VERSION ""
BS_:
BU_:

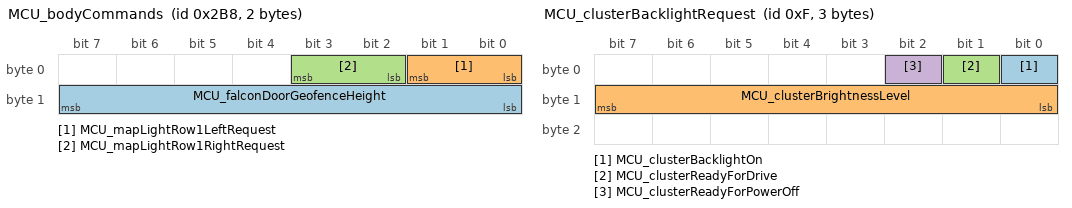
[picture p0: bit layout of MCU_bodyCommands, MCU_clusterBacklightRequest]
BO_ 696 MCU_bodyCommands: 2 ETH
 SG_ MCU_falconDoorGeofenceHeight: 8|8@1+ (1,0) [0|0] "cm" X
 SG_ MCU_mapLightRow1LeftRequest: 0|2@1+ (1,0) [0|0] "" X
 SG_ MCU_mapLightRow1RightRequest: 2|2@1+ (1,0) [0|0] "" X

BO_ 7 MCU_bodyControl: 8 ETH
 SG_ GTW_keyPollRequest: 44|1@1+ (1,0) [0|0] "" X
 SG_ GTW_parkingBrakesApplied: 0|1@1+ (1,0) [0|0] "" X
 SG_ MCU_UMCUpdateInhibit: 47|1@1+ (1,0) [0|0] "" X
 SG_ MCU_WCUpdateInhibit: 48|1@1+ (1,0) [0|0] "" X
 SG_ MCU_carInService: 12|1@1+ (1,0) [0|0] "" X
 SG_ MCU_chargeTerminationPct: 32|10@1+ (0.1,0) [0|0] "%" X
 SG_ MCU_chgMode: 18|3@1+ (1,0) [0|0] "" X
 SG_ MCU_clearDtcs: 13|1@1+ (1,0) [0|0] "" X
 SG_ MCU_domeLightReq: 16|2@1+ (1,0) [0|0] "" X
 SG_ MCU_espModeSwitch: 28|4@1+ (1,0) [0|0] "" X
 SG_ MCU_factoryMode: 5|1@1+ (1,0) [0|0] "" X
 SG_ MCU_frontFogSwitch: 6|1@1+ (1,0) [0|0] "" X
 SG_ MCU_lightSwitch: 2|2@1+ (1,0) [0|0] "" X
 SG_ MCU_pedalCalRxEnable: 15|1@1+ (1,0) [0|0] "" X
 SG_ MCU_pedalCalTargetCurve: 24|4@1+ (1,0) [0|0] "" X
 SG_ MCU_powerOff: 4|1@1+ (1,0) [0|0] "" X
 SG_ MCU_rearFogSwitch: 8|1@1+ (1,0) [0|0] "" X
 SG_ MCU_requestAcc: 1|1@1+ (1,0) [0|0] "" X
 SG_ MCU_requestCloseChargePortDoor: 42|1@1+ (1,0) [0|0] "" X
 SG_ MCU_requestDriveRail: 43|1@1+ (1,0) [0|0] "" X
 SG_ MCU_requestOpenChargePortDoor: 14|1@1+ (1,0) [0|0] "" X
 SG_ MCU_stop12VSupport: 7|1@1+ (1,0) [0|0] "" X
 SG_ UI_userPresent: 49|1@1+ (1,0) [0|0] "" X

BO_ 11 MCU_captureControl: 4 ETH
 SG_ MCU_captureBus: 8|8@1+ (1,0) [0|0] "" X
 SG_ MCU_captureMessage: 16|16@0+ (1,0) [0|0] "" X
 SG_ MCU_captureState: 0|8@1+ (1,0) [0|0] "" X

BO_ 80 MCU_chassisControl: 8 ETH
 SG_ MCU_accOvertakeEnable: 10|2@1+ (1,0) [0|0] "" X
 SG_ MCU_aebEnable: 14|2@1+ (1,0) [0|0] "" X
 SG_ MCU_aesEnable: 48|2@1+ (1,0) [0|0] "" X
 SG_ MCU_ahlbEnable: 18|2@1+ (1,0) [0|0] "" X
 SG_ MCU_autoLaneChangeEnable: 50|2@1+ (1,0) [0|0] "" X
 SG_ MCU_autoParkRequest: 26|4@1+ (1,0) [0|0] "" X
 SG_ MCU_bsdEnable: 16|2@1+ (1,0) [0|0] "" X
 SG_ MCU_chassisControlChecksum: 56|8@1+ (1,0) [0|0] "" X
 SG_ MCU_chassisControlCounter: 52|4@1+ (1,0) [0|0] "" X
 SG_ MCU_dasDebugEnable: 0|1@1+ (1,0) [0|0] "" X
 SG_ MCU_enableAutowipers: 35|1@1+ (1,0) [0|0] "" X
 SG_ MCU_enableCreepTorqueCH: 32|1@1+ (1,0) [0|0] "" X
 SG_ MCU_fcwEnable: 6|2@1+ (1,0) [0|0] "" X
 SG_ MCU_fcwSensitivity: 4|2@1+ (1,0) [0|0] "" X
 SG_ MCU_frontDefrostReq_das: 24|2@1+ (1,0) [0|0] "" X
 SG_ MCU_latControlEnable: 8|2@1+ (1,0) [0|0] "" X
 SG_ MCU_ldwEnable: 12|2@1+ (1,0) [0|0] "" X
 SG_ MCU_narrowGarages: 33|1@1+ (1,0) [0|0] "" X
 SG_ MCU_overPaintedUSS: 38|2@1+ (1,0) [0|0] "" X
 SG_ MCU_parkBrakeRequest: 1|2@1+ (1,0) [0|0] "" X
 SG_ MCU_parkSetting: 20|2@1+ (1,0) [0|0] "" X
 SG_ MCU_pedalSafetyEnable: 22|2@1+ (1,0) [0|0] "" X
 SG_ MCU_rebootAutopilot: 34|1@1+ (1,0) [0|0] "" X
 SG_ MCU_redLightStopSignEnable: 30|2@1+ (1,0) [0|0] "" X
 SG_ MCU_selfParkTune: 40|4@1+ (1,0) [0|0] "" X
 SG_ MCU_towModeEnable: 44|2@1+ (1,0) [0|0] "" X
 SG_ MCU_trailerModeCH: 3|1@1+ (1,0) [0|0] "" X
 SG_ MCU_zeroSpeedConfirmed: 46|2@1+ (1,0) [0|0] "" X

BO_ 107 MCU_cidTellTales: 1 ETH
 SG_ MCU_cidPassengerAirbagTellTale: 0|2@1+ (1,0) [0|0] "" X
 SG_ MCU_cidRearSeatbeltTellTale: 2|2@1+ (1,0) [0|0] "" X

BO_ 15 MCU_clusterBacklightRequest: 3 ETH
 SG_ MCU_clusterBacklightOn: 0|1@1+ (1,0) [0|0] "" X
 SG_ MCU_clusterBrightnessLevel: 8|8@1+ (0.5,0) [0|0] "%" X
 SG_ MCU_clusterReadyForDrive: 1|1@1+ (1,0) [0|0] "" X
 SG_ MCU_clusterReadyForPowerOff: 2|1@1+ (1,0) [0|0] "" X

BO_ 106 MCU_clusterTellTales: 5 ETH
 SG_ MCU_absTellTale: 0|2@1+ (1,0) [0|0] "" X
 SG_ MCU_afsTellTale: 36|2@1+ (1,0) [0|0] "" X
 SG_ MCU_airbagTellTale: 2|2@1+ (1,0) [0|0] "" X
 SG_ MCU_brakesTellTale: 4|2@1+ (1,0) [0|0] "" X
 SG_ MCU_doorsTellTale: 6|2@1+ (1,0) [0|0] "" X
 SG_ MCU_frontFogTellTale: 8|2@1+ (1,0) [0|0] "" X
 SG_ MCU_headlightTellTale: 10|2@1+ (1,0) [0|0] "" X
 SG_ MCU_highbeamTellTale: 12|2@1+ (1,0) [0|0] "" X
 SG_ MCU_parkBrakeRedTellTale: 14|2@1+ (1,0) [0|0] "" X
 SG_ MCU_parkBrakeYellowTellTale: 16|2@1+ (1,0) [0|0] "" X
 SG_ MCU_parkingLightTellTale: 18|2@1+ (1,0) [0|0] "" X
 SG_ MCU_passengerAirbagTellTale: 20|2@1+ (1,0) [0|0] "" X
 SG_ MCU_rearFogTellTale: 22|2@1+ (1,0) [0|0] "" X
 SG_ MCU_seatbeltAirbagTellTale: 24|2@1+ (1,0) [0|0] "" X
 SG_ MCU_suspensionRedTellTale: 26|2@1+ (1,0) [0|0] "" X
 SG_ MCU_suspensionYellowTellTale: 28|2@1+ (1,0) [0|0] "" X
 SG_ MCU_tpmsTellTale: 34|2@1+ (1,0) [0|0] "" X
 SG_ MCU_tractionControlOffTellTale: 30|2@1+ (1,0) [0|0] "" X
 SG_ MCU_tractionControlTellTale: 32|2@1+ (1,0) [0|0] "" X

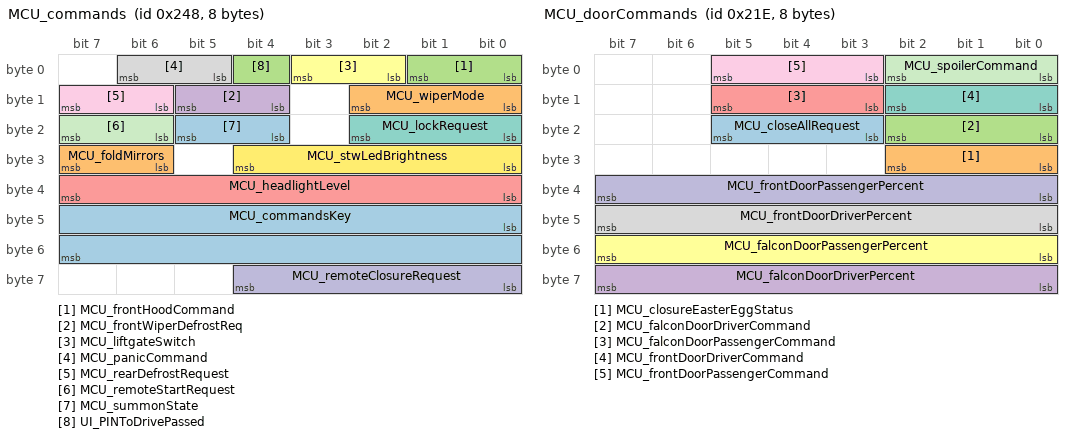
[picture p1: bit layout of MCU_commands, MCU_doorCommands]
BO_ 584 MCU_commands: 8 ETH
 SG_ MCU_commandsKey: 40|16@1+ (1,0) [0|0] "" X
 SG_ MCU_foldMirrors: 30|2@1+ (1,0) [0|0] "" X
 SG_ MCU_frontHoodCommand: 0|2@1+ (1,0) [0|0] "" X
 SG_ MCU_frontWiperDefrostReq: 12|2@1+ (1,0) [0|0] "" X
 SG_ MCU_headlightLevel: 32|8@1+ (1,0) [0|0] "" X
 SG_ MCU_liftgateSwitch: 2|2@1+ (1,0) [0|0] "" X
 SG_ MCU_lockRequest: 16|3@1+ (1,0) [0|0] "" X
 SG_ MCU_panicCommand: 5|2@1+ (1,0) [0|0] "" X
 SG_ MCU_rearDefrostRequest: 14|2@1+ (1,0) [0|0] "" X
 SG_ MCU_remoteClosureRequest: 56|5@1+ (1,0) [0|0] "" X
 SG_ MCU_remoteStartRequest: 22|2@1+ (1,0) [0|0] "" X
 SG_ MCU_stwLedBrightness: 24|5@1+ (1,0) [0|0] "" X
 SG_ MCU_summonState: 20|2@1+ (1,0) [0|0] "" X
 SG_ MCU_wiperMode: 8|3@1+ (1,0) [0|0] "" X
 SG_ UI_PINToDrivePassed: 4|1@1+ (1,0) [0|0] "" X

BO_ 8 MCU_controlFlags: 1 ETH
 SG_ MCU_requestTime: 5|1@1+ (1,0) [0|0] "" X
 SG_ MCU_turnOffFPGA: 0|1@1+ (1,0) [0|0] "" X

BO_ 2041 MCU_debugECU: 8 ETH
 SG_ MCU_debugEcuTarget M: 0|8@1+ (1,0) [0|0] "" X
 SG_ MCU_DI_debugEnable m1: 8|1@1+ (1,0) [0|0] "" X
 SG_ MCU_DIS_debugEnable m2: 8|1@1+ (1,0) [0|0] "" X
 SG_ MCU_PM_debugEnable m3: 8|1@1+ (1,0) [0|0] "" X
 SG_ MCU_PM_debugAt100Hz m3: 9|1@1+ (1,0) [0|0] "" X
 SG_ MCU_PMS_debugEnable m4: 8|1@1+ (1,0) [0|0] "" X
 SG_ MCU_PMS_debugAt100Hz m4: 9|1@1+ (1,0) [0|0] "" X

BO_ 2043 MCU_debugTas: 5 ETH
 SG_ MCU_debugTasTarget M: 0|8@1+ (1,0) [0|0] "" X
 SG_ MCU_TAS_damperControlOverride m0: 8|1@1+ (1,0) [0|0] "" X
 SG_ MCU_TAS_damperModeOverride m0: 9|1@1+ (1,0) [0|0] "" X
 SG_ MCU_TAS_damperCurrentOverride m0: 10|1@1+ (1,0) [0|0] "" X
 SG_ MCU_TAS_FLCompCurrentCommand m1: 8|8@1+ (0.01,0) [0|0] "A" X
 SG_ MCU_TAS_FLRebCurrentCommand m1: 16|8@1+ (0.01,0) [0|0] "A" X
 SG_ MCU_TAS_FRCompCurrentCommand m1: 24|8@1+ (0.01,0) [0|0] "A" X
 SG_ MCU_TAS_FRRebCurrentCommand m1: 32|8@1+ (0.01,0) [0|0] "A" X
 SG_ MCU_TAS_RLCompCurrentCommand m2: 8|8@1+ (0.01,0) [0|0] "A" X
 SG_ MCU_TAS_RLRebCurrentCommand m2: 16|8@1+ (0.01,0) [0|0] "A" X
 SG_ MCU_TAS_RRCompCurrentCommand m2: 24|8@1+ (0.01,0) [0|0] "A" X
 SG_ MCU_TAS_RRRebCurrentCommand m2: 32|8@1+ (0.01,0) [0|0] "A" X

BO_ 542 MCU_doorCommands: 8 ETH
 SG_ MCU_closeAllRequest: 19|3@1+ (1,0) [0|0] "" X
 SG_ MCU_closureEasterEggStatus: 24|3@1+ (1,0) [0|0] "" X
 SG_ MCU_falconDoorDriverCommand: 16|3@1+ (1,0) [0|0] "" X
 SG_ MCU_falconDoorDriverPercent: 56|8@1+ (0.5,0) [0|0] "%" X
 SG_ MCU_falconDoorPassengerCommand: 11|3@1+ (1,0) [0|0] "" X
 SG_ MCU_falconDoorPassengerPercent: 48|8@1+ (0.5,0) [0|0] "%" X
 SG_ MCU_frontDoorDriverCommand: 8|3@1+ (1,0) [0|0] "" X
 SG_ MCU_frontDoorDriverPercent: 40|8@1+ (0.5,0) [0|0] "%" X
 SG_ MCU_frontDoorPassengerCommand: 3|3@1+ (1,0) [0|0] "" X
 SG_ MCU_frontDoorPassengerPercent: 32|8@1+ (0.5,0) [0|0] "%" X
 SG_ MCU_spoilerCommand: 0|3@1+ (1,0) [0|0] "" X

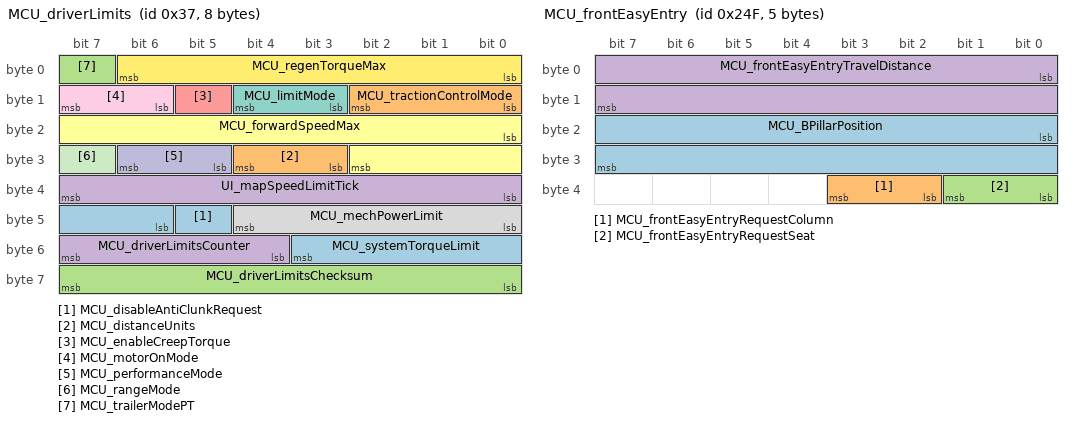
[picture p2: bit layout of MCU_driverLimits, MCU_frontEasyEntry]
BO_ 55 MCU_driverLimits: 8 ETH
 SG_ MCU_disableAntiClunkRequest: 45|1@1+ (1,0) [0|0] "" X
 SG_ MCU_distanceUnits: 27|2@1+ (1,0) [0|0] "" X
 SG_ MCU_driverLimitsChecksum: 56|8@1+ (1,0) [0|0] "" X
 SG_ MCU_driverLimitsCounter: 52|4@1+ (1,0) [0|0] "" X
 SG_ MCU_enableCreepTorque: 13|1@1+ (1,0) [0|0] "" X
 SG_ MCU_forwardSpeedMax: 16|11@1+ (0.1,0) [0|0] "MPH" X
 SG_ MCU_limitMode: 11|2@1+ (1,0) [0|0] "" X
 SG_ MCU_mechPowerLimit: 40|5@1+ (20,20) [0|0] "kW" X
 SG_ MCU_motorOnMode: 14|2@1+ (1,0) [0|0] "" X
 SG_ MCU_performanceMode: 29|2@1+ (1,0) [0|0] "" X
 SG_ MCU_rangeMode: 31|1@1+ (1,0) [0|0] "" X
 SG_ MCU_regenTorqueMax: 0|7@1+ (0.8,0) [0|0] "%" X
 SG_ MCU_systemTorqueLimit: 46|6@1+ (15,400) [0|0] "Nm" X
 SG_ MCU_tractionControlMode: 8|3@1+ (1,0) [0|0] "" X
 SG_ MCU_trailerModePT: 7|1@1+ (1,0) [0|0] "" X
 SG_ UI_mapSpeedLimitTick: 32|8@1+ (1,0) [0|0] "" X

BO_ 24 MCU_ethernetControl: 1 ETH
 SG_ MCU_enableExtEth: 0|1@1+ (1,0) [0|0] "" X

BO_ 591 MCU_frontEasyEntry: 5 ETH
 SG_ MCU_BPillarPosition: 16|16@1- (1,0) [0|0] "" X
 SG_ MCU_frontEasyEntryRequestColumn: 34|2@1+ (1,0) [0|0] "" X
 SG_ MCU_frontEasyEntryRequestSeat: 32|2@1+ (1,0) [0|0] "" X
 SG_ MCU_frontEasyEntryTravelDistance: 0|16@1- (1,0) [0|0] "" X

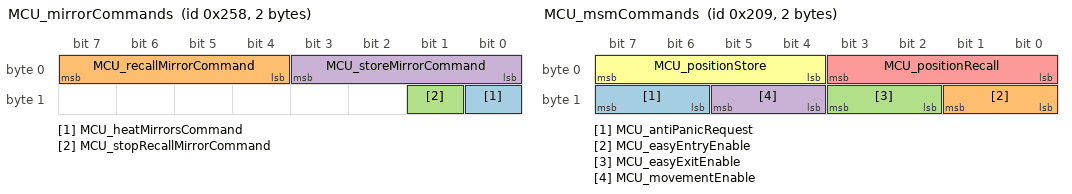
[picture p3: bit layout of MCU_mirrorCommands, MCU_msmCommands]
BO_ 600 MCU_mirrorCommands: 2 ETH
 SG_ MCU_heatMirrorsCommand: 8|1@1+ (1,0) [0|0] "" X
 SG_ MCU_recallMirrorCommand: 4|4@1+ (1,0) [0|0] "" X
 SG_ MCU_stopRecallMirrorCommand: 9|1@1+ (1,0) [0|0] "" X
 SG_ MCU_storeMirrorCommand: 0|4@1+ (1,0) [0|0] "" X

BO_ 70 MCU_miscControl: 8 ETH
 SG_ MCU_bccenReset: 15|1@1+ (1,0) [0|0] "" X
 SG_ MCU_bccenResetMask: 47|1@1+ (1,0) [0|0] "" X
 SG_ MCU_bcfalcdReset: 16|1@1+ (1,0) [0|0] "" X
 SG_ MCU_bcfalcdResetMask: 48|1@1+ (1,0) [0|0] "" X
 SG_ MCU_bcfalcpReset: 17|1@1+ (1,0) [0|0] "" X
 SG_ MCU_bcfalcpResetMask: 49|1@1+ (1,0) [0|0] "" X
 SG_ MCU_bcfdmReset: 18|1@1+ (1,0) [0|0] "" X
 SG_ MCU_bcfdmResetMask: 50|1@1+ (1,0) [0|0] "" X
 SG_ MCU_bcfpmReset: 19|1@1+ (1,0) [0|0] "" X
 SG_ MCU_bcfpmResetMask: 51|1@1+ (1,0) [0|0] "" X
 SG_ MCU_bcs2cReset: 20|1@1+ (1,0) [0|0] "" X
 SG_ MCU_bcs2cResetMask: 52|1@1+ (1,0) [0|0] "" X
 SG_ MCU_bcs2lReset: 21|1@1+ (1,0) [0|0] "" X
 SG_ MCU_bcs2lResetMask: 53|1@1+ (1,0) [0|0] "" X
 SG_ MCU_bcs2rReset: 22|1@1+ (1,0) [0|0] "" X
 SG_ MCU_bcs2rResetMask: 54|1@1+ (1,0) [0|0] "" X
 SG_ MCU_cameraPower: 3|1@1+ (1,0) [0|0] "" X
 SG_ MCU_cameraPowerMask: 35|1@1+ (1,0) [0|0] "" X
 SG_ MCU_cellModemPower: 0|1@1+ (1,0) [0|0] "" X
 SG_ MCU_cellModemPowerMask: 32|1@1+ (1,0) [0|0] "" X
 SG_ MCU_cellOnOff: 7|1@1+ (1,0) [0|0] "" X
 SG_ MCU_cellOnOffMask: 39|1@1+ (1,0) [0|0] "" X
 SG_ MCU_cellPower: 5|1@1+ (1,0) [0|0] "" X
 SG_ MCU_cellPowerMask: 37|1@1+ (1,0) [0|0] "" X
 SG_ MCU_cellReset: 6|1@1+ (1,0) [0|0] "" X
 SG_ MCU_cellResetMask: 38|1@1+ (1,0) [0|0] "" X
 SG_ MCU_chgReset: 13|1@1+ (1,0) [0|0] "" X
 SG_ MCU_chgResetMask: 45|1@1+ (1,0) [0|0] "" X
 SG_ MCU_dasReset: 23|1@1+ (1,0) [0|0] "" X
 SG_ MCU_dasResetMask: 55|1@1+ (1,0) [0|0] "" X
 SG_ MCU_ddmReset: 11|1@1+ (1,0) [0|0] "" X
 SG_ MCU_ddmResetMask: 43|1@1+ (1,0) [0|0] "" X
 SG_ MCU_fpgaReset: 4|1@1+ (1,0) [0|0] "" X
 SG_ MCU_fpgaResetMask: 36|1@1+ (1,0) [0|0] "" X
 SG_ MCU_parrotBoots: 1|1@1+ (1,0) [0|0] "" X
 SG_ MCU_parrotBootsMask: 33|1@1+ (1,0) [0|0] "" X
 SG_ MCU_parrotReset: 2|1@1+ (1,0) [0|0] "" X
 SG_ MCU_parrotResetMask: 34|1@1+ (1,0) [0|0] "" X
 SG_ MCU_pdmReset: 12|1@1+ (1,0) [0|0] "" X
 SG_ MCU_pdmResetMask: 44|1@1+ (1,0) [0|0] "" X
 SG_ MCU_requestPowerOff: 8|1@1+ (1,0) [0|0] "" X
 SG_ MCU_requestPowerOffMask: 40|1@1+ (1,0) [0|0] "" X
 SG_ MCU_secReset: 10|1@1+ (1,0) [0|0] "" X
 SG_ MCU_secResetMask: 42|1@1+ (1,0) [0|0] "" X
 SG_ MCU_touchPower: 9|1@1+ (1,0) [0|0] "" X
 SG_ MCU_touchPowerMask: 41|1@1+ (1,0) [0|0] "" X
 SG_ MCU_usbPower: 14|1@1+ (1,0) [0|0] "" X
 SG_ MCU_usbPowerMask: 46|1@1+ (1,0) [0|0] "" X

BO_ 521 MCU_msmCommands: 2 ETH
 SG_ MCU_antiPanicRequest: 14|2@1+ (1,0) [0|0] "" X
 SG_ MCU_easyEntryEnable: 8|2@1+ (1,0) [0|0] "" X
 SG_ MCU_easyExitEnable: 10|2@1+ (1,0) [0|0] "" X
 SG_ MCU_movementEnable: 12|2@1+ (1,0) [0|0] "" X
 SG_ MCU_positionRecall: 0|4@1+ (1,0) [0|0] "" X
 SG_ MCU_positionStore: 4|4@1+ (1,0) [0|0] "" X

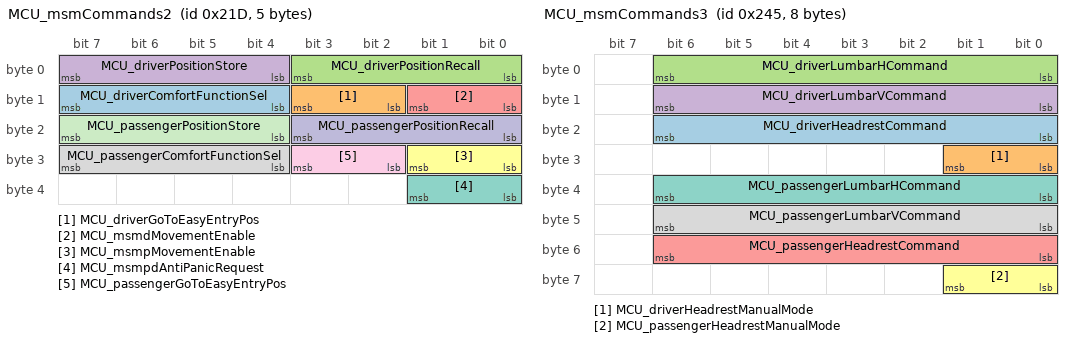
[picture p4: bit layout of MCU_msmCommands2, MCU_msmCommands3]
BO_ 541 MCU_msmCommands2: 5 ETH
 SG_ MCU_driverComfortFunctionSel: 12|4@1+ (1,0) [0|0] "" X
 SG_ MCU_driverGoToEasyEntryPos: 10|2@1+ (1,0) [0|0] "" X
 SG_ MCU_driverPositionRecall: 0|4@1+ (1,0) [0|0] "" X
 SG_ MCU_driverPositionStore: 4|4@1+ (1,0) [0|0] "" X
 SG_ MCU_msmdMovementEnable: 8|2@1+ (1,0) [0|0] "" X
 SG_ MCU_msmpMovementEnable: 24|2@1+ (1,0) [0|0] "" X
 SG_ MCU_msmpdAntiPanicRequest: 32|2@1+ (1,0) [0|0] "" X
 SG_ MCU_passengerComfortFunctionSel: 28|4@1+ (1,0) [0|0] "" X
 SG_ MCU_passengerGoToEasyEntryPos: 26|2@1+ (1,0) [0|0] "" X
 SG_ MCU_passengerPositionRecall: 16|4@1+ (1,0) [0|0] "" X
 SG_ MCU_passengerPositionStore: 20|4@1+ (1,0) [0|0] "" X

BO_ 581 MCU_msmCommands3: 8 ETH
 SG_ MCU_driverHeadrestCommand: 16|7@1+ (1,0) [0|0] "%" X
 SG_ MCU_driverHeadrestManualMode: 24|2@1+ (1,0) [0|0] "" X
 SG_ MCU_driverLumbarHCommand: 0|7@1+ (1,0) [0|0] "%" X
 SG_ MCU_driverLumbarVCommand: 8|7@1+ (1,0) [0|0] "%" X
 SG_ MCU_passengerHeadrestCommand: 48|7@1+ (1,0) [0|0] "%" X
 SG_ MCU_passengerHeadrestManualMode: 56|2@1+ (1,0) [0|0] "" X
 SG_ MCU_passengerLumbarHCommand: 32|7@1+ (1,0) [0|0] "%" X
 SG_ MCU_passengerLumbarVCommand: 40|7@1+ (1,0) [0|0] "%" X

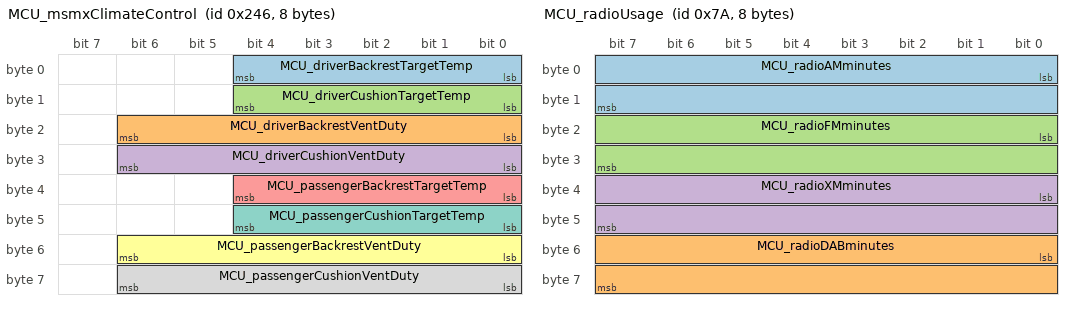
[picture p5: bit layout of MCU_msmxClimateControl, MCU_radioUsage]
BO_ 582 MCU_msmxClimateControl: 8 ETH
 SG_ MCU_driverBackrestTargetTemp: 0|5@1+ (1,22) [0|0] "C" X
 SG_ MCU_driverBackrestVentDuty: 16|7@1+ (1,0) [0|0] "%" X
 SG_ MCU_driverCushionTargetTemp: 8|5@1+ (1,22) [0|0] "C" X
 SG_ MCU_driverCushionVentDuty: 24|7@1+ (1,0) [0|0] "%" X
 SG_ MCU_passengerBackrestTargetTemp: 32|5@1+ (1,22) [0|0] "C" X
 SG_ MCU_passengerBackrestVentDuty: 48|7@1+ (1,0) [0|0] "%" X
 SG_ MCU_passengerCushionTargetTemp: 40|5@1+ (1,22) [0|0] "C" X
 SG_ MCU_passengerCushionVentDuty: 56|7@1+ (1,0) [0|0] "%" X

BO_ 137 MCU_networkUsageFileSync: 8 ETH

BO_ 112 MCU_networkUsageMapSearch: 8 ETH

BO_ 111 MCU_networkUsageMapTiles: 8 ETH

BO_ 108 MCU_networkUsageOther: 8 ETH

BO_ 124 MCU_networkUsageRdio: 8 ETH

BO_ 109 MCU_networkUsageSlacker: 8 ETH

BO_ 110 MCU_networkUsageTuneIn: 8 ETH

BO_ 114 MCU_newtworkUsageBrowser: 8 ETH

BO_ 118 MCU_newtworkUsageCarLogs: 8 ETH

BO_ 117 MCU_newtworkUsageFirmware: 8 ETH

BO_ 113 MCU_newtworkUsageGracenote: 8 ETH

BO_ 116 MCU_newtworkUsageImages: 8 ETH

BO_ 121 MCU_newtworkUsageMapTraffic: 8 ETH

BO_ 119 MCU_newtworkUsageMobileApp: 8 ETH

BO_ 120 MCU_newtworkUsageMothership: 8 ETH

BO_ 115 MCU_newtworkUsageVoiceRec: 8 ETH

BO_ 61 MCU_odometerStatus: 4 ETH
 SG_ MCU_odometer: 0|32@1+ (0.001,0) [0|0] "mi" X

BO_ 952 MCU_power: 2 ETH
 SG_ MCU_powerExpected: 0|8@1+ (1,0) [0|0] "kW" X
 SG_ MCU_powerIdeal: 8|8@1+ (1,0) [0|0] "kW" X

BO_ 122 MCU_radioUsage: 8 ETH
 SG_ MCU_radioAMminutes: 0|16@1+ (10,0) [0|0] "minutes" X
 SG_ MCU_radioDABminutes: 48|16@1+ (10,0) [0|0] "minutes" X
 SG_ MCU_radioFMminutes: 16|16@1+ (10,0) [0|0] "minutes" X
 SG_ MCU_radioXMminutes: 32|16@1+ (10,0) [0|0] "minutes" X

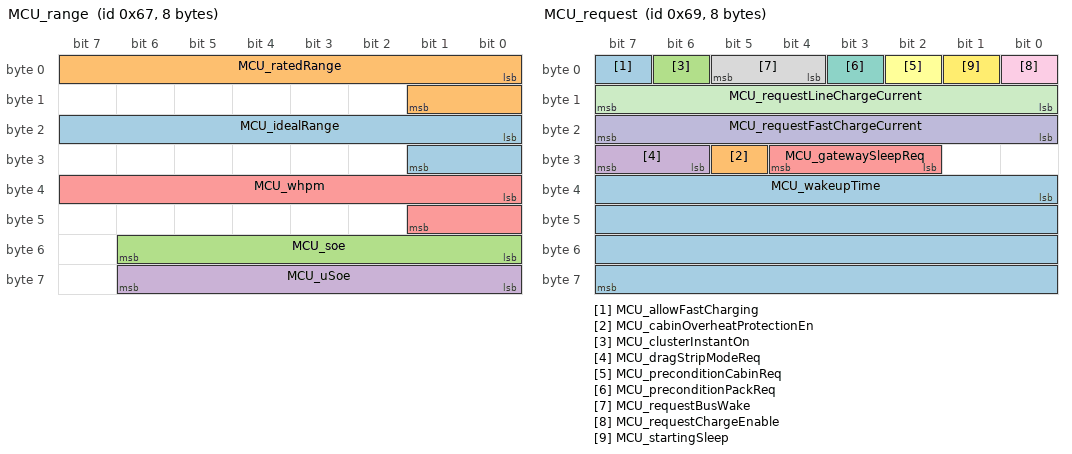
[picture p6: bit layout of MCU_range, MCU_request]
BO_ 103 MCU_range: 8 ETH
 SG_ MCU_idealRange: 16|10@1+ (1,0) [0|0] "mi" X
 SG_ MCU_ratedRange: 0|10@1+ (1,0) [0|0] "mi" X
 SG_ MCU_soe: 48|7@1+ (1,0) [0|0] "%" X
 SG_ MCU_uSoe: 56|7@1+ (1,0) [0|0] "%" X
 SG_ MCU_whpm: 32|10@1+ (1,0) [0|0] "whpm" X

BO_ 105 MCU_request: 8 ETH
 SG_ MCU_allowFastCharging: 7|1@1+ (1,0) [0|0] "" X
 SG_ MCU_cabinOverheatProtectionEn: 29|1@1+ (1,0) [0|0] "" X
 SG_ MCU_clusterInstantOn: 6|1@1+ (1,0) [0|0] "" X
 SG_ MCU_dragStripModeReq: 30|2@1+ (1,0) [0|0] "" X
 SG_ MCU_gatewaySleepReq: 26|3@1+ (1,0) [0|0] "" X
 SG_ MCU_preconditionCabinReq: 2|1@1+ (1,0) [0|0] "" X
 SG_ MCU_preconditionPackReq: 3|1@1+ (1,0) [0|0] "" X
 SG_ MCU_requestBusWake: 4|2@1+ (1,0) [0|0] "" X
 SG_ MCU_requestChargeEnable: 0|1@1+ (1,0) [0|0] "" X
 SG_ MCU_requestFastChargeCurrent: 16|8@1+ (1,0) [0|0] "A" X
 SG_ MCU_requestLineChargeCurrent: 8|8@1+ (1,0) [0|0] "A" X
 SG_ MCU_startingSleep: 1|1@1+ (1,0) [0|0] "" X
 SG_ MCU_wakeupTime: 32|32@1+ (1,0) [0|0] "" X

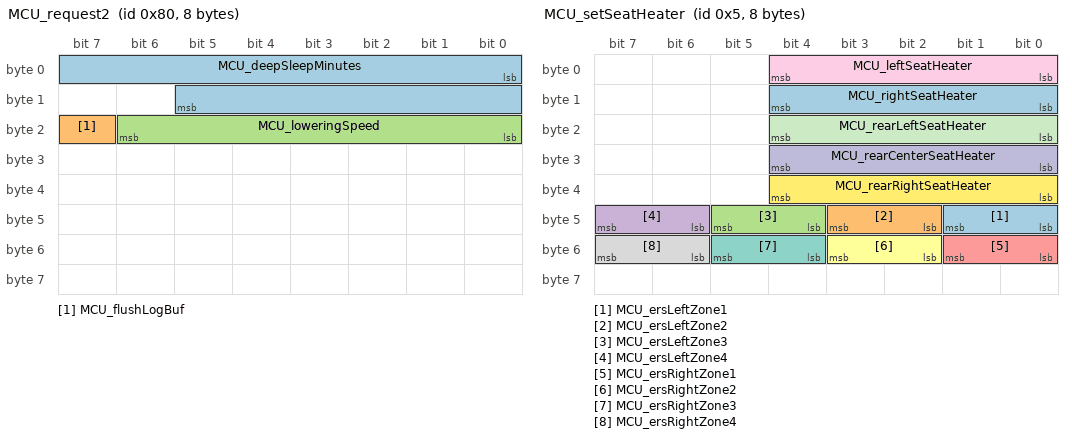
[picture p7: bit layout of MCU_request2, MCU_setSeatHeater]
BO_ 128 MCU_request2: 8 ETH
 SG_ MCU_deepSleepMinutes: 0|14@1+ (1,0) [0|0] "" X
 SG_ MCU_flushLogBuf: 23|1@1+ (1,0) [0|0] "" X
 SG_ MCU_loweringSpeed: 16|7@1+ (1,0) [0|0] "mph" X

BO_ 5 MCU_setSeatHeater: 8 ETH
 SG_ MCU_ersLeftZone1: 40|2@1+ (1,0) [0|0] "" X
 SG_ MCU_ersLeftZone2: 42|2@1+ (1,0) [0|0] "" X
 SG_ MCU_ersLeftZone3: 44|2@1+ (1,0) [0|0] "" X
 SG_ MCU_ersLeftZone4: 46|2@1+ (1,0) [0|0] "" X
 SG_ MCU_ersRightZone1: 48|2@1+ (1,0) [0|0] "" X
 SG_ MCU_ersRightZone2: 50|2@1+ (1,0) [0|0] "" X
 SG_ MCU_ersRightZone3: 52|2@1+ (1,0) [0|0] "" X
 SG_ MCU_ersRightZone4: 54|2@1+ (1,0) [0|0] "" X
 SG_ MCU_leftSeatHeater: 0|5@1+ (1,0) [0|0] "" X
 SG_ MCU_rearCenterSeatHeater: 24|5@1+ (1,0) [0|0] "" X
 SG_ MCU_rearLeftSeatHeater: 16|5@1+ (1,0) [0|0] "" X
 SG_ MCU_rearRightSeatHeater: 32|5@1+ (1,0) [0|0] "" X
 SG_ MCU_rightSeatHeater: 8|5@1+ (1,0) [0|0] "" X

BO_ 9 MCU_setTime: 6 ETH
 SG_ MCU_timeSecs: 0|32@1+ (1,0) [0|0] "" X
 SG_ MCU_timeZoneMinutes: 32|11@1- (1,0) [0|0] "" X

BO_ 520 MCU_sunCommandRequest: 8 ETH
 SG_ MCU_sunCommand: 0|3@1+ (1,0) [0|0] "" X
 SG_ MCU_sunTargetPercentOpen: 8|8@1+ (0.5,0) [0|0] "%" X

BO_ 133 MCU_tpmsC: 8 ETH
 SG_ MCU_setRcpFront: 16|8@1+ (0.025,0) [0|0] "bar" X
 SG_ MCU_setRcpRear: 24|8@1+ (0.025,0) [0|0] "bar" X

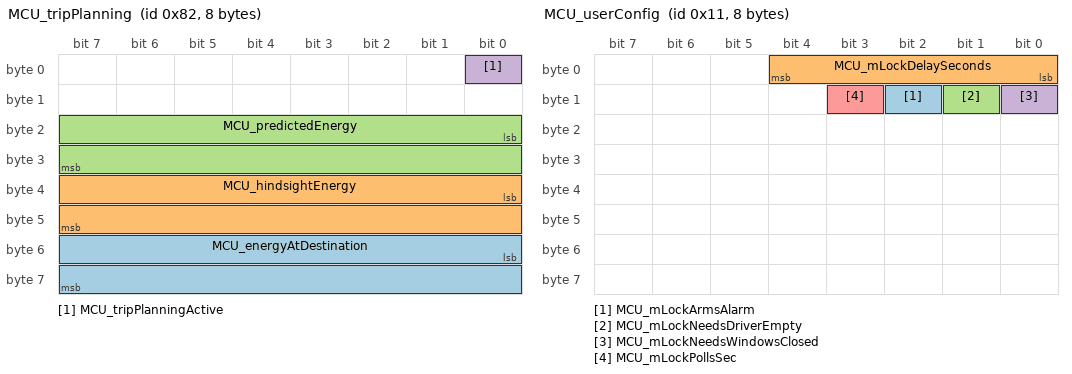
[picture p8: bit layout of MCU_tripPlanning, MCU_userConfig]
BO_ 130 MCU_tripPlanning: 8 ETH
 SG_ MCU_energyAtDestination: 48|16@1- (0.01,0) [0|0] "kWh" X
 SG_ MCU_hindsightEnergy: 32|16@1- (0.01,0) [0|0] "kWh" X
 SG_ MCU_predictedEnergy: 16|16@1- (0.01,0) [0|0] "kWh" X
 SG_ MCU_tripPlanningActive: 0|1@1+ (1,0) [0|0] "" X

BO_ 139 MCU_tripPlanning2: 4 ETH
 SG_ MCU_maxSpeedToReachDestination: 0|16@1+ (0.01,0) [0|0] "mps" X
 SG_ MCU_remainingWeightedRMSSpeed: 16|16@1+ (0.01,0) [0|0] "mps" X

BO_ 1416 MCU_tunerFlowControl: 3 ETH
 SG_ MCU_tunerFlowBlocks: 8|8@1+ (1,0) [0|0] "" X
 SG_ MCU_tunerFlowInterval: 16|8@1+ (1,0) [0|0] "" X
 SG_ MCU_tunerFlowType: 0|8@1+ (1,0) [0|0] "" X

BO_ 17 MCU_userConfig: 8 ETH
 SG_ MCU_mLockArmsAlarm: 10|1@1+ (1,0) [0|0] "" X
 SG_ MCU_mLockDelaySeconds: 0|5@1+ (1,0) [0|0] "" X
 SG_ MCU_mLockNeedsDriverEmpty: 9|1@1+ (1,0) [0|0] "" X
 SG_ MCU_mLockNeedsWindowsClosed: 8|1@1+ (1,0) [0|0] "" X
 SG_ MCU_mLockPollsSec: 11|1@1+ (1,0) [0|0] "" X

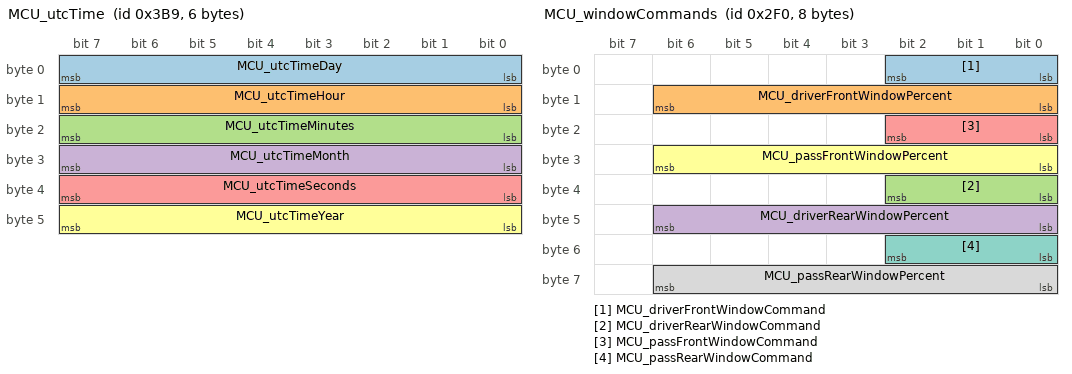
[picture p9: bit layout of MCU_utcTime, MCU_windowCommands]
BO_ 953 MCU_utcTime: 6 ETH
 SG_ MCU_utcTimeDay: 0|8@1+ (0.25,0) [0|0] "days" X
 SG_ MCU_utcTimeHour: 8|8@1+ (1,0) [0|0] "hours" X
 SG_ MCU_utcTimeMinutes: 16|8@1+ (1,0) [0|0] "minutes" X
 SG_ MCU_utcTimeMonth: 24|8@1+ (1,0) [0|0] "Months" X
 SG_ MCU_utcTimeSeconds: 32|8@1+ (0.25,0) [0|0] "seconds" X
 SG_ MCU_utcTimeYear: 40|8@1+ (1,1985) [0|0] "Years" X

BO_ 752 MCU_windowCommands: 8 ETH
 SG_ MCU_driverFrontWindowCommand: 0|3@1+ (1,0) [0|0] "" X
 SG_ MCU_driverFrontWindowPercent: 8|7@1+ (1,0) [0|0] "" X
 SG_ MCU_driverRearWindowCommand: 32|3@1+ (1,0) [0|0] "" X
 SG_ MCU_driverRearWindowPercent: 40|7@1+ (1,0) [0|0] "" X
 SG_ MCU_passFrontWindowCommand: 16|3@1+ (1,0) [0|0] "" X
 SG_ MCU_passFrontWindowPercent: 24|7@1+ (1,0) [0|0] "" X
 SG_ MCU_passRearWindowCommand: 48|3@1+ (1,0) [0|0] "" X
 SG_ MCU_passRearWindowPercent: 56|7@1+ (1,0) [0|0] "" X

BO_ 758 MSMD_seatPos: 8 ETH
 SG_ MSMD_backrestPosition: 32|16@1- (1,0) [0|0] "" X
 SG_ MSMD_liftPosition: 16|16@1- (1,0) [0|0] "" X
 SG_ MSMD_slidePosition: 0|16@1- (1,0) [0|0] "" X
 SG_ MSMD_tiltPosition: 48|16@1- (1,0) [0|0] "" X

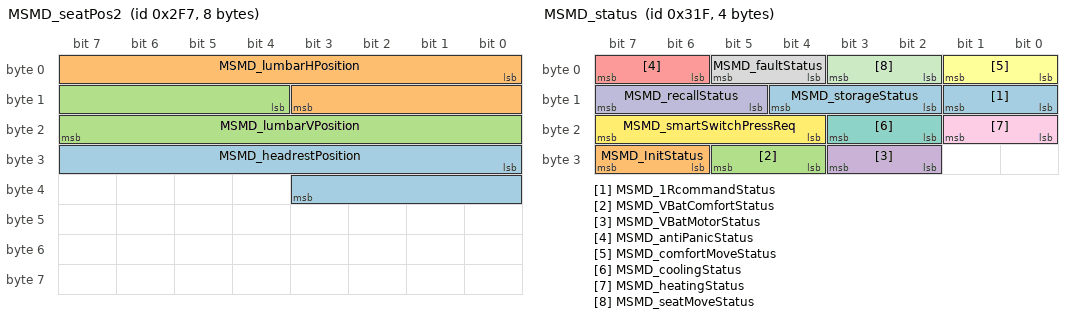
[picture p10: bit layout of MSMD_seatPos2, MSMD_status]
BO_ 759 MSMD_seatPos2: 8 ETH
 SG_ MSMD_headrestPosition: 24|12@1- (1,0) [0|0] "" X
 SG_ MSMD_lumbarHPosition: 0|12@1- (1,0) [0|0] "" X
 SG_ MSMD_lumbarVPosition: 12|12@1- (1,0) [0|0] "" X

BO_ 799 MSMD_status: 4 ETH
 SG_ MSMD_1RcommandStatus: 8|2@1+ (1,0) [0|0] "" X
 SG_ MSMD_InitStatus: 30|2@1+ (1,0) [0|0] "" X
 SG_ MSMD_VBatComfortStatus: 28|2@1+ (1,0) [0|0] "" X
 SG_ MSMD_VBatMotorStatus: 26|2@1+ (1,0) [0|0] "" X
 SG_ MSMD_antiPanicStatus: 6|2@1+ (1,0) [0|0] "" X
 SG_ MSMD_comfortMoveStatus: 0|2@1+ (1,0) [0|0] "" X
 SG_ MSMD_coolingStatus: 18|2@1+ (1,0) [0|0] "" X
 SG_ MSMD_faultStatus: 4|2@1+ (1,0) [0|0] "" X
 SG_ MSMD_heatingStatus: 16|2@1+ (1,0) [0|0] "" X
 SG_ MSMD_recallStatus: 13|3@1+ (1,0) [0|0] "" X
 SG_ MSMD_seatMoveStatus: 2|2@1+ (1,0) [0|0] "" X
 SG_ MSMD_smartSwitchPressReq: 20|4@1+ (1,0) [0|0] "" X
 SG_ MSMD_storageStatus: 10|3@1+ (1,0) [0|0] "" X

BO_ 2026 MSMD_udsResponse: 8 ETH
 SG_ MSMD_udsResponseData: 0|54@0+ (1024,0) [0|0] "" X

BO_ 755 MSMP_seatPos: 8 ETH
 SG_ MSMP_backrestPosition: 32|16@1- (1,0) [0|0] "" X
 SG_ MSMP_liftPosition: 16|16@1- (1,0) [0|0] "" X
 SG_ MSMP_slidePosition: 0|16@1- (1,0) [0|0] "" X
 SG_ MSMP_tiltPosition: 48|16@1- (1,0) [0|0] "" X

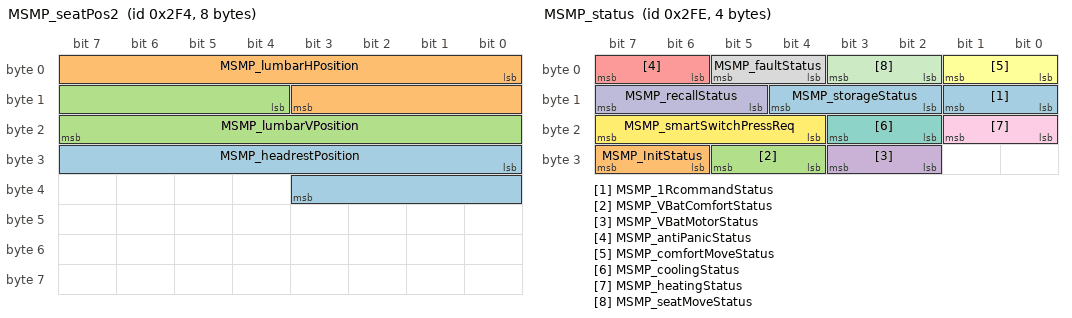
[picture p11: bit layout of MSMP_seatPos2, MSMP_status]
BO_ 756 MSMP_seatPos2: 8 ETH
 SG_ MSMP_headrestPosition: 24|12@1- (1,0) [0|0] "" X
 SG_ MSMP_lumbarHPosition: 0|12@1- (1,0) [0|0] "" X
 SG_ MSMP_lumbarVPosition: 12|12@1- (1,0) [0|0] "" X

BO_ 766 MSMP_status: 4 ETH
 SG_ MSMP_1RcommandStatus: 8|2@1+ (1,0) [0|0] "" X
 SG_ MSMP_InitStatus: 30|2@1+ (1,0) [0|0] "" X
 SG_ MSMP_VBatComfortStatus: 28|2@1+ (1,0) [0|0] "" X
 SG_ MSMP_VBatMotorStatus: 26|2@1+ (1,0) [0|0] "" X
 SG_ MSMP_antiPanicStatus: 6|2@1+ (1,0) [0|0] "" X
 SG_ MSMP_comfortMoveStatus: 0|2@1+ (1,0) [0|0] "" X
 SG_ MSMP_coolingStatus: 18|2@1+ (1,0) [0|0] "" X
 SG_ MSMP_faultStatus: 4|2@1+ (1,0) [0|0] "" X
 SG_ MSMP_heatingStatus: 16|2@1+ (1,0) [0|0] "" X
 SG_ MSMP_recallStatus: 13|3@1+ (1,0) [0|0] "" X
 SG_ MSMP_seatMoveStatus: 2|2@1+ (1,0) [0|0] "" X
 SG_ MSMP_smartSwitchPressReq: 20|4@1+ (1,0) [0|0] "" X
 SG_ MSMP_storageStatus: 10|3@1+ (1,0) [0|0] "" X

BO_ 2027 MSMP_udsResponse: 8 ETH
 SG_ MSMP_udsResponseData: 0|54@0+ (1024,0) [0|0] "" X

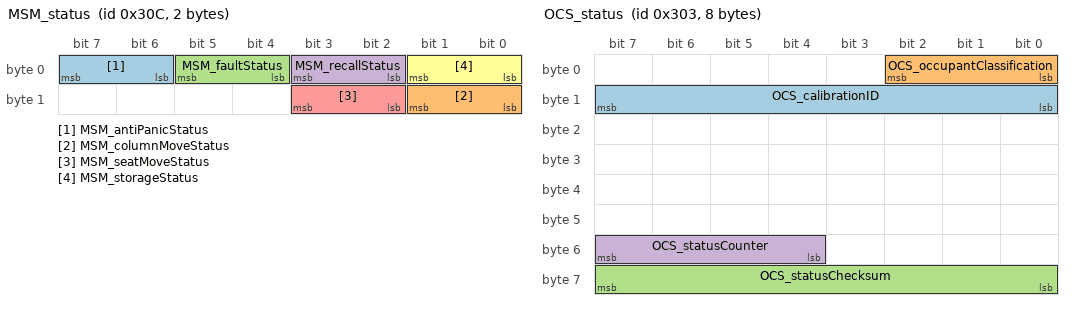
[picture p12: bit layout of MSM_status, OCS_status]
BO_ 780 MSM_status: 2 ETH
 SG_ MSM_antiPanicStatus: 6|2@1+ (1,0) [0|0] "" X
 SG_ MSM_columnMoveStatus: 8|2@1+ (1,0) [0|0] "" X
 SG_ MSM_faultStatus: 4|2@1+ (1,0) [0|0] "" X
 SG_ MSM_recallStatus: 2|2@1+ (1,0) [0|0] "" X
 SG_ MSM_seatMoveStatus: 10|2@1+ (1,0) [0|0] "" X
 SG_ MSM_storageStatus: 0|2@1+ (1,0) [0|0] "" X

BO_ 1756 MSM_udsResponse: 8 ETH
 SG_ MSM_udsResponseData: 0|54@0+ (1024,0) [0|0] "" X

BO_ 1501 MSM_version: 4 ETH
 SG_ MSMP_versionMajor: 16|8@1+ (1,0) [0|0] "" X
 SG_ MSMP_versionMinor: 24|8@1+ (1,0) [0|0] "" X
 SG_ MSM_versionMajor: 0|8@1+ (1,0) [0|0] "" X
 SG_ MSM_versionMinor: 8|8@1+ (1,0) [0|0] "" X

BO_ 847 OCS1: 2 ETH
 SG_ OCS_calibID: 8|8@1+ (1,0) [0|0] "" X
 SG_ OCS_occupantClass: 0|3@1+ (1,0) [0|0] "" X
 SG_ OCS_sdmSerialNoReceived: 4|1@1+ (1,0) [0|0] "" X

BO_ 771 OCS_status: 8 ETH
 SG_ OCS_calibrationID: 8|8@1+ (1,0) [0|0] "" X
 SG_ OCS_occupantClassification: 0|3@1+ (1,0) [0|0] "" X
 SG_ OCS_statusChecksum: 56|8@1+ (1,0) [0|0] "" X
 SG_ OCS_statusCounter: 52|4@1+ (1,0) [0|0] "" X

BO_ 1619 OCS_udsResponse: 8 ETH
 SG_ OCS_udsResponseData: 0|54@0+ (1024,0) [0|0] "" X

BO_ 1504 OCS_version: 4 ETH
 SG_ OCS_appVersion0: 0|8@1+ (1,0) [0|0] "" X
 SG_ OCS_appVersion1: 8|8@1+ (1,0) [0|0] "" X
 SG_ OCS_calVersion0: 16|8@1+ (1,0) [0|0] "" X
 SG_ OCS_calVersion1: 24|8@1+ (1,0) [0|0] "" X

BO_ 910 PARK3_userMatrix: 8 ETH
 SG_ PARK3_u000_s1_blocked: 0|1@1+ (1,0) [0|0] "" X
 SG_ PARK3_u001_s2_blocked: 1|1@1+ (1,0) [0|0] "" X
 SG_ PARK3_u002_s3_blocked: 2|1@1+ (1,0) [0|0] "" X
 SG_ PARK3_u003_s4_blocked: 3|1@1+ (1,0) [0|0] "" X
 SG_ PARK3_u004_s5_blocked: 4|1@1+ (1,0) [0|0] "" X
 SG_ PARK3_u005_s6_blocked: 5|1@1+ (1,0) [0|0] "" X
 SG_ PARK3_u006_s7_blocked: 6|1@1+ (1,0) [0|0] "" X
 SG_ PARK3_u007_s8_blocked: 7|1@1+ (1,0) [0|0] "" X
 SG_ PARK3_u008_s9_blocked: 8|1@1+ (1,0) [0|0] "" X
 SG_ PARK3_u009_s10_blocked: 9|1@1+ (1,0) [0|0] "" X
 SG_ PARK3_u010_s11_blocked: 10|1@1+ (1,0) [0|0] "" X
 SG_ PARK3_u011_s12_blocked: 11|1@1+ (1,0) [0|0] "" X
 SG_ PARK3_u012_s1_crossTalk: 12|1@1+ (1,0) [0|0] "" X
 SG_ PARK3_u013_s2_crossTalk: 13|1@1+ (1,0) [0|0] "" X
 SG_ PARK3_u014_s3_crossTalk: 14|1@1+ (1,0) [0|0] "" X
 SG_ PARK3_u015_s4_crossTalk: 15|1@1+ (1,0) [0|0] "" X
 SG_ PARK3_u016_s5_crossTalk: 16|1@1+ (1,0) [0|0] "" X
 SG_ PARK3_u017_s6_crossTalk: 17|1@1+ (1,0) [0|0] "" X
 SG_ PARK3_u018_s7_crossTalk: 18|1@1+ (1,0) [0|0] "" X
 SG_ PARK3_u019_s8_crossTalk: 19|1@1+ (1,0) [0|0] "" X
 SG_ PARK3_u020_s9_crossTalk: 20|1@1+ (1,0) [0|0] "" X
 SG_ PARK3_u021_s10_crossTalk: 21|1@1+ (1,0) [0|0] "" X
 SG_ PARK3_u022_s11_crossTalk: 22|1@1+ (1,0) [0|0] "" X
 SG_ PARK3_u023_s12_crossTalk: 23|1@1+ (1,0) [0|0] "" X

BO_ 894 PARK3_warningMatrix: 8 ETH
 SG_ PARK3_w000_s1_overTemp: 0|1@1+ (1,0) [0|0] "" X
 SG_ PARK3_w001_s1_internalFail: 1|1@1+ (1,0) [0|0] "" X
 SG_ PARK3_w002_s1_linCommError: 2|1@1+ (1,0) [0|0] "" X
 SG_ PARK3_w003_s2_overTemp: 3|1@1+ (1,0) [0|0] "" X
 SG_ PARK3_w004_s2_internalFail: 4|1@1+ (1,0) [0|0] "" X
 SG_ PARK3_w005_s2_linCommError: 5|1@1+ (1,0) [0|0] "" X
 SG_ PARK3_w006_s3_overTemp: 6|1@1+ (1,0) [0|0] "" X
 SG_ PARK3_w007_s3_internalFail: 7|1@1+ (1,0) [0|0] "" X
 SG_ PARK3_w008_s3_linCommError: 8|1@1+ (1,0) [0|0] "" X
 SG_ PARK3_w009_s4_overTemp: 9|1@1+ (1,0) [0|0] "" X
 SG_ PARK3_w010_s4_internalFail: 10|1@1+ (1,0) [0|0] "" X
 SG_ PARK3_w011_s4_linCommError: 11|1@1+ (1,0) [0|0] "" X
 SG_ PARK3_w012_s5_overTemp: 12|1@1+ (1,0) [0|0] "" X
 SG_ PARK3_w013_s5_internalFail: 13|1@1+ (1,0) [0|0] "" X
 SG_ PARK3_w014_s5_linCommError: 14|1@1+ (1,0) [0|0] "" X
 SG_ PARK3_w015_s6_overTemp: 15|1@1+ (1,0) [0|0] "" X
 SG_ PARK3_w016_s6_internalFail: 16|1@1+ (1,0) [0|0] "" X
 SG_ PARK3_w017_s6_linCommError: 17|1@1+ (1,0) [0|0] "" X
 SG_ PARK3_w018_s7_overTemp: 18|1@1+ (1,0) [0|0] "" X
 SG_ PARK3_w019_s7_internalFail: 19|1@1+ (1,0) [0|0] "" X
 SG_ PARK3_w020_s7_linCommError: 20|1@1+ (1,0) [0|0] "" X
 SG_ PARK3_w021_s8_overTemp: 21|1@1+ (1,0) [0|0] "" X
 SG_ PARK3_w022_s8_internalFail: 22|1@1+ (1,0) [0|0] "" X
 SG_ PARK3_w023_s8_linCommError: 23|1@1+ (1,0) [0|0] "" X
 SG_ PARK3_w024_s9_overTemp: 24|1@1+ (1,0) [0|0] "" X
 SG_ PARK3_w025_s9_internalFail: 25|1@1+ (1,0) [0|0] "" X
 SG_ PARK3_w026_s9_linCommError: 26|1@1+ (1,0) [0|0] "" X
 SG_ PARK3_w027_s10_overTemp: 27|1@1+ (1,0) [0|0] "" X
 SG_ PARK3_w028_s10_internalFail: 28|1@1+ (1,0) [0|0] "" X
 SG_ PARK3_w029_s10_linCommError: 29|1@1+ (1,0) [0|0] "" X
 SG_ PARK3_w030_s11_overTemp: 30|1@1+ (1,0) [0|0] "" X
 SG_ PARK3_w031_s11_internalFail: 31|1@1+ (1,0) [0|0] "" X
 SG_ PARK3_w032_s11_linCommError: 32|1@1+ (1,0) [0|0] "" X
 SG_ PARK3_w033_s12_overTemp: 33|1@1+ (1,0) [0|0] "" X
 SG_ PARK3_w034_s12_internalFail: 34|1@1+ (1,0) [0|0] "" X
 SG_ PARK3_w035_s12_linCommError: 35|1@1+ (1,0) [0|0] "" X
 SG_ PARK3_w036_ecuUnderVoltage: 36|1@1+ (1,0) [0|0] "" X
 SG_ PARK3_w037_ecuOverVoltage: 37|1@1+ (1,0) [0|0] "" X
 SG_ PARK3_w038_sensorVoltage: 38|1@1+ (1,0) [0|0] "" X
 SG_ PARK3_w039_ecuFault: 39|1@1+ (1,0) [0|0] "" X
 SG_ PARK3_w040_crcFailure: 40|1@1+ (1,0) [0|0] "" X
 SG_ PARK3_w041_calibrationMissing: 41|1@1+ (1,0) [0|0] "" X
 SG_ PARK3_w042_CAN2busOff: 42|1@1+ (1,0) [0|0] "" X
 SG_ PARK3_w043_hwWatchDog: 43|1@1+ (1,0) [0|0] "" X
 SG_ PARK3_w044_dasMia: 44|1@1+ (1,0) [0|0] "" X
 SG_ PARK3_w045_diMia: 45|1@1+ (1,0) [0|0] "" X
 SG_ PARK3_w046_epasMia: 46|1@1+ (1,0) [0|0] "" X
 SG_ PARK3_w047_epbMia: 47|1@1+ (1,0) [0|0] "" X
 SG_ PARK3_w048_espMia: 48|1@1+ (1,0) [0|0] "" X
 SG_ PARK3_w049_gtwMia: 49|1@1+ (1,0) [0|0] "" X
 SG_ PARK3_w050_mcuMia: 50|1@1+ (1,0) [0|0] "" X
 SG_ PARK3_w051_sccmMia: 51|1@1+ (1,0) [0|0] "" X
 SG_ PARK3_w052_dasErr: 52|1@1+ (1,0) [0|0] "" X
 SG_ PARK3_w053_diErr: 53|1@1+ (1,0) [0|0] "" X
 SG_ PARK3_w054_epasErr: 54|1@1+ (1,0) [0|0] "" X
 SG_ PARK3_w055_epbErr: 55|1@1+ (1,0) [0|0] "" X
 SG_ PARK3_w056_espErr: 56|1@1+ (1,0) [0|0] "" X
 SG_ PARK3_w057_gtwErr: 57|1@1+ (1,0) [0|0] "" X
 SG_ PARK3_w058_mcuErr: 58|1@1+ (1,0) [0|0] "" X
 SG_ PARK3_w059_sccmErr: 59|1@1+ (1,0) [0|0] "" X
 SG_ PARK3_w060_nvmFault: 60|1@1+ (1,0) [0|0] "" X

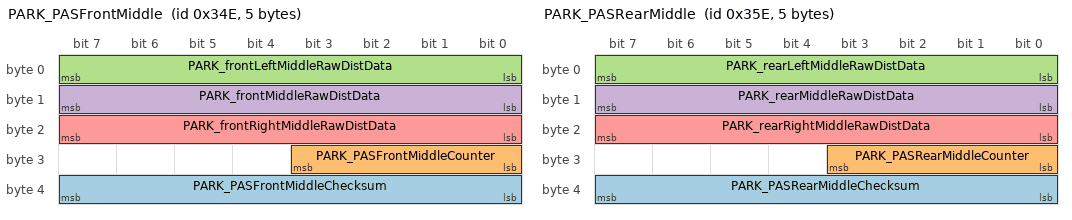
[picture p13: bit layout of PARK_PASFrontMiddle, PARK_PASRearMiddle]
BO_ 846 PARK_PASFrontMiddle: 5 ETH
 SG_ PARK_PASFrontMiddleChecksum: 32|8@1+ (1,0) [0|0] "" X
 SG_ PARK_PASFrontMiddleCounter: 24|4@1+ (1,0) [0|0] "" X
 SG_ PARK_frontLeftMiddleRawDistData: 0|8@1+ (1,0) [0|0] "" X
 SG_ PARK_frontMiddleRawDistData: 8|8@1+ (1,0) [0|0] "" X
 SG_ PARK_frontRightMiddleRawDistData: 16|8@1+ (1,0) [0|0] "" X

BO_ 862 PARK_PASRearMiddle: 5 ETH
 SG_ PARK_PASRearMiddleChecksum: 32|8@1+ (1,0) [0|0] "" X
 SG_ PARK_PASRearMiddleCounter: 24|4@1+ (1,0) [0|0] "" X
 SG_ PARK_rearLeftMiddleRawDistData: 0|8@1+ (1,0) [0|0] "" X
 SG_ PARK_rearMiddleRawDistData: 8|8@1+ (1,0) [0|0] "" X
 SG_ PARK_rearRightMiddleRawDistData: 16|8@1+ (1,0) [0|0] "" X

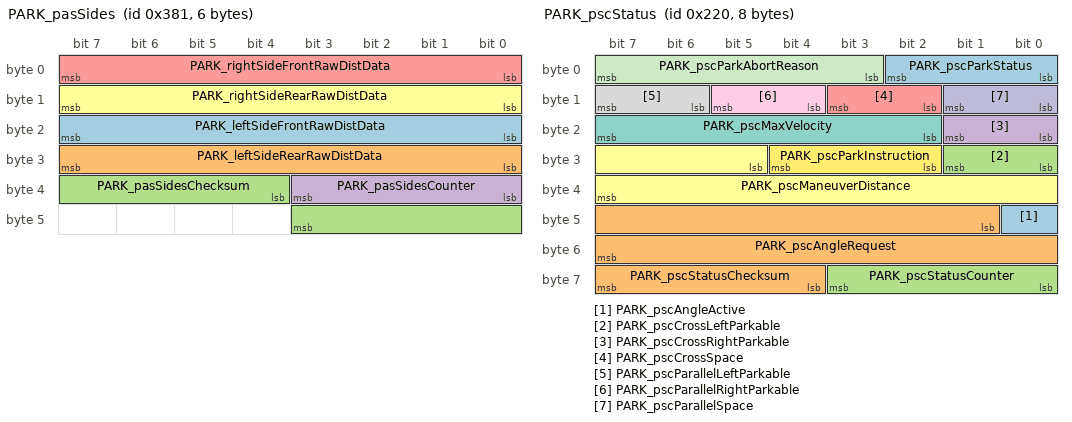
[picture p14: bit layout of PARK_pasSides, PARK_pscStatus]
BO_ 897 PARK_pasSides: 6 ETH
 SG_ PARK_leftSideFrontRawDistData: 16|8@1+ (1,0) [0|0] "cm" X
 SG_ PARK_leftSideRearRawDistData: 24|8@1+ (1,0) [0|0] "cm" X
 SG_ PARK_pasSidesChecksum: 36|8@1+ (1,0) [0|0] "" X
 SG_ PARK_pasSidesCounter: 32|4@1+ (1,0) [0|0] "" X
 SG_ PARK_rightSideFrontRawDistData: 0|8@1+ (1,0) [0|0] "cm" X
 SG_ PARK_rightSideRearRawDistData: 8|8@1+ (1,0) [0|0] "cm" X

BO_ 606 PARK_pscEnvSlot: 8 ETH
 SG_ PARK_pscEnvSlotType M: 0|3@1+ (1,0) [0|0] "" X
 SG_ PARK_pscLeftParallelObj1X m0: 3|11@1+ (2,-2048) [0|0] "cm" X
 SG_ PARK_pscLeftParallelObj1Y m0: 14|11@1+ (2,-2048) [0|0] "cm" X
 SG_ PARK_pscLeftParallelObj1Alpha m0: 25|7@1+ (2,-128) [0|0] "deg" X
 SG_ PARK_pscLeftParallelObj2Y m0: 35|11@1+ (2,-2048) [0|0] "cm" X
 SG_ PARK_pscLeftParallelObj2X m0: 46|11@1+ (2,-2048) [0|0] "cm" X
 SG_ PARK_pscLeftParallelObj2Alpha m0: 57|7@1+ (2,-128) [0|0] "deg" X
 SG_ PARK_pscLeftCrossObj1X m1: 3|11@1+ (2,-2048) [0|0] "cm" X
 SG_ PARK_pscLeftCrossObj1Y m1: 14|11@1+ (2,-2048) [0|0] "cm" X
 SG_ PARK_pscLeftCrossObj1Alpha m1: 25|7@1+ (2,-128) [0|0] "deg" X
 SG_ PARK_pscLeftCrossObj2Y m1: 35|11@1+ (2,-2048) [0|0] "cm" X
 SG_ PARK_pscLeftCrossObj2X m1: 46|11@1+ (2,-2048) [0|0] "cm" X
 SG_ PARK_pscLeftCrossObj2Alpha m1: 57|7@1+ (2,-128) [0|0] "deg" X
 SG_ PARK_pscRightParallelObj1X m2: 3|11@1+ (2,-2048) [0|0] "cm" X
 SG_ PARK_pscRightParallelObj1Y m2: 14|11@1+ (2,-2048) [0|0] "cm" X
 SG_ PARK_pscRightParallelObj1Alpha m2: 25|7@1+ (2,-128) [0|0] "deg" X
 SG_ PARK_pscRightParallelObj2Y m2: 35|11@1+ (2,-2048) [0|0] "cm" X
 SG_ PARK_pscRightParallelObj2X m2: 46|11@1+ (2,-2048) [0|0] "cm" X
 SG_ PARK_pscRightParallelObj2Alpha m2: 57|7@1+ (2,-128) [0|0] "deg" X
 SG_ PARK_pscRightCrossObj1X m3: 3|11@1+ (2,-2048) [0|0] "cm" X
 SG_ PARK_pscRightCrossObj1Y m3: 14|11@1+ (2,-2048) [0|0] "cm" X
 SG_ PARK_pscRightCrossObj1Alpha m3: 25|7@1+ (2,-128) [0|0] "deg" X
 SG_ PARK_pscRightCrossObj2Y m3: 35|11@1+ (2,-2048) [0|0] "cm" X
 SG_ PARK_pscRightCrossObj2X m3: 46|11@1+ (2,-2048) [0|0] "cm" X
 SG_ PARK_pscRightCrossObj2Alpha m3: 57|7@1+ (2,-128) [0|0] "deg" X

BO_ 544 PARK_pscStatus: 8 ETH
 SG_ PARK_pscAngleActive: 40|1@1+ (1,0) [0|0] "" X
 SG_ PARK_pscAngleRequest: 41|15@1+ (0.1,-1638.4) [0|0] "deg" X
 SG_ PARK_pscCrossLeftParkable: 24|2@1+ (1,0) [0|0] "" X
 SG_ PARK_pscCrossRightParkable: 16|2@1+ (1,0) [0|0] "" X
 SG_ PARK_pscCrossSpace: 10|2@1+ (1,0) [0|0] "" X
 SG_ PARK_pscManeuverDistance: 29|11@1+ (1,0) [0|0] "cm" X
 SG_ PARK_pscMaxVelocity: 18|6@1+ (0.1,0) [0|0] "kph" X
 SG_ PARK_pscParallelLeftParkable: 14|2@1+ (1,0) [0|0] "" X
 SG_ PARK_pscParallelRightParkable: 12|2@1+ (1,0) [0|0] "" X
 SG_ PARK_pscParallelSpace: 8|2@1+ (1,0) [0|0] "" X
 SG_ PARK_pscParkAbortReason: 3|5@1+ (1,0) [0|0] "" X
 SG_ PARK_pscParkInstruction: 26|3@1+ (1,0) [0|0] "" X
 SG_ PARK_pscParkStatus: 0|3@1+ (1,0) [0|0] "" X
 SG_ PARK_pscStatusChecksum: 60|4@1+ (1,0) [0|0] "" X
 SG_ PARK_pscStatusCounter: 56|4@1+ (1,0) [0|0] "" X

BO_ 590 PARK_pscVehSlot: 8 ETH
 SG_ PARK_pscVehSlotType M: 0|3@1+ (1,0) [0|0] "" X
 SG_ PARK_pscLeftParallelVehX m0: 5|11@1+ (2,-2048) [0|0] "cm" X
 SG_ PARK_pscLeftParallelVehY m0: 16|11@1+ (2,-2048) [0|0] "cm" X
 SG_ PARK_pscLeftParallelPsi m0: 32|13@1+ (0.000976563,0) [0|0] "radians" X
 SG_ PARK_pscLeftParallelSizeX m0: 48|8@1+ (4,0) [0|0] "cm" X
 SG_ PARK_pscLeftParallelSizeY m0: 56|8@1+ (4,0) [0|0] "cm" X
 SG_ PARK_pscLeftCrossVehX m1: 5|11@1+ (2,-2048) [0|0] "cm" X
 SG_ PARK_pscLeftCrossVehY m1: 16|11@1+ (2,-2048) [0|0] "cm" X
 SG_ PARK_pscLeftCrossPsi m1: 32|13@1+ (0.000976563,0) [0|0] "radians" X
 SG_ PARK_pscLeftCrossSizeX m1: 48|8@1+ (4,0) [0|0] "cm" X
 SG_ PARK_pscLeftCrossSizeY m1: 56|8@1+ (4,0) [0|0] "cm" X
 SG_ PARK_pscRightParallelVehX m2: 5|11@1+ (2,-2048) [0|0] "cm" X
 SG_ PARK_pscRightParallelVehY m2: 16|11@1+ (2,-2048) [0|0] "cm" X
 SG_ PARK_pscRightParallelPsi m2: 32|13@1+ (0.000976563,0) [0|0] "radians" X
 SG_ PARK_pscRightParallelSizeX m2: 48|8@1+ (4,0) [0|0] "cm" X
 SG_ PARK_pscRightParallelSizeY m2: 56|8@1+ (4,0) [0|0] "cm" X
 SG_ PARK_pscRightCrossVehX m3: 5|11@1+ (2,-2048) [0|0] "cm" X
 SG_ PARK_pscRightCrossVehY m3: 16|11@1+ (2,-2048) [0|0] "cm" X
 SG_ PARK_pscRightCrossPsi m3: 32|13@1+ (0.000976563,0) [0|0] "radians" X
 SG_ PARK_pscRightCrossSizeX m3: 48|8@1+ (4,0) [0|0] "cm" X
 SG_ PARK_pscRightCrossSizeY m3: 56|8@1+ (4,0) [0|0] "cm" X

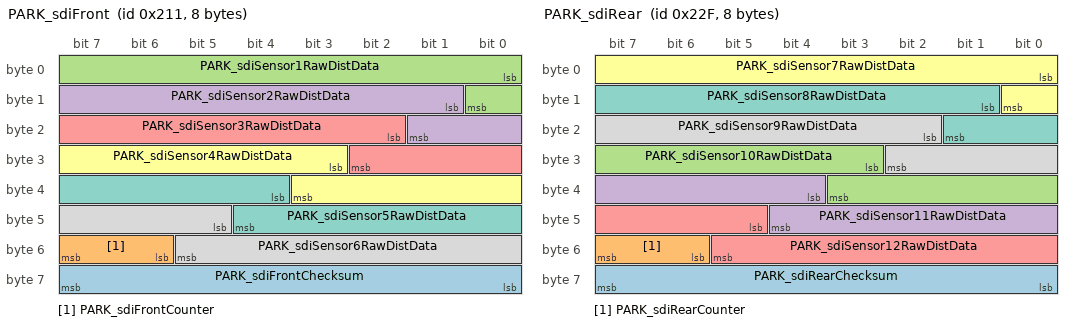
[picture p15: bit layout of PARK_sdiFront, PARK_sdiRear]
BO_ 529 PARK_sdiFront: 8 ETH
 SG_ PARK_sdiFrontChecksum: 56|8@1+ (1,0) [0|0] "" X
 SG_ PARK_sdiFrontCounter: 54|2@1+ (1,0) [0|0] "" X
 SG_ PARK_sdiSensor1RawDistData: 0|9@1+ (1,0) [0|0] "cm" X
 SG_ PARK_sdiSensor2RawDistData: 9|9@1+ (1,0) [0|0] "cm" X
 SG_ PARK_sdiSensor3RawDistData: 18|9@1+ (1,0) [0|0] "cm" X
 SG_ PARK_sdiSensor4RawDistData: 27|9@1+ (1,0) [0|0] "cm" X
 SG_ PARK_sdiSensor5RawDistData: 36|9@1+ (1,0) [0|0] "cm" X
 SG_ PARK_sdiSensor6RawDistData: 45|9@1+ (1,0) [0|0] "cm" X

BO_ 559 PARK_sdiRear: 8 ETH
 SG_ PARK_sdiRearChecksum: 56|8@1+ (1,0) [0|0] "" X
 SG_ PARK_sdiRearCounter: 54|2@1+ (1,0) [0|0] "" X
 SG_ PARK_sdiSensor10RawDistData: 27|9@1+ (1,0) [0|0] "cm" X
 SG_ PARK_sdiSensor11RawDistData: 36|9@1+ (1,0) [0|0] "cm" X
 SG_ PARK_sdiSensor12RawDistData: 45|9@1+ (1,0) [0|0] "cm" X
 SG_ PARK_sdiSensor7RawDistData: 0|9@1+ (1,0) [0|0] "cm" X
 SG_ PARK_sdiSensor8RawDistData: 9|9@1+ (1,0) [0|0] "cm" X
 SG_ PARK_sdiSensor9RawDistData: 18|9@1+ (1,0) [0|0] "cm" X

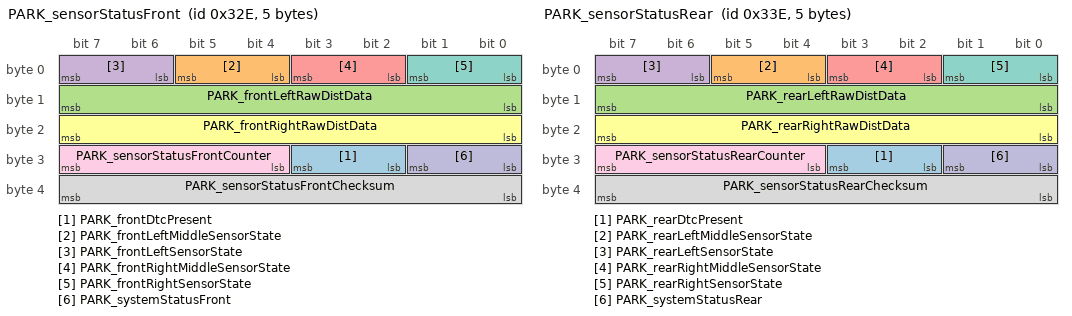
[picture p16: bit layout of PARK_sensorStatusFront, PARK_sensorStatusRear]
BO_ 814 PARK_sensorStatusFront: 5 ETH
 SG_ PARK_frontDtcPresent: 26|2@1+ (1,0) [0|0] "" X
 SG_ PARK_frontLeftMiddleSensorState: 4|2@1+ (1,0) [0|0] "" X
 SG_ PARK_frontLeftRawDistData: 8|8@1+ (1,0) [0|0] "" X
 SG_ PARK_frontLeftSensorState: 6|2@1+ (1,0) [0|0] "" X
 SG_ PARK_frontRightMiddleSensorState: 2|2@1+ (1,0) [0|0] "" X
 SG_ PARK_frontRightRawDistData: 16|8@1+ (1,0) [0|0] "" X
 SG_ PARK_frontRightSensorState: 0|2@1+ (1,0) [0|0] "" X
 SG_ PARK_sensorStatusFrontChecksum: 32|8@1+ (1,0) [0|0] "" X
 SG_ PARK_sensorStatusFrontCounter: 28|4@1+ (1,0) [0|0] "" X
 SG_ PARK_systemStatusFront: 24|2@1+ (1,0) [0|0] "" X

BO_ 830 PARK_sensorStatusRear: 5 ETH
 SG_ PARK_rearDtcPresent: 26|2@1+ (1,0) [0|0] "" X
 SG_ PARK_rearLeftMiddleSensorState: 4|2@1+ (1,0) [0|0] "" X
 SG_ PARK_rearLeftRawDistData: 8|8@1+ (1,0) [0|0] "" X
 SG_ PARK_rearLeftSensorState: 6|2@1+ (1,0) [0|0] "" X
 SG_ PARK_rearRightMiddleSensorState: 2|2@1+ (1,0) [0|0] "" X
 SG_ PARK_rearRightRawDistData: 16|8@1+ (1,0) [0|0] "" X
 SG_ PARK_rearRightSensorState: 0|2@1+ (1,0) [0|0] "" X
 SG_ PARK_sensorStatusRearChecksum: 32|8@1+ (1,0) [0|0] "" X
 SG_ PARK_sensorStatusRearCounter: 28|4@1+ (1,0) [0|0] "" X
 SG_ PARK_systemStatusRear: 24|2@1+ (1,0) [0|0] "" X

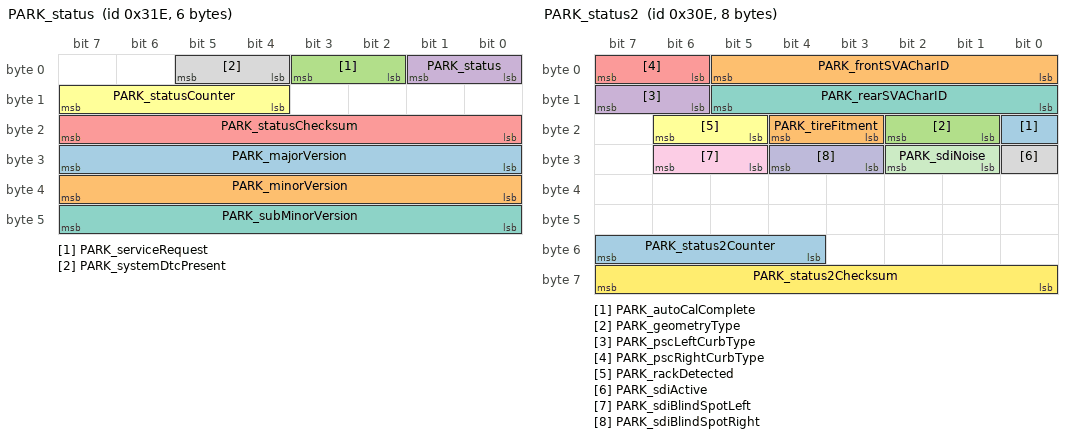
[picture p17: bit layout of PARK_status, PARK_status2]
BO_ 798 PARK_status: 6 ETH
 SG_ PARK_majorVersion: 24|8@1+ (1,0) [0|0] "" X
 SG_ PARK_minorVersion: 32|8@1+ (1,0) [0|0] "" X
 SG_ PARK_serviceRequest: 2|2@1+ (1,0) [0|0] "" X
 SG_ PARK_status: 0|2@1+ (1,0) [0|0] "" X
 SG_ PARK_statusChecksum: 16|8@1+ (1,0) [0|0] "" X
 SG_ PARK_statusCounter: 12|4@1+ (1,0) [0|0] "" X
 SG_ PARK_subMinorVersion: 40|8@1+ (1,0) [0|0] "" X
 SG_ PARK_systemDtcPresent: 4|2@1+ (1,0) [0|0] "" X

BO_ 782 PARK_status2: 8 ETH
 SG_ PARK_autoCalComplete: 16|1@1+ (1,0) [0|0] "" X
 SG_ PARK_frontSVACharID: 0|6@1+ (1,0) [0|0] "" X
 SG_ PARK_geometryType: 17|2@1+ (1,0) [0|0] "" X
 SG_ PARK_pscLeftCurbType: 14|2@1+ (1,0) [0|0] "" X
 SG_ PARK_pscRightCurbType: 6|2@1+ (1,0) [0|0] "" X
 SG_ PARK_rackDetected: 21|2@1+ (1,0) [0|0] "" X
 SG_ PARK_rearSVACharID: 8|6@1+ (1,0) [0|0] "" X
 SG_ PARK_sdiActive: 24|1@1+ (1,0) [0|0] "" X
 SG_ PARK_sdiBlindSpotLeft: 29|2@1+ (1,0) [0|0] "" X
 SG_ PARK_sdiBlindSpotRight: 27|2@1+ (1,0) [0|0] "" X
 SG_ PARK_sdiNoise: 25|2@1+ (1,0) [0|0] "" X
 SG_ PARK_status2Checksum: 56|8@1+ (1,0) [0|0] "" X
 SG_ PARK_status2Counter: 52|4@1+ (1,0) [0|0] "" X
 SG_ PARK_tireFitment: 19|2@1+ (1,0) [0|0] "" X

BO_ 1630 PARK_udsResponse: 8 ETH
 SG_ PARK_udsResponseData: 0|54@0+ (1024,0) [0|0] "" X

BO_ 928 PARK_warningMatrix: 8 ETH
 SG_ PARK_w000_sensorDisturbance: 0|1@1+ (1,0) [0|0] "" X
 SG_ PARK_w001_S1_shortGround: 1|1@1+ (1,0) [0|0] "" X
 SG_ PARK_w002_S1_shortBattery: 2|1@1+ (1,0) [0|0] "" X
 SG_ PARK_w003_S1_ringTooLong: 3|1@1+ (1,0) [0|0] "" X
 SG_ PARK_w004_S2_shortGround: 4|1@1+ (1,0) [0|0] "" X
 SG_ PARK_w005_S2_shortBattery: 5|1@1+ (1,0) [0|0] "" X
 SG_ PARK_w006_S2_ringTooLong: 6|1@1+ (1,0) [0|0] "" X
 SG_ PARK_w007_S3_shortGround: 7|1@1+ (1,0) [0|0] "" X
 SG_ PARK_w008_S3_shortBattery: 8|1@1+ (1,0) [0|0] "" X
 SG_ PARK_w009_S3_ringTooLong: 9|1@1+ (1,0) [0|0] "" X
 SG_ PARK_w010_S4_shortGround: 10|1@1+ (1,0) [0|0] "" X
 SG_ PARK_w011_S4_shortBattery: 11|1@1+ (1,0) [0|0] "" X
 SG_ PARK_w012_S4_ringTooLong: 12|1@1+ (1,0) [0|0] "" X
 SG_ PARK_w013_S5_shortGround: 13|1@1+ (1,0) [0|0] "" X
 SG_ PARK_w014_S5_shortBattery: 14|1@1+ (1,0) [0|0] "" X
 SG_ PARK_w015_S5_ringTooLong: 15|1@1+ (1,0) [0|0] "" X
 SG_ PARK_w016_S6_shortGround: 16|1@1+ (1,0) [0|0] "" X
 SG_ PARK_w017_S6_shortBattery: 17|1@1+ (1,0) [0|0] "" X
 SG_ PARK_w018_S6_ringTooLong: 18|1@1+ (1,0) [0|0] "" X
 SG_ PARK_w019_S7_shortGround: 19|1@1+ (1,0) [0|0] "" X
 SG_ PARK_w020_S7_shortBattery: 20|1@1+ (1,0) [0|0] "" X
 SG_ PARK_w021_S7_ringTooLong: 21|1@1+ (1,0) [0|0] "" X
 SG_ PARK_w022_S8_shortGround: 22|1@1+ (1,0) [0|0] "" X
 SG_ PARK_w023_S8_shortBattery: 23|1@1+ (1,0) [0|0] "" X
 SG_ PARK_w024_S8_ringTooLong: 24|1@1+ (1,0) [0|0] "" X
 SG_ PARK_w025_S9_shortGround: 25|1@1+ (1,0) [0|0] "" X
 SG_ PARK_w026_S9_shortBattery: 26|1@1+ (1,0) [0|0] "" X
 SG_ PARK_w027_S9_ringTooLong: 27|1@1+ (1,0) [0|0] "" X
 SG_ PARK_w028_S10_shortGround: 28|1@1+ (1,0) [0|0] "" X
 SG_ PARK_w029_S10_shortBattery: 29|1@1+ (1,0) [0|0] "" X
 SG_ PARK_w030_S10_ringTooLong: 30|1@1+ (1,0) [0|0] "" X
 SG_ PARK_w031_S11_shortGround: 31|1@1+ (1,0) [0|0] "" X
 SG_ PARK_w032_S11_shortBattery: 32|1@1+ (1,0) [0|0] "" X
 SG_ PARK_w033_S11_ringTooLong: 33|1@1+ (1,0) [0|0] "" X
 SG_ PARK_w034_S12_shortGround: 34|1@1+ (1,0) [0|0] "" X
 SG_ PARK_w035_S12_shortBattery: 35|1@1+ (1,0) [0|0] "" X
 SG_ PARK_w036_S12_ringTooLong: 36|1@1+ (1,0) [0|0] "" X
 SG_ PARK_w037_sensorSupplyLow: 37|1@1+ (1,0) [0|0] "" X
 SG_ PARK_w038_sensorSupplyHigh: 38|1@1+ (1,0) [0|0] "" X
 SG_ PARK_w039_hardwareError: 39|1@1+ (1,0) [0|0] "" X
 SG_ PARK_w040_ECUSupplyLow: 40|1@1+ (1,0) [0|0] "" X
 SG_ PARK_w041_ECUSupplyHigh: 41|1@1+ (1,0) [0|0] "" X
 SG_ PARK_w042_dasMIA: 42|1@1+ (1,0) [0|0] "" X
 SG_ PARK_w043_epasMIA: 43|1@1+ (1,0) [0|0] "" X
 SG_ PARK_w044_epbMIA: 44|1@1+ (1,0) [0|0] "" X
 SG_ PARK_w045_espMIA: 45|1@1+ (1,0) [0|0] "" X
 SG_ PARK_w046_sccmMIA: 46|1@1+ (1,0) [0|0] "" X
 SG_ PARK_w047_dasErr: 47|1@1+ (1,0) [0|0] "" X
 SG_ PARK_w048_epasErr: 48|1@1+ (1,0) [0|0] "" X
 SG_ PARK_w049_epbErr: 49|1@1+ (1,0) [0|0] "" X
 SG_ PARK_w050_espErr: 50|1@1+ (1,0) [0|0] "" X
 SG_ PARK_w051_sccmErr: 51|1@1+ (1,0) [0|0] "" X
 SG_ PARK_w052_S1_sensorState: 52|1@1+ (1,0) [0|0] "" X
 SG_ PARK_w053_S2_sensorState: 53|1@1+ (1,0) [0|0] "" X
 SG_ PARK_w054_S3_sensorState: 54|1@1+ (1,0) [0|0] "" X
 SG_ PARK_w055_S4_sensorState: 55|1@1+ (1,0) [0|0] "" X
 SG_ PARK_w056_S5_sensorState: 56|1@1+ (1,0) [0|0] "" X
 SG_ PARK_w057_S6_sensorState: 57|1@1+ (1,0) [0|0] "" X
 SG_ PARK_w058_S7_sensorState: 58|1@1+ (1,0) [0|0] "" X
 SG_ PARK_w059_S8_sensorState: 59|1@1+ (1,0) [0|0] "" X
 SG_ PARK_w060_S9_sensorState: 60|1@1+ (1,0) [0|0] "" X
 SG_ PARK_w061_S10_sensorState: 61|1@1+ (1,0) [0|0] "" X
 SG_ PARK_w062_S11_sensorState: 62|1@1+ (1,0) [0|0] "" X
 SG_ PARK_w063_S12_sensorState: 63|1@1+ (1,0) [0|0] "" X

BO_ 99 PDMStatus_partial: 1 ETH
 SG_ PDM_passRepeaterState: 0|2@1+ (1,0) [0|0] "" X

BO_ 553 PDM_frontHandleStatus: 8 ETH
 SG_ PF_componentHardwareId: 8|8@1+ (1,0) [0|0] "" X
 SG_ PF_componentMajorVersion: 16|8@1+ (1,0) [0|0] "" X
 SG_ PF_componentMinorVersion: 24|8@1+ (1,0) [0|0] "" X
 SG_ PF_errorResp: 0|1@1+ (1,0) [0|0] "" X
 SG_ PF_mainState: 48|8@1+ (1,0) [0|0] "" X
 SG_ PF_motorState: 56|8@1+ (1,0) [0|0] "" X
 SG_ PF_presentReq: 3|1@1+ (1,0) [0|0] "" X
 SG_ PF_releaseReq: 2|1@1+ (1,0) [0|0] "" X
 SG_ PF_svnOrAngle: 32|16@0+ (1,0) [0|0] "" X
 SG_ PF_targetPosition: 4|4@1+ (1,0) [0|0] "" X

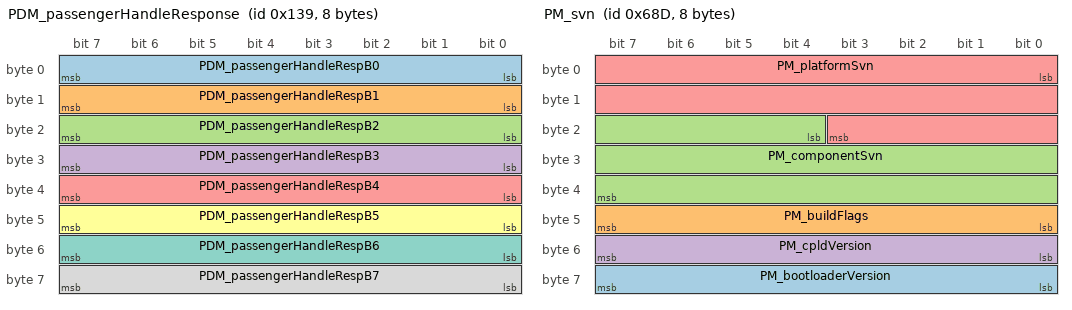
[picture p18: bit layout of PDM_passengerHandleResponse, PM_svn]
BO_ 313 PDM_passengerHandleResponse: 8 ETH
 SG_ PDM_passengerHandleRespB0: 0|8@1+ (1,0) [0|0] "" X
 SG_ PDM_passengerHandleRespB1: 8|8@1+ (1,0) [0|0] "" X
 SG_ PDM_passengerHandleRespB2: 16|8@1+ (1,0) [0|0] "" X
 SG_ PDM_passengerHandleRespB3: 24|8@1+ (1,0) [0|0] "" X
 SG_ PDM_passengerHandleRespB4: 32|8@1+ (1,0) [0|0] "" X
 SG_ PDM_passengerHandleRespB5: 40|8@1+ (1,0) [0|0] "" X
 SG_ PDM_passengerHandleRespB6: 48|8@1+ (1,0) [0|0] "" X
 SG_ PDM_passengerHandleRespB7: 56|8@1+ (1,0) [0|0] "" X

BO_ 569 PDM_rearHandleStatus: 8 ETH
 SG_ PR_componentHardwareId: 8|8@1+ (1,0) [0|0] "" X
 SG_ PR_componentMajorVersion: 16|8@1+ (1,0) [0|0] "" X
 SG_ PR_componentMinorVersion: 24|8@1+ (1,0) [0|0] "" X
 SG_ PR_errorResp: 0|1@1+ (1,0) [0|0] "" X
 SG_ PR_mainState: 48|8@1+ (1,0) [0|0] "" X
 SG_ PR_motorState: 56|8@1+ (1,0) [0|0] "" X
 SG_ PR_presentReq: 3|1@1+ (1,0) [0|0] "" X
 SG_ PR_releaseReq: 2|1@1+ (1,0) [0|0] "" X
 SG_ PR_svnOrAngle: 32|16@0+ (1,0) [0|0] "" X
 SG_ PR_targetPosition: 4|4@1+ (1,0) [0|0] "" X

BO_ 1689 PDM_udsResponse: 8 ETH
 SG_ PDM_udsResponseData: 0|54@0+ (1024,0) [0|0] "" X

BO_ 1305 PDM_version: 8 ETH
 SG_ PDM_componentBranchOrigin: 40|8@1+ (1,0) [0|0] "" X
 SG_ PDM_componentHardwareRevision: 56|8@1+ (1,0) [0|0] "" X
 SG_ PDM_componentMajorVersion: 32|8@1+ (1,0) [0|0] "" X
 SG_ PDM_componentMaturity: 48|8@1+ (1,0) [0|0] "" X
 SG_ PDM_componentSvn: 8|24@0+ (1,0) [0|0] "" X
 SG_ PDM_platformType: 0|8@1+ (1,0) [0|0] "" X

BO_ 900 PMS_alertMatrix1: 8 ETH
 SG_ PMS_f001_absoluteTorque: 0|1@1+ (1,0) [0|0] "" X
 SG_ PMS_f002_accumulatedTorque: 1|1@1+ (1,0) [0|0] "" X
 SG_ PMS_f003_torqueReversal: 2|1@1+ (1,0) [0|0] "" X
 SG_ PMS_f004_regenTorque: 3|1@1+ (1,0) [0|0] "" X
 SG_ PMS_f005_torqueInNeutral: 4|1@1+ (1,0) [0|0] "" X
 SG_ PMS_f006_inconsistentDIGear: 5|1@1+ (1,0) [0|0] "" X
 SG_ PMS_f007_watchdogReset: 6|1@1+ (1,0) [0|0] "" X
 SG_ PMS_f008_memoryError: 7|1@1+ (1,0) [0|0] "" X
 SG_ PMS_f009_espMIA: 8|1@1+ (1,0) [0|0] "" X
 SG_ PMS_f010_diMIA: 9|1@1+ (1,0) [0|0] "" X
 SG_ PMS_f011_phaseCurrentIrrational: 10|1@1+ (1,0) [0|0] "" X
 SG_ PMS_f012_canData: 11|1@1+ (1,0) [0|0] "" X
 SG_ PMS_f013_canHardware: 12|1@1+ (1,0) [0|0] "" X
 SG_ PMS_f014_accelPedalError: 13|1@1+ (1,0) [0|0] "" X
 SG_ PMS_f015_shifterMIA: 14|1@1+ (1,0) [0|0] "" X
 SG_ PMS_f016_cruiseMIA: 15|1@1+ (1,0) [0|0] "" X
 SG_ PMS_f017_brakeMIA: 16|1@1+ (1,0) [0|0] "" X
 SG_ PMS_f018_encoderIrrational: 17|1@1+ (1,0) [0|0] "" X
 SG_ PMS_f019_statorTempIrrational: 18|1@1+ (1,0) [0|0] "" X
 SG_ PMS_f020_cruiseTorqueExceeded: 19|1@1+ (1,0) [0|0] "" X
 SG_ PMS_f021_cruiseSpeedRegulation: 20|1@1+ (1,0) [0|0] "" X
 SG_ PMS_f022_crsCmdOnStateOff: 21|1@1+ (1,0) [0|0] "" X
 SG_ PMS_f023_crsCmdOffStateOn: 22|1@1+ (1,0) [0|0] "" X
 SG_ PMS_f024_brakeIrrational: 23|1@1+ (1,0) [0|0] "" X
 SG_ PMS_f025_crsOnBrake: 24|1@1+ (1,0) [0|0] "" X
 SG_ PMS_f026_diHeartBeatMIA: 25|1@1+ (1,0) [0|0] "" X
 SG_ PMS_f027_torqueOutOfMap: 26|1@1+ (1,0) [0|0] "" X
 SG_ PMS_f028_torqueCmdError: 27|1@1+ (1,0) [0|0] "" X
 SG_ PMS_f029_limpTorque: 28|1@1+ (1,0) [0|0] "" X
 SG_ PMS_f030_inconsistentAebState: 29|1@1+ (1,0) [0|0] "" X
 SG_ PMS_f031_highStackUsage: 30|1@1+ (1,0) [0|0] "" X
 SG_ PMS_f032_registerConfigError: 31|1@1+ (1,0) [0|0] "" X
 SG_ PMS_f033_selfTest: 32|1@1+ (1,0) [0|0] "" X
 SG_ PMS_f034_trqCrossCheck: 33|1@1+ (1,0) [0|0] "" X
 SG_ PMS_f035_brkMIA: 34|1@1+ (1,0) [0|0] "" X
 SG_ PMS_f036_cpcMIA: 35|1@1+ (1,0) [0|0] "" X
 SG_ PMS_f037_engMIA: 36|1@1+ (1,0) [0|0] "" X
 SG_ PMS_f038_inconsistentTorqueSign: 37|1@1+ (1,0) [0|0] "" X
 SG_ PMS_f039_disMIA: 38|1@1+ (1,0) [0|0] "" X
 SG_ PMS_f040_pmMIA: 39|1@1+ (1,0) [0|0] "" X
 SG_ PMS_f041_unused: 40|1@1+ (1,0) [0|0] "" X
 SG_ PMS_f042_gtwMIA: 41|1@1+ (1,0) [0|0] "" X
 SG_ PMS_f043_inconsistentConfig: 42|1@1+ (1,0) [0|0] "" X
 SG_ PMS_f044_unused: 43|1@1+ (1,0) [0|0] "" X
 SG_ PMS_f045_spiError: 44|1@1+ (1,0) [0|0] "" X
 SG_ PMS_f046_inconsVehicleHoldState: 45|1@1+ (1,0) [0|0] "" X
 SG_ PMS_f047_inconsAutoparkState: 46|1@1+ (1,0) [0|0] "" X
 SG_ PMS_f048_unused: 47|1@1+ (1,0) [0|0] "" X
 SG_ PMS_f049_unused: 48|1@1+ (1,0) [0|0] "" X
 SG_ PMS_f050_unused: 49|1@1+ (1,0) [0|0] "" X
 SG_ PMS_f051_unused: 50|1@1+ (1,0) [0|0] "" X
 SG_ PMS_f052_unused: 51|1@1+ (1,0) [0|0] "" X
 SG_ PMS_f053_unused: 52|1@1+ (1,0) [0|0] "" X
 SG_ PMS_f054_unused: 53|1@1+ (1,0) [0|0] "" X
 SG_ PMS_f055_unused: 54|1@1+ (1,0) [0|0] "" X
 SG_ PMS_f056_unused: 55|1@1+ (1,0) [0|0] "" X
 SG_ PMS_f057_unused: 56|1@1+ (1,0) [0|0] "" X
 SG_ PMS_f058_unused: 57|1@1+ (1,0) [0|0] "" X
 SG_ PMS_f059_unused: 58|1@1+ (1,0) [0|0] "" X
 SG_ PMS_f060_unused: 59|1@1+ (1,0) [0|0] "" X
 SG_ PMS_f061_DIPMVersionMismatch: 60|1@1+ (1,0) [0|0] "" X
 SG_ PMS_f062_unused: 61|1@1+ (1,0) [0|0] "" X
 SG_ PMS_f063_unused: 62|1@1+ (1,0) [0|0] "" X
 SG_ PMS_f064_torqueIntervention: 63|1@1+ (1,0) [0|0] "" X

BO_ 916 PMS_alertMatrix2: 8 ETH
 SG_ PMS_w001_absoluteTorque: 0|1@1+ (1,0) [0|0] "" X
 SG_ PMS_w002_accumulatedTorque: 1|1@1+ (1,0) [0|0] "" X
 SG_ PMS_w003_torqueReversal: 2|1@1+ (1,0) [0|0] "" X
 SG_ PMS_w004_regenTorque: 3|1@1+ (1,0) [0|0] "" X
 SG_ PMS_w005_torqueInNeutral: 4|1@1+ (1,0) [0|0] "" X
 SG_ PMS_w006_inconsistentDIGear: 5|1@1+ (1,0) [0|0] "" X
 SG_ PMS_w007_watchdogReset: 6|1@1+ (1,0) [0|0] "" X
 SG_ PMS_w008_memoryError: 7|1@1+ (1,0) [0|0] "" X
 SG_ PMS_w009_espMIA: 8|1@1+ (1,0) [0|0] "" X
 SG_ PMS_w010_diMIA: 9|1@1+ (1,0) [0|0] "" X
 SG_ PMS_w011_phaseCurrentIrrational: 10|1@1+ (1,0) [0|0] "" X
 SG_ PMS_w012_canData: 11|1@1+ (1,0) [0|0] "" X
 SG_ PMS_w013_canHardware: 12|1@1+ (1,0) [0|0] "" X
 SG_ PMS_w014_accelPedalError: 13|1@1+ (1,0) [0|0] "" X
 SG_ PMS_w015_shifterMIA: 14|1@1+ (1,0) [0|0] "" X
 SG_ PMS_w016_cruiseMIA: 15|1@1+ (1,0) [0|0] "" X
 SG_ PMS_w017_brakeMIA: 16|1@1+ (1,0) [0|0] "" X
 SG_ PMS_w018_encoderIrrational: 17|1@1+ (1,0) [0|0] "" X
 SG_ PMS_w019_statorTempIrrational: 18|1@1+ (1,0) [0|0] "" X
 SG_ PMS_w020_cruiseTorqueExceeded: 19|1@1+ (1,0) [0|0] "" X
 SG_ PMS_w021_cruiseSpeedRegulation: 20|1@1+ (1,0) [0|0] "" X
 SG_ PMS_w022_crsCmdOnStateOff: 21|1@1+ (1,0) [0|0] "" X
 SG_ PMS_w023_crsCmdOffStateOn: 22|1@1+ (1,0) [0|0] "" X
 SG_ PMS_w024_brakeIrrational: 23|1@1+ (1,0) [0|0] "" X
 SG_ PMS_w025_crsOnBrake: 24|1@1+ (1,0) [0|0] "" X
 SG_ PMS_w026_diHeartBeatMIA: 25|1@1+ (1,0) [0|0] "" X
 SG_ PMS_w027_torqueOutOfMap: 26|1@1+ (1,0) [0|0] "" X
 SG_ PMS_w028_torqueCmdError: 27|1@1+ (1,0) [0|0] "" X
 SG_ PMS_w029_limpTorque: 28|1@1+ (1,0) [0|0] "" X
 SG_ PMS_w030_inconsistentAebState: 29|1@1+ (1,0) [0|0] "" X
 SG_ PMS_w031_highStackUsage: 30|1@1+ (1,0) [0|0] "" X
 SG_ PMS_w032_registerConfigError: 31|1@1+ (1,0) [0|0] "" X
 SG_ PMS_w033_selfTest: 32|1@1+ (1,0) [0|0] "" X
 SG_ PMS_w034_trqCrossCheck: 33|1@1+ (1,0) [0|0] "" X
 SG_ PMS_w035_brkMIA: 34|1@1+ (1,0) [0|0] "" X
 SG_ PMS_w036_cpcMIA: 35|1@1+ (1,0) [0|0] "" X
 SG_ PMS_w037_engMIA: 36|1@1+ (1,0) [0|0] "" X
 SG_ PMS_w038_inconsistentTorqueSign: 37|1@1+ (1,0) [0|0] "" X
 SG_ PMS_w039_disMIA: 38|1@1+ (1,0) [0|0] "" X
 SG_ PMS_w040_pmMIA: 39|1@1+ (1,0) [0|0] "" X
 SG_ PMS_w041_unused: 40|1@1+ (1,0) [0|0] "" X
 SG_ PMS_w042_gtwMIA: 41|1@1+ (1,0) [0|0] "" X
 SG_ PMS_w043_inconsistentConfig: 42|1@1+ (1,0) [0|0] "" X
 SG_ PMS_w044_unused: 43|1@1+ (1,0) [0|0] "" X
 SG_ PMS_w045_spiError: 44|1@1+ (1,0) [0|0] "" X
 SG_ PMS_w046_inconsVehicleHoldState: 45|1@1+ (1,0) [0|0] "" X
 SG_ PMS_w047_inconsAutoparkState: 46|1@1+ (1,0) [0|0] "" X
 SG_ PMS_w048_unused: 47|1@1+ (1,0) [0|0] "" X
 SG_ PMS_w049_unused: 48|1@1+ (1,0) [0|0] "" X
 SG_ PMS_w050_unused: 49|1@1+ (1,0) [0|0] "" X
 SG_ PMS_w051_unused: 50|1@1+ (1,0) [0|0] "" X
 SG_ PMS_w052_unused: 51|1@1+ (1,0) [0|0] "" X
 SG_ PMS_w053_unused: 52|1@1+ (1,0) [0|0] "" X
 SG_ PMS_w054_unused: 53|1@1+ (1,0) [0|0] "" X
 SG_ PMS_w055_unused: 54|1@1+ (1,0) [0|0] "" X
 SG_ PMS_w056_unused: 55|1@1+ (1,0) [0|0] "" X
 SG_ PMS_w057_unused: 56|1@1+ (1,0) [0|0] "" X
 SG_ PMS_w058_unused: 57|1@1+ (1,0) [0|0] "" X
 SG_ PMS_w059_unused: 58|1@1+ (1,0) [0|0] "" X
 SG_ PMS_w060_unused: 59|1@1+ (1,0) [0|0] "" X
 SG_ PMS_w061_DIPMVersionMismatch: 60|1@1+ (1,0) [0|0] "" X
 SG_ PMS_w062_unused: 61|1@1+ (1,0) [0|0] "" X
 SG_ PMS_w063_unused: 62|1@1+ (1,0) [0|0] "" X
 SG_ PMS_w064_torqueIntervention: 63|1@1+ (1,0) [0|0] "" X

BO_ 1748 PMS_info: 8 ETH
 SG_ PMS_infoIndex M: 0|8@1+ (1,0) [0|0] "" X
 SG_ PMS_buildType m10: 8|8@1+ (1,0) [0|0] "" X
 SG_ PMS_buildConfigurationId m10: 16|16@1+ (1,0) [0|0] "" X
 SG_ PMS_hardwareId m10: 32|16@1+ (1,0) [0|0] "" X
 SG_ PMS_componentId m10: 48|16@1+ (1,0) [0|0] "" X
 SG_ PMS_pcbaId m11: 16|8@1+ (1,0) [0|0] "" X
 SG_ PMS_assemblyId m11: 24|8@1+ (1,0) [0|0] "" X
 SG_ PMS_usageId m11: 32|16@1+ (1,0) [0|0] "" X
 SG_ PMS_subUsageId m11: 48|16@1+ (1,0) [0|0] "" X
 SG_ PMS_applicationCrc m13: 32|32@1+ (1,0) [0|0] "" X
 SG_ PMS_bootloaderSvnRevision m14: 8|24@1+ (1,0) [0|0] "" X
 SG_ PMS_bootloaderSvnUrlHash m14: 32|32@1+ (1,0) [0|0] "" X
 SG_ PMS_appGitHash m17: 10|54@1+ (4,0) [0|0] "" X
 SG_ PMS_bootGitHash m18: 10|54@1+ (4,0) [0|0] "" X
 SG_ PMS_platformTyp m19: 8|8@1+ (1,0) [0|0] "" X
 SG_ PMS_udsProtocolVersion m20: 8|8@1+ (1,0) [0|0] "" X
 SG_ PMS_bootloaderCrc m20: 32|32@1+ (1,0) [0|0] "" X
 SG_ PMS_diNodeBuildType m21: 8|8@1+ (1,0) [0|0] "" X
 SG_ PMS_diNodeBuildConfigurationId m21: 16|16@1+ (1,0) [0|0] "" X
 SG_ PMS_diNodeApplicationCrc m21: 32|32@1+ (1,0) [0|0] "" X

BO_ 1624 PMS_udsResponse: 8 ETH
 SG_ PMS_udsResponseData: 0|54@0+ (1024,0) [0|0] "" X

BO_ 777 PM_alertMatrix1: 8 ETH
 SG_ PM_f001_absoluteTorque: 0|1@1+ (1,0) [0|0] "" X
 SG_ PM_f002_accumulatedTorque: 1|1@1+ (1,0) [0|0] "" X
 SG_ PM_f003_torqueReversal: 2|1@1+ (1,0) [0|0] "" X
 SG_ PM_f004_regenTorque: 3|1@1+ (1,0) [0|0] "" X
 SG_ PM_f005_torqueInNeutral: 4|1@1+ (1,0) [0|0] "" X
 SG_ PM_f006_inconsistentDIGear: 5|1@1+ (1,0) [0|0] "" X
 SG_ PM_f007_watchdogReset: 6|1@1+ (1,0) [0|0] "" X
 SG_ PM_f008_memoryError: 7|1@1+ (1,0) [0|0] "" X
 SG_ PM_f009_espMIA: 8|1@1+ (1,0) [0|0] "" X
 SG_ PM_f010_diMIA: 9|1@1+ (1,0) [0|0] "" X
 SG_ PM_f011_phaseCurrentIrrational: 10|1@1+ (1,0) [0|0] "" X
 SG_ PM_f012_canData: 11|1@1+ (1,0) [0|0] "" X
 SG_ PM_f013_canHardware: 12|1@1+ (1,0) [0|0] "" X
 SG_ PM_f014_accelPedalError: 13|1@1+ (1,0) [0|0] "" X
 SG_ PM_f015_shifterMIA: 14|1@1+ (1,0) [0|0] "" X
 SG_ PM_f016_cruiseMIA: 15|1@1+ (1,0) [0|0] "" X
 SG_ PM_f017_brakeMIA: 16|1@1+ (1,0) [0|0] "" X
 SG_ PM_f018_encoderIrrational: 17|1@1+ (1,0) [0|0] "" X
 SG_ PM_f019_statorTempIrrational: 18|1@1+ (1,0) [0|0] "" X
 SG_ PM_f020_cruiseTorqueExceeded: 19|1@1+ (1,0) [0|0] "" X
 SG_ PM_f021_cruiseSpeedRegulation: 20|1@1+ (1,0) [0|0] "" X
 SG_ PM_f022_crsCmdOnStateOff: 21|1@1+ (1,0) [0|0] "" X
 SG_ PM_f023_crsCmdOffStateOn: 22|1@1+ (1,0) [0|0] "" X
 SG_ PM_f024_brakeIrrational: 23|1@1+ (1,0) [0|0] "" X
 SG_ PM_f025_crsOnBrake: 24|1@1+ (1,0) [0|0] "" X
 SG_ PM_f026_diHeartBeatMIA: 25|1@1+ (1,0) [0|0] "" X
 SG_ PM_f027_torqueOutOfMap: 26|1@1+ (1,0) [0|0] "" X
 SG_ PM_f028_torqueCmdError: 27|1@1+ (1,0) [0|0] "" X
 SG_ PM_f029_limpTorque: 28|1@1+ (1,0) [0|0] "" X
 SG_ PM_f030_inconsistentAebState: 29|1@1+ (1,0) [0|0] "" X
 SG_ PM_f031_highStackUsage: 30|1@1+ (1,0) [0|0] "" X
 SG_ PM_f032_registerConfigError: 31|1@1+ (1,0) [0|0] "" X
 SG_ PM_f033_selfTest: 32|1@1+ (1,0) [0|0] "" X
 SG_ PM_f034_trqCrossCheck: 33|1@1+ (1,0) [0|0] "" X
 SG_ PM_f035_brkMIA: 34|1@1+ (1,0) [0|0] "" X
 SG_ PM_f036_cpcMIA: 35|1@1+ (1,0) [0|0] "" X
 SG_ PM_f037_engMIA: 36|1@1+ (1,0) [0|0] "" X
 SG_ PM_f038_inconsistentTorqueSign: 37|1@1+ (1,0) [0|0] "" X
 SG_ PM_f039_disMIA: 38|1@1+ (1,0) [0|0] "" X
 SG_ PM_f040_pmMIA: 39|1@1+ (1,0) [0|0] "" X
 SG_ PM_f041_dasMIA: 40|1@1+ (1,0) [0|0] "" X
 SG_ PM_f042_gtwMIA: 41|1@1+ (1,0) [0|0] "" X
 SG_ PM_f043_inconsistentConfig: 42|1@1+ (1,0) [0|0] "" X
 SG_ PM_f044_ebrIntervention: 43|1@1+ (1,0) [0|0] "" X
 SG_ PM_f045_spiError: 44|1@1+ (1,0) [0|0] "" X
 SG_ PM_f046_inconsVehicleHoldState: 45|1@1+ (1,0) [0|0] "" X
 SG_ PM_f047_inconsAutoparkState: 46|1@1+ (1,0) [0|0] "" X
 SG_ PM_f048_unexpectedStbCtrl: 47|1@1+ (1,0) [0|0] "" X
 SG_ PM_f049_stbCtrlInWrongDir: 48|1@1+ (1,0) [0|0] "" X
 SG_ PM_f050_excessiveStbCtrlTrq: 49|1@1+ (1,0) [0|0] "" X
 SG_ PM_f051_unintDecelStbCtrl: 50|1@1+ (1,0) [0|0] "" X
 SG_ PM_f052_stbCtrlDrvrDecelCflct: 51|1@1+ (1,0) [0|0] "" X
 SG_ PM_f053_unused: 52|1@1+ (1,0) [0|0] "" X
 SG_ PM_f054_unused: 53|1@1+ (1,0) [0|0] "" X
 SG_ PM_f055_unused: 54|1@1+ (1,0) [0|0] "" X
 SG_ PM_f056_unused: 55|1@1+ (1,0) [0|0] "" X
 SG_ PM_f057_unused: 56|1@1+ (1,0) [0|0] "" X
 SG_ PM_f058_unused: 57|1@1+ (1,0) [0|0] "" X
 SG_ PM_f059_unused: 58|1@1+ (1,0) [0|0] "" X
 SG_ PM_f060_unused: 59|1@1+ (1,0) [0|0] "" X
 SG_ PM_f061_DIPMVersionMismatch: 60|1@1+ (1,0) [0|0] "" X
 SG_ PM_f062_unused: 61|1@1+ (1,0) [0|0] "" X
 SG_ PM_f063_debugAlert: 62|1@1+ (1,0) [0|0] "" X
 SG_ PM_f064_torqueIntervention: 63|1@1+ (1,0) [0|0] "" X

BO_ 888 PM_alertMatrix2: 8 ETH
 SG_ PM_w001_absoluteTorque: 0|1@1+ (1,0) [0|0] "" X
 SG_ PM_w002_accumulatedTorque: 1|1@1+ (1,0) [0|0] "" X
 SG_ PM_w003_torqueReversal: 2|1@1+ (1,0) [0|0] "" X
 SG_ PM_w004_regenTorque: 3|1@1+ (1,0) [0|0] "" X
 SG_ PM_w005_torqueInNeutral: 4|1@1+ (1,0) [0|0] "" X
 SG_ PM_w006_inconsistentDIGear: 5|1@1+ (1,0) [0|0] "" X
 SG_ PM_w007_watchdogReset: 6|1@1+ (1,0) [0|0] "" X
 SG_ PM_w008_memoryError: 7|1@1+ (1,0) [0|0] "" X
 SG_ PM_w009_espMIA: 8|1@1+ (1,0) [0|0] "" X
 SG_ PM_w010_diMIA: 9|1@1+ (1,0) [0|0] "" X
 SG_ PM_w011_phaseCurrentIrrational: 10|1@1+ (1,0) [0|0] "" X
 SG_ PM_w012_canData: 11|1@1+ (1,0) [0|0] "" X
 SG_ PM_w013_canHardware: 12|1@1+ (1,0) [0|0] "" X
 SG_ PM_w014_accelPedalError: 13|1@1+ (1,0) [0|0] "" X
 SG_ PM_w015_shifterMIA: 14|1@1+ (1,0) [0|0] "" X
 SG_ PM_w016_cruiseMIA: 15|1@1+ (1,0) [0|0] "" X
 SG_ PM_w017_brakeMIA: 16|1@1+ (1,0) [0|0] "" X
 SG_ PM_w018_encoderIrrational: 17|1@1+ (1,0) [0|0] "" X
 SG_ PM_w019_statorTempIrrational: 18|1@1+ (1,0) [0|0] "" X
 SG_ PM_w020_cruiseTorqueExceeded: 19|1@1+ (1,0) [0|0] "" X
 SG_ PM_w021_cruiseSpeedRegulation: 20|1@1+ (1,0) [0|0] "" X
 SG_ PM_w022_crsCmdOnStateOff: 21|1@1+ (1,0) [0|0] "" X
 SG_ PM_w023_crsCmdOffStateOn: 22|1@1+ (1,0) [0|0] "" X
 SG_ PM_w024_brakeIrrational: 23|1@1+ (1,0) [0|0] "" X
 SG_ PM_w025_crsOnBrake: 24|1@1+ (1,0) [0|0] "" X
 SG_ PM_w026_diHeartBeatMIA: 25|1@1+ (1,0) [0|0] "" X
 SG_ PM_w027_torqueOutOfMap: 26|1@1+ (1,0) [0|0] "" X
 SG_ PM_w028_torqueCmdError: 27|1@1+ (1,0) [0|0] "" X
 SG_ PM_w029_limpTorque: 28|1@1+ (1,0) [0|0] "" X
 SG_ PM_w030_inconsistentAebState: 29|1@1+ (1,0) [0|0] "" X
 SG_ PM_w031_highStackUsage: 30|1@1+ (1,0) [0|0] "" X
 SG_ PM_w032_registerConfigError: 31|1@1+ (1,0) [0|0] "" X
 SG_ PM_w033_selfTest: 32|1@1+ (1,0) [0|0] "" X
 SG_ PM_w034_trqCrossCheck: 33|1@1+ (1,0) [0|0] "" X
 SG_ PM_w035_brkMIA: 34|1@1+ (1,0) [0|0] "" X
 SG_ PM_w036_cpcMIA: 35|1@1+ (1,0) [0|0] "" X
 SG_ PM_w037_engMIA: 36|1@1+ (1,0) [0|0] "" X
 SG_ PM_w038_inconsistentTorqueSign: 37|1@1+ (1,0) [0|0] "" X
 SG_ PM_w039_disMIA: 38|1@1+ (1,0) [0|0] "" X
 SG_ PM_w040_pmMIA: 39|1@1+ (1,0) [0|0] "" X
 SG_ PM_w041_dasMIA: 40|1@1+ (1,0) [0|0] "" X
 SG_ PM_w042_gtwMIA: 41|1@1+ (1,0) [0|0] "" X
 SG_ PM_w043_inconsistentConfig: 42|1@1+ (1,0) [0|0] "" X
 SG_ PM_w044_ebrIntervention: 43|1@1+ (1,0) [0|0] "" X
 SG_ PM_w045_spiError: 44|1@1+ (1,0) [0|0] "" X
 SG_ PM_w046_inconsVehicleHoldState: 45|1@1+ (1,0) [0|0] "" X
 SG_ PM_w047_inconsAutoparkState: 46|1@1+ (1,0) [0|0] "" X
 SG_ PM_w048_unexpectedStbCtrl: 47|1@1+ (1,0) [0|0] "" X
 SG_ PM_w049_stbCtrlInWrongDir: 48|1@1+ (1,0) [0|0] "" X
 SG_ PM_w050_excessiveStbCtrlTrq: 49|1@1+ (1,0) [0|0] "" X
 SG_ PM_w051_unintDecelStbCtrl: 50|1@1+ (1,0) [0|0] "" X
 SG_ PM_w052_stbCtrlDrvrDecelCflct: 51|1@1+ (1,0) [0|0] "" X
 SG_ PM_w053_unused: 52|1@1+ (1,0) [0|0] "" X
 SG_ PM_w054_unused: 53|1@1+ (1,0) [0|0] "" X
 SG_ PM_w055_unused: 54|1@1+ (1,0) [0|0] "" X
 SG_ PM_w056_unused: 55|1@1+ (1,0) [0|0] "" X
 SG_ PM_w057_unused: 56|1@1+ (1,0) [0|0] "" X
 SG_ PM_w058_unused: 57|1@1+ (1,0) [0|0] "" X
 SG_ PM_w059_unused: 58|1@1+ (1,0) [0|0] "" X
 SG_ PM_w060_unused: 59|1@1+ (1,0) [0|0] "" X
 SG_ PM_w061_DIPMVersionMismatch: 60|1@1+ (1,0) [0|0] "" X
 SG_ PM_w062_unused: 61|1@1+ (1,0) [0|0] "" X
 SG_ PM_w063_debugAlert: 62|1@1+ (1,0) [0|0] "" X
 SG_ PM_w064_torqueIntervention: 63|1@1+ (1,0) [0|0] "" X

BO_ 821 PM_dtcMatrix: 8 ETH
 SG_ PM_dtcIndex M: 0|8@1+ (1,0) [0|0] "" X
 SG_ PM_d001_unused m0: 8|2@1+ (1,0) [0|0] "" X
 SG_ PM_d002_unused m0: 10|2@1+ (1,0) [0|0] "" X
 SG_ PM_d003_unused m0: 12|2@1+ (1,0) [0|0] "" X
 SG_ PM_d004_unused m0: 14|2@1+ (1,0) [0|0] "" X
 SG_ PM_d005_unused m0: 16|2@1+ (1,0) [0|0] "" X
 SG_ PM_d006_unused m0: 18|2@1+ (1,0) [0|0] "" X
 SG_ PM_d007_unused m0: 20|2@1+ (1,0) [0|0] "" X
 SG_ PM_d008_unused m0: 22|2@1+ (1,0) [0|0] "" X
 SG_ PM_d009_unused m0: 24|2@1+ (1,0) [0|0] "" X
 SG_ PM_d010_unused m0: 26|2@1+ (1,0) [0|0] "" X
 SG_ PM_d011_unused m0: 28|2@1+ (1,0) [0|0] "" X
 SG_ PM_d012_unused m0: 30|2@1+ (1,0) [0|0] "" X
 SG_ PM_d013_unused m0: 32|2@1+ (1,0) [0|0] "" X
 SG_ PM_d014_unused m0: 34|2@1+ (1,0) [0|0] "" X
 SG_ PM_d015_unused m0: 36|2@1+ (1,0) [0|0] "" X
 SG_ PM_d016_unused m0: 38|2@1+ (1,0) [0|0] "" X
 SG_ PM_d017_unused m0: 40|2@1+ (1,0) [0|0] "" X
 SG_ PM_d018_unused m0: 42|2@1+ (1,0) [0|0] "" X
 SG_ PM_d019_unused m0: 44|2@1+ (1,0) [0|0] "" X
 SG_ PM_d020_unused m0: 46|2@1+ (1,0) [0|0] "" X
 SG_ PM_d021_unused m0: 48|2@1+ (1,0) [0|0] "" X
 SG_ PM_d022_unused m0: 50|2@1+ (1,0) [0|0] "" X
 SG_ PM_d023_unused m0: 52|2@1+ (1,0) [0|0] "" X
 SG_ PM_d024_unused m0: 54|2@1+ (1,0) [0|0] "" X
 SG_ PM_d025_unused m0: 56|2@1+ (1,0) [0|0] "" X
 SG_ PM_d026_unused m0: 58|2@1+ (1,0) [0|0] "" X
 SG_ PM_d027_unused m0: 60|2@1+ (1,0) [0|0] "" X
 SG_ PM_d028_unused m0: 62|2@1+ (1,0) [0|0] "" X

BO_ 1629 PM_info: 8 ETH
 SG_ PM_infoIndex M: 0|8@1+ (1,0) [0|0] "" X
 SG_ PM_buildType m10: 8|8@1+ (1,0) [0|0] "" X
 SG_ PM_buildConfigurationId m10: 16|16@1+ (1,0) [0|0] "" X
 SG_ PM_hardwareId m10: 32|16@1+ (1,0) [0|0] "" X
 SG_ PM_componentId m10: 48|16@1+ (1,0) [0|0] "" X
 SG_ PM_pcbaId m11: 16|8@1+ (1,0) [0|0] "" X
 SG_ PM_assemblyId m11: 24|8@1+ (1,0) [0|0] "" X
 SG_ PM_usageId m11: 32|16@1+ (1,0) [0|0] "" X
 SG_ PM_subUsageId m11: 48|16@1+ (1,0) [0|0] "" X
 SG_ PM_applicationCrc m13: 32|32@1+ (1,0) [0|0] "" X
 SG_ PM_bootloaderSvnRevision m14: 8|24@1+ (1,0) [0|0] "" X
 SG_ PM_bootloaderSvnUrlHash m14: 32|32@1+ (1,0) [0|0] "" X
 SG_ PM_appGitHash m17: 10|54@1+ (4,0) [0|0] "" X
 SG_ PM_bootGitHash m18: 10|54@1+ (4,0) [0|0] "" X
 SG_ PM_platformTyp m19: 8|8@1+ (1,0) [0|0] "" X
 SG_ PM_udsProtocolVersion m20: 8|8@1+ (1,0) [0|0] "" X
 SG_ PM_bootloaderCrc m20: 32|32@1+ (1,0) [0|0] "" X
 SG_ PM_diNodeBuildType m21: 8|8@1+ (1,0) [0|0] "" X
 SG_ PM_diNodeBuildConfigurationId m21: 16|16@1+ (1,0) [0|0] "" X
 SG_ PM_diNodeApplicationCrc m21: 32|32@1+ (1,0) [0|0] "" X

BO_ 1677 PM_svn: 8 ETH
 SG_ PM_bootloaderVersion: 56|8@1+ (1,0) [0|0] "" X
 SG_ PM_buildFlags: 40|8@1+ (1,0) [0|0] "" X
 SG_ PM_componentSvn: 20|20@1+ (1,0) [0|0] "" X
 SG_ PM_cpldVersion: 48|8@1+ (1,0) [0|0] "" X
 SG_ PM_platformSvn: 0|20@1+ (1,0) [0|0] "" X

BO_ 1556 PM_udsResponse: 8 ETH
 SG_ PM_udsResponseData: 0|54@0+ (1024,0) [0|0] "" X

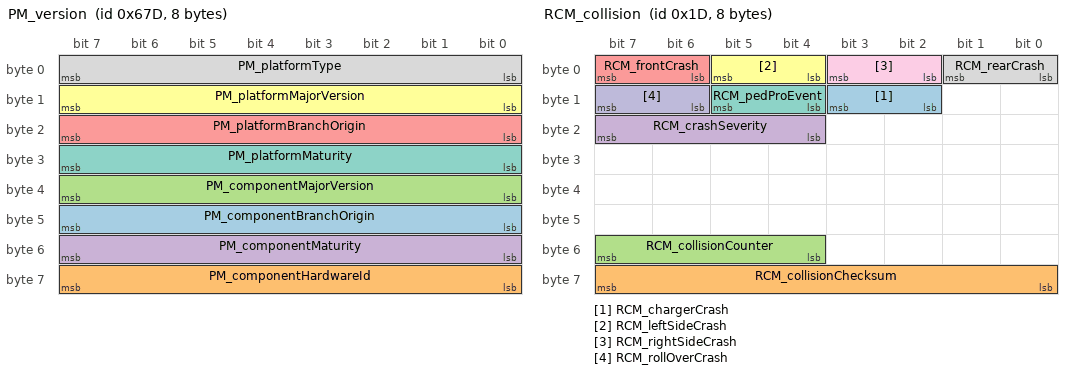
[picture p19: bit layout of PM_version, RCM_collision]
BO_ 1661 PM_version: 8 ETH
 SG_ PM_componentBranchOrigin: 40|8@1+ (1,0) [0|0] "" X
 SG_ PM_componentHardwareId: 56|8@1+ (1,0) [0|0] "" X
 SG_ PM_componentMajorVersion: 32|8@1+ (1,0) [0|0] "" X
 SG_ PM_componentMaturity: 48|8@1+ (1,0) [0|0] "" X
 SG_ PM_platformBranchOrigin: 16|8@1+ (1,0) [0|0] "" X
 SG_ PM_platformMajorVersion: 8|8@1+ (1,0) [0|0] "" X
 SG_ PM_platformMaturity: 24|8@1+ (1,0) [0|0] "" X
 SG_ PM_platformType: 0|8@1+ (1,0) [0|0] "" X

BO_ 1749 PTCR_udsResponse: 8 ETH
 SG_ PTCR_udsResponseData: 0|54@0+ (1024,0) [0|0] "" X

BO_ 1578 PTC_Faults: 8 ETH
 SG_ PTC_FailHighVoltageSensor_Flag: 32|1@1+ (1,0) [0|0] "" X
 SG_ PTC_Failure1stCurrentSensor_Flag: 34|1@1+ (1,0) [0|0] "" X
 SG_ PTC_Failure1stIGBTShort_Flag: 41|1@1+ (1,0) [0|0] "" X
 SG_ PTC_Failure2ndCurrentSensor_Flag: 35|1@1+ (1,0) [0|0] "" X
 SG_ PTC_Failure2ndIGBTShort_Flag: 42|1@1+ (1,0) [0|0] "" X
 SG_ PTC_Failure3rdCurrentSensor_Flag: 36|1@1+ (1,0) [0|0] "" X
 SG_ PTC_Failure3rdIGBTShort_Flag: 43|1@1+ (1,0) [0|0] "" X
 SG_ PTC_FailureLowVoltageSensor_Flag: 33|1@1+ (1,0) [0|0] "" X
 SG_ PTC_FailureOpenIGBTTempSns1: 27|1@1+ (1,0) [0|0] "" X
 SG_ PTC_FailureOpenIGBTTempSns2: 29|1@1+ (1,0) [0|0] "" X
 SG_ PTC_FailureOpenLCoreTempSns: 37|1@1+ (1,0) [0|0] "" X
 SG_ PTC_FailureOpenPCBTempSns1: 39|1@1+ (1,0) [0|0] "" X
 SG_ PTC_FailureOpenPCBTempSns2: 44|1@1+ (1,0) [0|0] "" X
 SG_ PTC_FailureOpenRCoreTempSns: 46|1@1+ (1,0) [0|0] "" X
 SG_ PTC_FailureShortIGBTTempSns1: 28|1@1+ (1,0) [0|0] "" X
 SG_ PTC_FailureShortIGBTTempSns2: 30|1@1+ (1,0) [0|0] "" X
 SG_ PTC_FailureShortLCoreTempSns: 38|1@1+ (1,0) [0|0] "" X
 SG_ PTC_FailureShortPCBTempSns1: 40|1@1+ (1,0) [0|0] "" X
 SG_ PTC_FailureShortPCBTempSns2: 45|1@1+ (1,0) [0|0] "" X
 SG_ PTC_FailureShortRCoreTempSns: 47|1@1+ (1,0) [0|0] "" X
 SG_ PTC_FaultHVHigh_Flag: 11|1@1+ (1,0) [0|0] "" X
 SG_ PTC_FaultHVLow_Flag: 10|1@1+ (1,0) [0|0] "" X
 SG_ PTC_FaultIGBT1ThermalShut_Flag: 19|1@1+ (1,0) [0|0] "" X
 SG_ PTC_FaultIGBT2ThermalShut_Flag: 20|1@1+ (1,0) [0|0] "" X
 SG_ PTC_FaultIGBTDriver_Flag: 21|1@1+ (1,0) [0|0] "" X
 SG_ PTC_FaultLVHigh_Flag: 9|1@1+ (1,0) [0|0] "" X
 SG_ PTC_FaultLVLow_Flag: 8|1@1+ (1,0) [0|0] "" X
 SG_ PTC_FaultLeftThermalShut_Flag: 15|1@1+ (1,0) [0|0] "" X
 SG_ PTC_FaultMsg216Timeout_Flag: 25|1@1+ (1,0) [0|0] "" X
 SG_ PTC_FaultMsg327Timeout_Flag: 24|1@1+ (1,0) [0|0] "" X
 SG_ PTC_FaultPCB1ThermalShut_Flag: 16|1@1+ (1,0) [0|0] "" X
 SG_ PTC_FaultPCB2ThermalShut_Flag: 17|1@1+ (1,0) [0|0] "" X
 SG_ PTC_FaultPtc1OverCurrent_Flag: 12|1@1+ (1,0) [0|0] "" X
 SG_ PTC_FaultPtc2OverCurrent_Flag: 13|1@1+ (1,0) [0|0] "" X
 SG_ PTC_FaultPtc3OverCurrent_Flag: 14|1@1+ (1,0) [0|0] "" X
 SG_ PTC_FaultRightThermalShut_Flag: 18|1@1+ (1,0) [0|0] "" X
 SG_ PTC_LimitedOperationCause_Flag: 48|8@1+ (1,0) [0|0] "" X
 SG_ PTC_PtcFault_Flag: 0|1@1+ (1,0) [0|0] "" X
 SG_ PTC_SoftwareRegion_Num: 4|4@1+ (1,0) [0|0] "" X
 SG_ PTC_SoftwareVersion_Num: 56|8@1+ (1,0) [0|0] "" X
 SG_ PTC_platformMismatch_Flag: 26|1@1+ (1,0) [0|0] "" X

BO_ 616 PTC_THCResponse_partial: 2 ETH
 SG_ PTC_ptcConsumptionPwr_W: 0|16@1+ (1,0) [0|0] "W" X

BO_ 837 PTC_info: 8 ETH
 SG_ PTC_infoIndex M: 0|8@1+ (1,0) [0|0] "" X
 SG_ PTC_infoBuildType m10: 8|8@1+ (1,0) [0|0] "" X
 SG_ PTC_infoBuildConfigID m10: 16|16@1+ (1,0) [0|0] "" X
 SG_ PTC_infoHardwareID m10: 32|16@1+ (1,0) [0|0] "" X
 SG_ PTC_infoComponentID m10: 48|16@1+ (1,0) [0|0] "" X
 SG_ PTC_infoPcbaID m11: 16|8@1+ (1,0) [0|0] "" X
 SG_ PTC_infoAssemblyID m11: 24|8@1+ (1,0) [0|0] "" X
 SG_ PTC_infoUsageID m11: 32|16@1+ (1,0) [0|0] "" X
 SG_ PTC_infoSubUsageID m11: 48|16@1+ (1,0) [0|0] "" X
 SG_ PTC_infoPlatformType m13: 8|8@1+ (1,0) [0|0] "" X
 SG_ PTC_infoApplicationCRC m13: 32|32@1+ (1,0) [0|0] "" X
 SG_ PTC_infoAppGitHashBytes m17: 10|54@1+ (4,0) [0|0] "" X
 SG_ PTC_infoBootGitHashBytes m18: 10|54@1+ (4,0) [0|0] "" X
 SG_ PTC_infoBootUdsProtoVersion m20: 8|8@1+ (1,0) [0|0] "" X
 SG_ PTC_infoBootloaderCRC m20: 32|32@1+ (1,0) [0|0] "" X

BO_ 1750 PTC_udsResponse: 8 ETH
 SG_ PTC_udsResponseData: 0|54@0+ (1024,0) [0|0] "" X

BO_ 1282 RADC_alertMatrix0: 8 ETH
 SG_ RADC_w001_can1BusOff: 1|1@1+ (1,0) [0|0] "" X
 SG_ RADC_w002_ecuAdcError: 2|1@1+ (1,0) [0|0] "" X
 SG_ RADC_w003_ecuBistDisabled: 3|1@1+ (1,0) [0|0] "" X
 SG_ RADC_w004_ecuCrcHwError: 4|1@1+ (1,0) [0|0] "" X
 SG_ RADC_w005_ecuEcuMError: 5|1@1+ (1,0) [0|0] "" X
 SG_ RADC_w006_ecuFimError: 6|1@1+ (1,0) [0|0] "" X
 SG_ RADC_w007_ecuGptCheckError: 7|1@1+ (1,0) [0|0] "" X
 SG_ RADC_w008_ecuHwSwInterlock: 8|1@1+ (1,0) [0|0] "" X
 SG_ RADC_w009_plantModeActive: 9|1@1+ (1,0) [0|0] "" X
 SG_ RADC_w010_ecuIoHwAbError: 10|1@1+ (1,0) [0|0] "" X
 SG_ RADC_w011_ecuMcemError: 11|1@1+ (1,0) [0|0] "" X
 SG_ RADC_w012_ecuSpiError: 12|1@1+ (1,0) [0|0] "" X
 SG_ RADC_w013_ecuWdgError: 13|1@1+ (1,0) [0|0] "" X
 SG_ RADC_w014_fctSelfTestNotDone: 14|1@1+ (1,0) [0|0] "" X
 SG_ RADC_w015_fctSenInterference: 15|1@1+ (1,0) [0|0] "" X
 SG_ RADC_w016_adcOverVolt: 16|1@1+ (1,0) [0|0] "" X
 SG_ RADC_w017_adcUnderVolt: 17|1@1+ (1,0) [0|0] "" X
 SG_ RADC_w018_internalHardwareFault: 18|1@1+ (1,0) [0|0] "" X
 SG_ RADC_w019_internalSoftwareFault: 19|1@1+ (1,0) [0|0] "" X
 SG_ RADC_w020_overTemp: 20|1@1+ (1,0) [0|0] "" X
 SG_ RADC_w021_overTempCrit: 21|1@1+ (1,0) [0|0] "" X
 SG_ RADC_w022_tempImplausible: 22|1@1+ (1,0) [0|0] "" X
 SG_ RADC_w023_underTemp: 23|1@1+ (1,0) [0|0] "" X
 SG_ RADC_w024_underTempCrit: 24|1@1+ (1,0) [0|0] "" X
 SG_ RADC_w025_overVoltage: 25|1@1+ (1,0) [0|0] "" X
 SG_ RADC_w026_underVoltage: 26|1@1+ (1,0) [0|0] "" X
 SG_ RADC_w027_nvmFailure: 27|1@1+ (1,0) [0|0] "" X
 SG_ RADC_w028_rfChipError: 28|1@1+ (1,0) [0|0] "" X
 SG_ RADC_w029_rhcError: 29|1@1+ (1,0) [0|0] "" X
 SG_ RADC_w030_rspError: 30|1@1+ (1,0) [0|0] "" X
 SG_ RADC_w031_sensorMisaligned: 31|1@1+ (1,0) [0|0] "" X
 SG_ RADC_w032_sensorBlocked: 32|1@1+ (1,0) [0|0] "" X
 SG_ RADC_w033_sensorNeverAligned: 33|1@1+ (1,0) [0|0] "" X
 SG_ RADC_w034_vehDynamicsError: 34|1@1+ (1,0) [0|0] "" X
 SG_ RADC_w035_vinMIA: 35|1@1+ (1,0) [0|0] "" X
 SG_ RADC_w036_carConfigMIA: 36|1@1+ (1,0) [0|0] "" X
 SG_ RADC_w037_inertialSignalsMIA: 37|1@1+ (1,0) [0|0] "" X
 SG_ RADC_w038_steeringWheelAngleMIA: 38|1@1+ (1,0) [0|0] "" X
 SG_ RADC_w039_vehicleStateMIA: 39|1@1+ (1,0) [0|0] "" X
 SG_ RADC_w040_wheelSpeedsMIA: 40|1@1+ (1,0) [0|0] "" X
 SG_ RADC_w041_vinErr: 41|1@1+ (1,0) [0|0] "" X
 SG_ RADC_w042_carConfigErr: 42|1@1+ (1,0) [0|0] "" X
 SG_ RADC_w043_inertialSignalsErr: 43|1@1+ (1,0) [0|0] "" X
 SG_ RADC_w044_steeringWheelAngleErr: 44|1@1+ (1,0) [0|0] "" X
 SG_ RADC_w045_vehicleStateErr: 45|1@1+ (1,0) [0|0] "" X
 SG_ RADC_w046_wheelSpeedsErr: 46|1@1+ (1,0) [0|0] "" X
 SG_ RADC_w047_mismatchChassisType: 47|1@1+ (1,0) [0|0] "" X
 SG_ RADC_w048_mismatchAirSuspension: 48|1@1+ (1,0) [0|0] "" X
 SG_ RADC_w049_mismatchFourWheelDrive: 49|1@1+ (1,0) [0|0] "" X
 SG_ RADC_w050_mismatchCountry: 50|1@1+ (1,0) [0|0] "" X
 SG_ RADC_w051_mismatchEPASType: 51|1@1+ (1,0) [0|0] "" X
 SG_ RADC_w052_mismatcRadPos: 52|1@1+ (1,0) [0|0] "" X
 SG_ RADC_w053_emError: 53|1@1+ (1,0) [0|0] "" X
 SG_ RADC_w054_blockageInfo_Frame_1: 54|1@1+ (1,0) [0|0] "" X
 SG_ RADC_w055_blockageInfo_Frame_2: 55|1@1+ (1,0) [0|0] "" X

BO_ 1329 RADC_info: 8 ETH
 SG_ RADC_infoIndex M: 0|8@1+ (1,0) [0|0] "" X
 SG_ RADC_infoPlatformType m19: 8|8@1+ (1,0) [0|0] "" X
 SG_ RADC_infoMajorVersion m19: 16|8@1+ (1,0) [0|0] "" X
 SG_ RADC_infoBranchOrigin m19: 24|8@1+ (1,0) [0|0] "" X
 SG_ RADC_infoMaturity m19: 32|8@1+ (1,0) [0|0] "" X
 SG_ RADC_infoHardwareRevision m19: 40|8@1+ (1,0) [0|0] "" X
 SG_ RADC_infoBuildType m10: 8|8@1+ (1,0) [0|0] "" X
 SG_ RADC_infoBuildConfigID m10: 16|16@1+ (1,0) [0|0] "" X
 SG_ RADC_infoHardwareID m10: 32|16@1+ (1,0) [0|0] "" X
 SG_ RADC_infoComponentID m10: 48|16@1+ (1,0) [0|0] "" X
 SG_ RADC_infoPcbaID m11: 16|8@1+ (1,0) [0|0] "" X
 SG_ RADC_infoAssemblyID m11: 24|8@1+ (1,0) [0|0] "" X
 SG_ RADC_infoUsageID m11: 32|16@1+ (1,0) [0|0] "" X
 SG_ RADC_infoSubUsageID m11: 48|16@1+ (1,0) [0|0] "" X
 SG_ RADC_infoBootUdsProtoVersion m20: 8|8@1+ (1,0) [0|0] "" X
 SG_ RADC_infoBootloaderCRC m20: 32|32@1+ (1,0) [0|0] "" X
 SG_ RADC_infoApplicationCRC m13: 32|32@1+ (1,0) [0|0] "" X

BO_ 1665 RADC_udsResponse: 8 ETH
 SG_ RADC_udsResponseData: 0|54@0+ (1024,0) [0|0] "" X

BO_ 1668 RADFL_udsResponse: 8 ETH
 SG_ RADFL_udsResponseData: 0|54@0+ (1024,0) [0|0] "" X

BO_ 1669 RADFR_udsResponse: 8 ETH
 SG_ RADFR_udsResponseData: 0|54@0+ (1024,0) [0|0] "" X

BO_ 1666 RADRL_udsResponse: 8 ETH
 SG_ RADRL_udsResponseData: 0|54@0+ (1024,0) [0|0] "" X

BO_ 1667 RADRR_udsResponse: 8 ETH
 SG_ RADRR_udsResponseData: 0|54@0+ (1024,0) [0|0] "" X

BO_ 1543 RCCM_Faults: 8 ETH
 SG_ RCCM_FaultAmbientSns_Flag: 34|1@1+ (1,0) [0|0] "" X
 SG_ RCCM_FaultAutoDefogSns_Flag: 37|1@1+ (1,0) [0|0] "" X
 SG_ RCCM_FaultDefAct_Flag: 20|1@1+ (1,0) [0|0] "" X
 SG_ RCCM_FaultDefDuctSns_Flag: 44|1@1+ (1,0) [0|0] "" X
 SG_ RCCM_FaultEvapSns_Flag: 36|1@1+ (1,0) [0|0] "" X
 SG_ RCCM_FaultFloorLeftDuctSns_Flag: 42|1@1+ (1,0) [0|0] "" X
 SG_ RCCM_FaultFloorRightDuctSns_Flag: 43|1@1+ (1,0) [0|0] "" X
 SG_ RCCM_FaultIncarHumiditySns_Flag: 33|1@1+ (1,0) [0|0] "" X
 SG_ RCCM_FaultIncarTempSns_Flag: 32|1@1+ (1,0) [0|0] "" X
 SG_ RCCM_FaultIntakeAct_Flag: 19|1@1+ (1,0) [0|0] "" X
 SG_ RCCM_FaultLftTempAct_Flag: 17|1@1+ (1,0) [0|0] "" X
 SG_ RCCM_FaultModeAct_Flag: 16|1@1+ (1,0) [0|0] "" X
 SG_ RCCM_FaultMsg208Timeout_Flag: 53|1@1+ (1,0) [0|0] "" X
 SG_ RCCM_FaultMsg227Timeout_Flag: 48|1@1+ (1,0) [0|0] "" X
 SG_ RCCM_FaultMsg237Timeout_Flag: 49|1@1+ (1,0) [0|0] "" X
 SG_ RCCM_FaultMsg247Timeout_Flag: 50|1@1+ (1,0) [0|0] "" X
 SG_ RCCM_FaultMsg257Timeout_Flag: 51|1@1+ (1,0) [0|0] "" X
 SG_ RCCM_FaultMsg337Timeout_Flag: 52|1@1+ (1,0) [0|0] "" X
 SG_ RCCM_FaultPhotoSns_Flag: 35|1@1+ (1,0) [0|0] "" X
 SG_ RCCM_FaultPtcTempControlFlag: 21|1@1+ (1,0) [0|0] "" X
 SG_ RCCM_FaultRtTempAct_Flag: 18|1@1+ (1,0) [0|0] "" X
 SG_ RCCM_FaultVentLeftDuctSns_Flag: 40|1@1+ (1,0) [0|0] "" X
 SG_ RCCM_FaultVentRightDuctSns_Flag: 41|1@1+ (1,0) [0|0] "" X
 SG_ RCCM_SoftwareRegion_Num: 8|8@1+ (1,0) [0|0] "" X
 SG_ RCCM_SoftwareVersion_Num: 0|8@1+ (1,0) [0|0] "" X

BO_ 1751 RCCM_udsResponse: 8 ETH
 SG_ RCCM_udsResponseData: 0|54@0+ (1024,0) [0|0] "" X

BO_ 1009 RCM2_alertMatrix: 8 ETH
 SG_ RCM2_matrixIndex M: 0|4@1+ (1,0) [0|0] "" X
 SG_ RCM2_a000_crashDetected m0: 4|1@1+ (1,0) [0|0] "" X
 SG_ RCM2_a001_nearDeploy m0: 5|1@1+ (1,0) [0|0] "" X
 SG_ RCM2_a002_airbagsUnArmed m0: 6|1@1+ (1,0) [0|0] "" X
 SG_ RCM2_a003_warningIndicator m0: 7|1@1+ (1,0) [0|0] "" X
 SG_ RCM2_a004_crashAlgoWakeup m0: 8|1@1+ (1,0) [0|0] "" X
 SG_ RCM2_a005_abuseImmunityThrshold m0: 9|1@1+ (1,0) [0|0] "" X
 SG_ RCM2_a006_supplierDiagEnabled m0: 10|1@1+ (1,0) [0|0] "" X
 SG_ RCM2_a007_pedProCrashDetected m0: 11|1@1+ (1,0) [0|0] "" X
 SG_ RCM2_a008_factoryMode m0: 12|1@1+ (1,0) [0|0] "" X
 SG_ RCM2_a009_edrDataAreaLocked m0: 13|1@1+ (1,0) [0|0] "" X
 SG_ RCM2_a010_pedProEDRDataLocked m0: 14|1@1+ (1,0) [0|0] "" X
 SG_ RCM2_a011_FrntAlgoDisabled m0: 15|1@1+ (1,0) [0|0] "" X
 SG_ RCM2_a012_FrntAlgoDisabled m0: 16|1@1+ (1,0) [0|0] "" X
 SG_ RCM2_a013_FrntAlgoDisabled m0: 17|1@1+ (1,0) [0|0] "" X
 SG_ RCM2_a014_pedProNearDeploy m0: 18|1@1+ (1,0) [0|0] "" X
 SG_ RCM2_a047_batteryESRhigh m0: 19|1@1+ (1,0) [0|0] "" X
 SG_ RCM2_a048_batteryVoltageTooHigh m0: 20|1@1+ (1,0) [0|0] "" X
 SG_ RCM2_a049_batteryVoltageTooLow m0: 21|1@1+ (1,0) [0|0] "" X
 SG_ RCM2_a050_driverABStg1Sht2Gnd m0: 22|1@1+ (1,0) [0|0] "" X
 SG_ RCM2_a051_driverABStg1Sht2Bat m0: 23|1@1+ (1,0) [0|0] "" X
 SG_ RCM2_a052_driverABStg1Open m0: 24|1@1+ (1,0) [0|0] "" X
 SG_ RCM2_a053_driverABStg1Short m0: 25|1@1+ (1,0) [0|0] "" X
 SG_ RCM2_a054_driverABStg1CrssCoup m0: 26|1@1+ (1,0) [0|0] "" X
 SG_ RCM2_a055_driverABStg1Config m0: 27|1@1+ (1,0) [0|0] "" X
 SG_ RCM2_a056_driverABStg2Sht2Gnd m0: 28|1@1+ (1,0) [0|0] "" X
 SG_ RCM2_a057_driverABStg2Sht2Bat m0: 29|1@1+ (1,0) [0|0] "" X
 SG_ RCM2_a058_driverABStg2Open m0: 30|1@1+ (1,0) [0|0] "" X
 SG_ RCM2_a059_driverABStg2Short m0: 31|1@1+ (1,0) [0|0] "" X
 SG_ RCM2_a060_driverABStg2CrssCoup m0: 32|1@1+ (1,0) [0|0] "" X
 SG_ RCM2_a061_driverABStg2Config m0: 33|1@1+ (1,0) [0|0] "" X
 SG_ RCM2_a062_passABStg1Sht2Gnd m0: 34|1@1+ (1,0) [0|0] "" X
 SG_ RCM2_a063_passABStg1Sht2Bat m0: 35|1@1+ (1,0) [0|0] "" X
 SG_ RCM2_a064_passABStg1Open m0: 36|1@1+ (1,0) [0|0] "" X
 SG_ RCM2_a065_passABStg1Short m0: 37|1@1+ (1,0) [0|0] "" X
 SG_ RCM2_a066_passABStg1CrssCoup m0: 38|1@1+ (1,0) [0|0] "" X
 SG_ RCM2_a067_passABStg1Config m0: 39|1@1+ (1,0) [0|0] "" X
 SG_ RCM2_a068_passABStg2Sht2Gnd m0: 40|1@1+ (1,0) [0|0] "" X
 SG_ RCM2_a069_passABStg2Sht2Bat m0: 41|1@1+ (1,0) [0|0] "" X
 SG_ RCM2_a070_passABStg2Open m0: 42|1@1+ (1,0) [0|0] "" X
 SG_ RCM2_a071_passABStg2Short m0: 43|1@1+ (1,0) [0|0] "" X
 SG_ RCM2_a072_passABStg2CrssCoup m0: 44|1@1+ (1,0) [0|0] "" X
 SG_ RCM2_a073_passABStg2Config m0: 45|1@1+ (1,0) [0|0] "" X
 SG_ RCM2_a074_passActiveVentSht2Gnd m0: 46|1@1+ (1,0) [0|0] "" X
 SG_ RCM2_a075_passActiveVentSht2Bat m0: 47|1@1+ (1,0) [0|0] "" X
 SG_ RCM2_a076_passActiveVentOpen m0: 48|1@1+ (1,0) [0|0] "" X
 SG_ RCM2_a077_passActiveVentShort m0: 49|1@1+ (1,0) [0|0] "" X
 SG_ RCM2_a078_passActiveVentCrssCoup m0: 50|1@1+ (1,0) [0|0] "" X
 SG_ RCM2_a079_passActiveVentConfig m0: 51|1@1+ (1,0) [0|0] "" X
 SG_ RCM2_a080_pretenShldLeftSht2Gnd m0: 52|1@1+ (1,0) [0|0] "" X
 SG_ RCM2_a081_pretenShldLeftSht2Bat m0: 53|1@1+ (1,0) [0|0] "" X
 SG_ RCM2_a082_pretenShldLeftOpen m0: 54|1@1+ (1,0) [0|0] "" X
 SG_ RCM2_a083_pretenShldLeftShort m0: 55|1@1+ (1,0) [0|0] "" X
 SG_ RCM2_a084_pretenShldLeftCrossC m0: 56|1@1+ (1,0) [0|0] "" X
 SG_ RCM2_a085_pretenShldLeftConfig m0: 57|1@1+ (1,0) [0|0] "" X
 SG_ RCM2_a086_pretenShldRightSht2Gnd m0: 58|1@1+ (1,0) [0|0] "" X
 SG_ RCM2_a087_pretenShldRightSht2Bat m0: 59|1@1+ (1,0) [0|0] "" X
 SG_ RCM2_a088_pretenShldRightOpen m0: 60|1@1+ (1,0) [0|0] "" X
 SG_ RCM2_a089_pretenShldRightShort m0: 61|1@1+ (1,0) [0|0] "" X
 SG_ RCM2_a090_pretenShldRightCrssCou m0: 62|1@1+ (1,0) [0|0] "" X
 SG_ RCM2_a091_pretenShldRightConfig m0: 63|1@1+ (1,0) [0|0] "" X
 SG_ RCM2_a092_pretenLapLeftSht2Gnd m1: 4|1@1+ (1,0) [0|0] "" X
 SG_ RCM2_a093_pretenLapLeftSht2Bat m1: 5|1@1+ (1,0) [0|0] "" X
 SG_ RCM2_a094_pretenLapLeftOpen m1: 6|1@1+ (1,0) [0|0] "" X
 SG_ RCM2_a095_pretenLapLeftShort m1: 7|1@1+ (1,0) [0|0] "" X
 SG_ RCM2_a096_pretenLapLeftCrssCoup m1: 8|1@1+ (1,0) [0|0] "" X
 SG_ RCM2_a097_pretenLapLeftConfig m1: 9|1@1+ (1,0) [0|0] "" X
 SG_ RCM2_a098_pretenLapRightSht2Gnd m1: 10|1@1+ (1,0) [0|0] "" X
 SG_ RCM2_a099_pretenLapRightSht2Bat m1: 11|1@1+ (1,0) [0|0] "" X
 SG_ RCM2_a100_pretenLapRightOpen m1: 12|1@1+ (1,0) [0|0] "" X
 SG_ RCM2_a101_pretenLapRightShort m1: 13|1@1+ (1,0) [0|0] "" X
 SG_ RCM2_a102_pretenLapRightCrssCoup m1: 14|1@1+ (1,0) [0|0] "" X
 SG_ RCM2_a103_pretenLapRightConfig m1: 15|1@1+ (1,0) [0|0] "" X
 SG_ RCM2_a104_loadLimLeftSht2Gnd m1: 16|1@1+ (1,0) [0|0] "" X
 SG_ RCM2_a105_loadLimLeftSht2Bat m1: 17|1@1+ (1,0) [0|0] "" X
 SG_ RCM2_a106_loadLimLeftOpen m1: 18|1@1+ (1,0) [0|0] "" X
 SG_ RCM2_a107_loadLimLeftShort m1: 19|1@1+ (1,0) [0|0] "" X
 SG_ RCM2_a108_loadLimLeftCrssCoup m1: 20|1@1+ (1,0) [0|0] "" X
 SG_ RCM2_a109_loadLimLeftConfig m1: 21|1@1+ (1,0) [0|0] "" X
 SG_ RCM2_a110_loadLimRightSht2Gnd m1: 22|1@1+ (1,0) [0|0] "" X
 SG_ RCM2_a111_loadLimRightSht2Bat m1: 23|1@1+ (1,0) [0|0] "" X
 SG_ RCM2_a112_loadLimRightOpen m1: 24|1@1+ (1,0) [0|0] "" X
 SG_ RCM2_a113_loadLimRightShort m1: 25|1@1+ (1,0) [0|0] "" X
 SG_ RCM2_a114_loadLimRightCrssCoup m1: 26|1@1+ (1,0) [0|0] "" X
 SG_ RCM2_a115_loadLimRightConfig m1: 27|1@1+ (1,0) [0|0] "" X
 SG_ RCM2_a116_kneeABDrvrSht2Gnd m1: 28|1@1+ (1,0) [0|0] "" X
 SG_ RCM2_a117_kneeABDrvrSht2Bat m1: 29|1@1+ (1,0) [0|0] "" X
 SG_ RCM2_a118_kneeABDrvrOpen m1: 30|1@1+ (1,0) [0|0] "" X
 SG_ RCM2_a119_kneeABDrvrShort m1: 31|1@1+ (1,0) [0|0] "" X
 SG_ RCM2_a120_kneeABDrvrCrssCoup m1: 32|1@1+ (1,0) [0|0] "" X
 SG_ RCM2_a121_kneeABDrvrConfig m1: 33|1@1+ (1,0) [0|0] "" X
 SG_ RCM2_a122_kneeABPassSht2Gnd m1: 34|1@1+ (1,0) [0|0] "" X
 SG_ RCM2_a123_kneeABPassSht2Bat m1: 35|1@1+ (1,0) [0|0] "" X
 SG_ RCM2_a124_kneeABPassOpen m1: 36|1@1+ (1,0) [0|0] "" X
 SG_ RCM2_a125_kneeABPassShort m1: 37|1@1+ (1,0) [0|0] "" X
 SG_ RCM2_a126_kneeABPassCrssCoup m1: 38|1@1+ (1,0) [0|0] "" X
 SG_ RCM2_a127_kneeABPassConfig m1: 39|1@1+ (1,0) [0|0] "" X
 SG_ RCM2_a128_sideAB1stRowLSht2Gnd m1: 40|1@1+ (1,0) [0|0] "" X
 SG_ RCM2_a129_sideAB1stRowLSht2Bat m1: 41|1@1+ (1,0) [0|0] "" X
 SG_ RCM2_a130_sideAB1stRowLOpen m1: 42|1@1+ (1,0) [0|0] "" X
 SG_ RCM2_a131_sideAB1stRowLShort m1: 43|1@1+ (1,0) [0|0] "" X
 SG_ RCM2_a132_sideAB1stRowLCrssCoup m1: 44|1@1+ (1,0) [0|0] "" X
 SG_ RCM2_a133_sideAB1stRowLConfig m1: 45|1@1+ (1,0) [0|0] "" X
 SG_ RCM2_a134_sideAB1stRowRSht2Gnd m1: 46|1@1+ (1,0) [0|0] "" X
 SG_ RCM2_a135_sideAB1stRowRSht2Bat m1: 47|1@1+ (1,0) [0|0] "" X
 SG_ RCM2_a136_sideAB1stRowROpen m1: 48|1@1+ (1,0) [0|0] "" X
 SG_ RCM2_a137_sideAB1stRowRShort m1: 49|1@1+ (1,0) [0|0] "" X
 SG_ RCM2_a138_sideAB1stRowRCrssCoup m1: 50|1@1+ (1,0) [0|0] "" X
 SG_ RCM2_a139_sideAB1stRowRConfig m1: 51|1@1+ (1,0) [0|0] "" X
 SG_ RCM2_a140_driverABAVSht2Gnd m1: 52|1@1+ (1,0) [0|0] "" X
 SG_ RCM2_a141_driverABAVSht2Bat m1: 53|1@1+ (1,0) [0|0] "" X
 SG_ RCM2_a142_driverABAVOpen m1: 54|1@1+ (1,0) [0|0] "" X
 SG_ RCM2_a143_driverABAVShort m1: 55|1@1+ (1,0) [0|0] "" X
 SG_ RCM2_a144_driverABAVCrssCoup m1: 56|1@1+ (1,0) [0|0] "" X
 SG_ RCM2_a145_driverABAVConfig m1: 57|1@1+ (1,0) [0|0] "" X
 SG_ RCM2_a146_curABLeftSht2Gnd m1: 58|1@1+ (1,0) [0|0] "" X
 SG_ RCM2_a147_curABLeftSht2Bat m1: 59|1@1+ (1,0) [0|0] "" X
 SG_ RCM2_a148_curABLeftOpen m1: 60|1@1+ (1,0) [0|0] "" X
 SG_ RCM2_a149_curABLeftShort m1: 61|1@1+ (1,0) [0|0] "" X
 SG_ RCM2_a150_curABLeftCrssCoup m1: 62|1@1+ (1,0) [0|0] "" X
 SG_ RCM2_a151_curABLeftConfig m1: 63|1@1+ (1,0) [0|0] "" X
 SG_ RCM2_a152_curABRightSht2Gnd m2: 4|1@1+ (1,0) [0|0] "" X
 SG_ RCM2_a153_curABRightSht2Bat m2: 5|1@1+ (1,0) [0|0] "" X
 SG_ RCM2_a154_curABRightOpen m2: 6|1@1+ (1,0) [0|0] "" X
 SG_ RCM2_a155_curABRightShort m2: 7|1@1+ (1,0) [0|0] "" X
 SG_ RCM2_a156_curABRightCrssCoup m2: 8|1@1+ (1,0) [0|0] "" X
 SG_ RCM2_a157_curABRightConfig m2: 9|1@1+ (1,0) [0|0] "" X
 SG_ RCM2_a158_preten2ndRowLSht2Gnd m2: 10|1@1+ (1,0) [0|0] "" X
 SG_ RCM2_a159_preten2ndRowLSht2Bat m2: 11|1@1+ (1,0) [0|0] "" X
 SG_ RCM2_a160_preten2ndRowLOpen m2: 12|1@1+ (1,0) [0|0] "" X
 SG_ RCM2_a161_preten2ndRowLShort m2: 13|1@1+ (1,0) [0|0] "" X
 SG_ RCM2_a162_preten2ndRowLCrssCoup m2: 14|1@1+ (1,0) [0|0] "" X
 SG_ RCM2_a163_preten2ndRowLCgf m2: 15|1@1+ (1,0) [0|0] "" X
 SG_ RCM2_a164_preten2ndRowRSht2Gnd m2: 16|1@1+ (1,0) [0|0] "" X
 SG_ RCM2_a165_preten2ndRowRSht2Bat m2: 17|1@1+ (1,0) [0|0] "" X
 SG_ RCM2_a166_preten2ndRowROpen m2: 18|1@1+ (1,0) [0|0] "" X
 SG_ RCM2_a167_preten2ndRowRShort m2: 19|1@1+ (1,0) [0|0] "" X
 SG_ RCM2_a168_preten2ndRowRCrssCoup m2: 20|1@1+ (1,0) [0|0] "" X
 SG_ RCM2_a169_preten2ndRowRCgf m2: 21|1@1+ (1,0) [0|0] "" X
 SG_ RCM2_a170_curAB2ndRowLSht2Gnd m2: 22|1@1+ (1,0) [0|0] "" X
 SG_ RCM2_a171_curAB2ndRowLSht2Bat m2: 23|1@1+ (1,0) [0|0] "" X
 SG_ RCM2_a172_curAB2ndRowLOpen m2: 24|1@1+ (1,0) [0|0] "" X
 SG_ RCM2_a173_curAB2ndRowLShort m2: 25|1@1+ (1,0) [0|0] "" X
 SG_ RCM2_a174_curAB2ndRowLCrssCoup m2: 26|1@1+ (1,0) [0|0] "" X
 SG_ RCM2_a175_curAB2ndRowLConfig m2: 27|1@1+ (1,0) [0|0] "" X
 SG_ RCM2_a176_curAB2ndRowRSht2Gnd m2: 28|1@1+ (1,0) [0|0] "" X
 SG_ RCM2_a177_curAB2ndRowRSht2Bat m2: 29|1@1+ (1,0) [0|0] "" X
 SG_ RCM2_a178_curAB2ndRowROpen m2: 30|1@1+ (1,0) [0|0] "" X
 SG_ RCM2_a179_curAB2ndRowRShort m2: 31|1@1+ (1,0) [0|0] "" X
 SG_ RCM2_a180_curAB2ndRowRCrssCoup m2: 32|1@1+ (1,0) [0|0] "" X
 SG_ RCM2_a181_curAB2ndRowRConfig m2: 33|1@1+ (1,0) [0|0] "" X
 SG_ RCM2_a182_hoodActuatorRSht2Gnd m2: 34|1@1+ (1,0) [0|0] "" X
 SG_ RCM2_a183_hoodActuatorRSht2Bat m2: 35|1@1+ (1,0) [0|0] "" X
 SG_ RCM2_a184_hoodActuatorROpen m2: 36|1@1+ (1,0) [0|0] "" X
 SG_ RCM2_a185_hoodActuatorRShort m2: 37|1@1+ (1,0) [0|0] "" X
 SG_ RCM2_a186_hoodActuatorRCrssCoup m2: 38|1@1+ (1,0) [0|0] "" X
 SG_ RCM2_a187_hoodActuatorRConfig m2: 39|1@1+ (1,0) [0|0] "" X
 SG_ RCM2_a188_hoodActuatorLSht2Gnd m2: 40|1@1+ (1,0) [0|0] "" X
 SG_ RCM2_a189_hoodActuatorLSht2Bat m2: 41|1@1+ (1,0) [0|0] "" X
 SG_ RCM2_a190_hoodActuatorLOpen m2: 42|1@1+ (1,0) [0|0] "" X
 SG_ RCM2_a191_hoodActuatorLShort m2: 43|1@1+ (1,0) [0|0] "" X
 SG_ RCM2_a192_hoodActuatorLCrssCoup m2: 44|1@1+ (1,0) [0|0] "" X
 SG_ RCM2_a193_hoodActuatorLConfig m2: 45|1@1+ (1,0) [0|0] "" X
 SG_ RCM2_a250_ens1Sht2Bat m2: 46|1@1+ (1,0) [0|0] "" X
 SG_ RCM2_a251_ens1Sht2Gnd m2: 47|1@1+ (1,0) [0|0] "" X
 SG_ RCM2_a252_ens1Config m2: 48|1@1+ (1,0) [0|0] "" X
 SG_ RCM2_a253_ens2Sht2Bat m2: 49|1@1+ (1,0) [0|0] "" X
 SG_ RCM2_a254_ens2Sht2Gnd m2: 50|1@1+ (1,0) [0|0] "" X
 SG_ RCM2_a255_ens2Config m2: 51|1@1+ (1,0) [0|0] "" X
 SG_ RCM2_a300_imuAccXHgMonChlPerm m2: 52|1@1+ (1,0) [0|0] "" X
 SG_ RCM2_a301_imuAccXHgMonChlTemp m2: 53|1@1+ (1,0) [0|0] "" X
 SG_ RCM2_a302_imuAccYHgMonChlPerm m2: 54|1@1+ (1,0) [0|0] "" X
 SG_ RCM2_a303_imuAccYHgMonChlTemp m2: 55|1@1+ (1,0) [0|0] "" X
 SG_ RCM2_a304_imuYawR8SnsrPermBG m2: 56|1@1+ (1,0) [0|0] "" X
 SG_ RCM2_a305_imuYawR8SnsrPermInit m2: 57|1@1+ (1,0) [0|0] "" X
 SG_ RCM2_a306_imuYawR8SnsrPermLF m2: 58|1@1+ (1,0) [0|0] "" X
 SG_ RCM2_a307_imuYawR8ChnlMonTmpLF m2: 59|1@1+ (1,0) [0|0] "" X
 SG_ RCM2_a308_imuPitchR8SnsrPermBG m2: 60|1@1+ (1,0) [0|0] "" X
 SG_ RCM2_a309_imuPitchR8SnsrPermInit m2: 61|1@1+ (1,0) [0|0] "" X
 SG_ RCM2_a310_imuPitchR8SnsrPermLF m2: 62|1@1+ (1,0) [0|0] "" X
 SG_ RCM2_a311_imuPitchR8ChnlMonTmpLF m2: 63|1@1+ (1,0) [0|0] "" X
 SG_ RCM2_a312_imuRollR8SnsrPermBG m3: 4|1@1+ (1,0) [0|0] "" X
 SG_ RCM2_a313_imuRollR8SnsrPermInit m3: 5|1@1+ (1,0) [0|0] "" X
 SG_ RCM2_a314_imuRollR8SnsrPermLF m3: 6|1@1+ (1,0) [0|0] "" X
 SG_ RCM2_a315_imuRollR8ChnlMonTmpLF m3: 7|1@1+ (1,0) [0|0] "" X
 SG_ RCM2_a316_imuAccXLgMonChlPerm m3: 8|1@1+ (1,0) [0|0] "" X
 SG_ RCM2_a317_imuAccXLgMonChlTemp m3: 9|1@1+ (1,0) [0|0] "" X
 SG_ RCM2_a318_imuAccYLgMonChlPerm m3: 10|1@1+ (1,0) [0|0] "" X
 SG_ RCM2_a319_imuAccYLgMonChlTemp m3: 11|1@1+ (1,0) [0|0] "" X
 SG_ RCM2_a320_imuAccZLgMonChlPerm m3: 12|1@1+ (1,0) [0|0] "" X
 SG_ RCM2_a321_imuAccZLgMonChlTemp m3: 13|1@1+ (1,0) [0|0] "" X
 SG_ RCM2_a322_imuCalibrationFailed m3: 14|1@1+ (1,0) [0|0] "" X
 SG_ RCM2_a323_imuCalibrationNotDone m3: 15|1@1+ (1,0) [0|0] "" X
 SG_ RCM2_a350_upFrntSnsrLSht2Gnd m3: 16|1@1+ (1,0) [0|0] "" X
 SG_ RCM2_a351_upFrntSnsrLSht2Bat m3: 17|1@1+ (1,0) [0|0] "" X
 SG_ RCM2_a352_upFrntSnsrLOpen m3: 18|1@1+ (1,0) [0|0] "" X
 SG_ RCM2_a353_upFrntSnsrLCrssCoup m3: 19|1@1+ (1,0) [0|0] "" X
 SG_ RCM2_a354_upFrntSnsrLCommErr m3: 20|1@1+ (1,0) [0|0] "" X
 SG_ RCM2_a355_upFrntSnsrLInitTyp m3: 21|1@1+ (1,0) [0|0] "" X
 SG_ RCM2_a356_upFrntSnsrLConfig m3: 22|1@1+ (1,0) [0|0] "" X
 SG_ RCM2_a357_upFrntSnsrLDefect m3: 23|1@1+ (1,0) [0|0] "" X
 SG_ RCM2_a358_upFrntSnsrLSigMon m3: 24|1@1+ (1,0) [0|0] "" X
 SG_ RCM2_a360_upFrntSnsrRSht2Gnd m3: 25|1@1+ (1,0) [0|0] "" X
 SG_ RCM2_a361_upFrntSnsrRSht2Bat m3: 26|1@1+ (1,0) [0|0] "" X
 SG_ RCM2_a362_upFrntSnsrROpen m3: 27|1@1+ (1,0) [0|0] "" X
 SG_ RCM2_a363_upFrntSnsrRCrssCoup m3: 28|1@1+ (1,0) [0|0] "" X
 SG_ RCM2_a364_upFrntSnsrRCommErr m3: 29|1@1+ (1,0) [0|0] "" X
 SG_ RCM2_a365_upFrntSnsrRInitTyp m3: 30|1@1+ (1,0) [0|0] "" X
 SG_ RCM2_a366_upFrntSnsrRConfig m3: 31|1@1+ (1,0) [0|0] "" X
 SG_ RCM2_a367_upFrntSnsrRDefect m3: 32|1@1+ (1,0) [0|0] "" X
 SG_ RCM2_a368_upFrntSnsrRSigMon m3: 33|1@1+ (1,0) [0|0] "" X
 SG_ RCM2_a370_upFrntSnsrMidLSht2Gnd m3: 34|1@1+ (1,0) [0|0] "" X
 SG_ RCM2_a371_upFrntSnsrMidLSht2Bat m3: 35|1@1+ (1,0) [0|0] "" X
 SG_ RCM2_a372_upFrntSnsrMidLOpen m3: 36|1@1+ (1,0) [0|0] "" X
 SG_ RCM2_a373_upFrntSnsrMidLCrssCoup m3: 37|1@1+ (1,0) [0|0] "" X
 SG_ RCM2_a374_upFrntSnsrMidLCommErr m3: 38|1@1+ (1,0) [0|0] "" X
 SG_ RCM2_a375_upFrntSnsrMidLInitTyp m3: 39|1@1+ (1,0) [0|0] "" X
 SG_ RCM2_a376_upFrntSnsrMidLConfig m3: 40|1@1+ (1,0) [0|0] "" X
 SG_ RCM2_a377_upFrntSnsrMidLDefect m3: 41|1@1+ (1,0) [0|0] "" X
 SG_ RCM2_a378_upFrntSnsrMidLSht2Gnd m3: 42|1@1+ (1,0) [0|0] "" X
 SG_ RCM2_a380_upFrntSnsrMidRSht2Gnd m3: 43|1@1+ (1,0) [0|0] "" X
 SG_ RCM2_a381_upFrntSnsrMidRSht2Bat m3: 44|1@1+ (1,0) [0|0] "" X
 SG_ RCM2_a382_upFrntSnsrMidROpen m3: 45|1@1+ (1,0) [0|0] "" X
 SG_ RCM2_a383_upFrntSnsrMidRCrssCoup m3: 46|1@1+ (1,0) [0|0] "" X
 SG_ RCM2_a384_upFrntSnsrMidRCommErr m3: 47|1@1+ (1,0) [0|0] "" X
 SG_ RCM2_a385_upFrntSnsrMidRInitTyp m3: 48|1@1+ (1,0) [0|0] "" X
 SG_ RCM2_a386_upFrntSnsrMidRConfig m3: 49|1@1+ (1,0) [0|0] "" X
 SG_ RCM2_a387_upFrntSnsrMidRDefect m3: 50|1@1+ (1,0) [0|0] "" X
 SG_ RCM2_a388_upFrntSnsrMidRSigMon m3: 51|1@1+ (1,0) [0|0] "" X
 SG_ RCM2_a390_sideAccelBPilLSht2Gnd m3: 52|1@1+ (1,0) [0|0] "" X
 SG_ RCM2_a391_sideAccelBPilLSht2Bat m3: 53|1@1+ (1,0) [0|0] "" X
 SG_ RCM2_a392_sideAccelBPilLOpen m3: 54|1@1+ (1,0) [0|0] "" X
 SG_ RCM2_a393_sideAccelBPilLCLosCoup m3: 55|1@1+ (1,0) [0|0] "" X
 SG_ RCM2_a394_sideAccelBPilLCommErr m3: 56|1@1+ (1,0) [0|0] "" X
 SG_ RCM2_a395_sideAccelBPilLInitTyp m3: 57|1@1+ (1,0) [0|0] "" X
 SG_ RCM2_a396_sideAccelBPilLConfig m3: 58|1@1+ (1,0) [0|0] "" X
 SG_ RCM2_a397_sideAccelBPilLDefect m3: 59|1@1+ (1,0) [0|0] "" X
 SG_ RCM2_a398_sideAccelBPilLSigMon m3: 60|1@1+ (1,0) [0|0] "" X
 SG_ RCM2_a400_sideAccelBPilRSht2Gnd m3: 61|1@1+ (1,0) [0|0] "" X
 SG_ RCM2_a401_sideAccelBPilRSht2Bat m3: 62|1@1+ (1,0) [0|0] "" X
 SG_ RCM2_a402_sideAccelBPilROpen m3: 63|1@1+ (1,0) [0|0] "" X
 SG_ RCM2_a403_sideAccelBPilRCrssCoup m4: 4|1@1+ (1,0) [0|0] "" X
 SG_ RCM2_a404_sideAccelBPilRCommErr m4: 5|1@1+ (1,0) [0|0] "" X
 SG_ RCM2_a405_sideAccelBPilRInitTyp m4: 6|1@1+ (1,0) [0|0] "" X
 SG_ RCM2_a406_sideAccelBPilRConfig m4: 7|1@1+ (1,0) [0|0] "" X
 SG_ RCM2_a407_sideAccelBPilRDefect m4: 8|1@1+ (1,0) [0|0] "" X
 SG_ RCM2_a408_sideAccelBPilRSigMon m4: 9|1@1+ (1,0) [0|0] "" X
 SG_ RCM2_a410_sideAccelCPilLSht2Gnd m4: 10|1@1+ (1,0) [0|0] "" X
 SG_ RCM2_a411_sideAccelCPilLSht2Bat m4: 11|1@1+ (1,0) [0|0] "" X
 SG_ RCM2_a412_sideAccelCPilLOpen m4: 12|1@1+ (1,0) [0|0] "" X
 SG_ RCM2_a413_sideAccelCPilLCrssCoup m4: 13|1@1+ (1,0) [0|0] "" X
 SG_ RCM2_a414_sideAccelCPilLCommErr m4: 14|1@1+ (1,0) [0|0] "" X
 SG_ RCM2_a415_sideAccelCPilLInitTyp m4: 15|1@1+ (1,0) [0|0] "" X
 SG_ RCM2_a416_sideAccelCPilLConfig m4: 16|1@1+ (1,0) [0|0] "" X
 SG_ RCM2_a417_sideAccelCPilLDefect m4: 17|1@1+ (1,0) [0|0] "" X
 SG_ RCM2_a418_sideAccelCPilLSigMon m4: 18|1@1+ (1,0) [0|0] "" X
 SG_ RCM2_a420_sideAccelCPilRSht2Gnd m4: 19|1@1+ (1,0) [0|0] "" X
 SG_ RCM2_a421_sideAccelCPilRSht2Bat m4: 20|1@1+ (1,0) [0|0] "" X
 SG_ RCM2_a422_sideAccelCPilROpen m4: 21|1@1+ (1,0) [0|0] "" X
 SG_ RCM2_a423_sideAccelCPilRCrssCoup m4: 22|1@1+ (1,0) [0|0] "" X
 SG_ RCM2_a424_sideAccelCPilRCommErr m4: 23|1@1+ (1,0) [0|0] "" X
 SG_ RCM2_a425_sideAccelCPilRInitTyp m4: 24|1@1+ (1,0) [0|0] "" X
 SG_ RCM2_a426_sideAccelCPilRConfig m4: 25|1@1+ (1,0) [0|0] "" X
 SG_ RCM2_a427_sideAccelCPilRDefect m4: 26|1@1+ (1,0) [0|0] "" X
 SG_ RCM2_a428_sideAccelCPilRSigMon m4: 27|1@1+ (1,0) [0|0] "" X
 SG_ RCM2_a430_presFrntLDoorSht2Gnd m4: 28|1@1+ (1,0) [0|0] "" X
 SG_ RCM2_a431_presFrntLDoorSht2Bat m4: 29|1@1+ (1,0) [0|0] "" X
 SG_ RCM2_a432_presFrntLDoorOpen m4: 30|1@1+ (1,0) [0|0] "" X
 SG_ RCM2_a433_presFrntLDoorCrssCoup m4: 31|1@1+ (1,0) [0|0] "" X
 SG_ RCM2_a434_presFrntLDoorCommErr m4: 32|1@1+ (1,0) [0|0] "" X
 SG_ RCM2_a435_presFrntLDoorInitTyp m4: 33|1@1+ (1,0) [0|0] "" X
 SG_ RCM2_a436_presFrntLDoorConfig m4: 34|1@1+ (1,0) [0|0] "" X
 SG_ RCM2_a437_presFrntLDoorDefect m4: 35|1@1+ (1,0) [0|0] "" X
 SG_ RCM2_a438_presFrntLDoorSigMon m4: 36|1@1+ (1,0) [0|0] "" X
 SG_ RCM2_a439_presDoorAbsolute1 m4: 37|1@1+ (1,0) [0|0] "" X
 SG_ RCM2_a440_presFrntRDoorSht2Gnd m4: 38|1@1+ (1,0) [0|0] "" X
 SG_ RCM2_a441_presFrntRDoorSht2Bat m4: 39|1@1+ (1,0) [0|0] "" X
 SG_ RCM2_a442_presFrntRDoorOpen m4: 40|1@1+ (1,0) [0|0] "" X
 SG_ RCM2_a443_presFrntRDoorCrssCoup m4: 41|1@1+ (1,0) [0|0] "" X
 SG_ RCM2_a444_presFrntRDoorCommErr m4: 42|1@1+ (1,0) [0|0] "" X
 SG_ RCM2_a445_presFrntRDoorInitTyp m4: 43|1@1+ (1,0) [0|0] "" X
 SG_ RCM2_a446_presFrntRDoorConfig m4: 44|1@1+ (1,0) [0|0] "" X
 SG_ RCM2_a447_presFrntRDoorDefect m4: 45|1@1+ (1,0) [0|0] "" X
 SG_ RCM2_a448_presFrntRDoorSigMon m4: 46|1@1+ (1,0) [0|0] "" X
 SG_ RCM2_a449_presDoorAbsolute2 m4: 47|1@1+ (1,0) [0|0] "" X
 SG_ RCM2_a450_presPedProLSht2Gnd m4: 48|1@1+ (1,0) [0|0] "" X
 SG_ RCM2_a451_presPedProLSht2Bat m4: 49|1@1+ (1,0) [0|0] "" X
 SG_ RCM2_a452_presPedProLOpen m4: 50|1@1+ (1,0) [0|0] "" X
 SG_ RCM2_a453_presPedProLCrssCoup m4: 51|1@1+ (1,0) [0|0] "" X
 SG_ RCM2_a454_presPedProLCommErr m4: 52|1@1+ (1,0) [0|0] "" X
 SG_ RCM2_a455_presPedProLInitTyp m4: 53|1@1+ (1,0) [0|0] "" X
 SG_ RCM2_a456_presPedProLConfig m4: 54|1@1+ (1,0) [0|0] "" X
 SG_ RCM2_a457_presPedProLDefect m4: 55|1@1+ (1,0) [0|0] "" X
 SG_ RCM2_a458_presPedProLSigMon m4: 56|1@1+ (1,0) [0|0] "" X
 SG_ RCM2_a460_presPedProRSht2Gnd m4: 57|1@1+ (1,0) [0|0] "" X
 SG_ RCM2_a461_presPedProRSht2Bat m4: 58|1@1+ (1,0) [0|0] "" X
 SG_ RCM2_a462_presPedProROpen m4: 59|1@1+ (1,0) [0|0] "" X
 SG_ RCM2_a463_presPedProRCrssCoup m4: 60|1@1+ (1,0) [0|0] "" X
 SG_ RCM2_a464_presPedProRCommErr m4: 61|1@1+ (1,0) [0|0] "" X
 SG_ RCM2_a465_presPedProRInitTyp m4: 62|1@1+ (1,0) [0|0] "" X
 SG_ RCM2_a466_presPedProRConfig m4: 63|1@1+ (1,0) [0|0] "" X
 SG_ RCM2_a467_presPedProRDefect m5: 4|1@1+ (1,0) [0|0] "" X
 SG_ RCM2_a468_presPedProRSigMon m5: 5|1@1+ (1,0) [0|0] "" X
 SG_ RCM2_a469_presPedProAbsolute m5: 6|1@1+ (1,0) [0|0] "" X
 SG_ RCM2_a470_upFrntPedProLSht2Gnd m5: 7|1@1+ (1,0) [0|0] "" X
 SG_ RCM2_a471_upFrntPedProLSht2Bat m5: 8|1@1+ (1,0) [0|0] "" X
 SG_ RCM2_a472_upFrntPedProLOpen m5: 9|1@1+ (1,0) [0|0] "" X
 SG_ RCM2_a473_upFrntPedProLCrssCoup m5: 10|1@1+ (1,0) [0|0] "" X
 SG_ RCM2_a474_upFrntPedProLCommErr m5: 11|1@1+ (1,0) [0|0] "" X
 SG_ RCM2_a475_upFrntPedProLIntTyp m5: 12|1@1+ (1,0) [0|0] "" X
 SG_ RCM2_a476_upFrntPedProLConfig m5: 13|1@1+ (1,0) [0|0] "" X
 SG_ RCM2_a477_upFrntPedProLDefect m5: 14|1@1+ (1,0) [0|0] "" X
 SG_ RCM2_a478_upFrntPedProSht2Gnd m5: 15|1@1+ (1,0) [0|0] "" X
 SG_ RCM2_a480_upFrntPedProRSht2Gnd m5: 16|1@1+ (1,0) [0|0] "" X
 SG_ RCM2_a481_upFrntPedProRSht2Bat m5: 17|1@1+ (1,0) [0|0] "" X
 SG_ RCM2_a482_upFrntPedProROpen m5: 18|1@1+ (1,0) [0|0] "" X
 SG_ RCM2_a483_upFrntPedProRCrssCoup m5: 19|1@1+ (1,0) [0|0] "" X
 SG_ RCM2_a484_upFrntPedProRCommErr m5: 20|1@1+ (1,0) [0|0] "" X
 SG_ RCM2_a485_upFrntPedProRIntTyp m5: 21|1@1+ (1,0) [0|0] "" X
 SG_ RCM2_a486_upFrntPedProRConfig m5: 22|1@1+ (1,0) [0|0] "" X
 SG_ RCM2_a487_upFrntPedProRDefect m5: 23|1@1+ (1,0) [0|0] "" X
 SG_ RCM2_a488_upFrntPedProSht2Gnd m5: 24|1@1+ (1,0) [0|0] "" X
 SG_ RCM2_a550_bucklHallLeftSht2Gnd m5: 25|1@1+ (1,0) [0|0] "" X
 SG_ RCM2_a551_bucklHallLeftSht2Bat m5: 26|1@1+ (1,0) [0|0] "" X
 SG_ RCM2_a552_bucklHallLeftOpen m5: 27|1@1+ (1,0) [0|0] "" X
 SG_ RCM2_a553_bucklHallLeftUndef m5: 28|1@1+ (1,0) [0|0] "" X
 SG_ RCM2_a554_bucklHallLeftCrssCoup m5: 29|1@1+ (1,0) [0|0] "" X
 SG_ RCM2_a555_bucklHallLeftConfig m5: 30|1@1+ (1,0) [0|0] "" X
 SG_ RCM2_a556_bucklHallRightSht2Gnd m5: 31|1@1+ (1,0) [0|0] "" X
 SG_ RCM2_a557_bucklHallRightSht2Bat m5: 32|1@1+ (1,0) [0|0] "" X
 SG_ RCM2_a558_bucklHallRightOpen m5: 33|1@1+ (1,0) [0|0] "" X
 SG_ RCM2_a559_bucklHallRightUndef m5: 34|1@1+ (1,0) [0|0] "" X
 SG_ RCM2_a560_bucklHallRightCrssCoup m5: 35|1@1+ (1,0) [0|0] "" X
 SG_ RCM2_a561_bucklHallRightConfig m5: 36|1@1+ (1,0) [0|0] "" X
 SG_ RCM2_a562_seaTrkPosLeftSht2Gnd m5: 37|1@1+ (1,0) [0|0] "" X
 SG_ RCM2_a563_seaTrkPosLeftShtBat m5: 38|1@1+ (1,0) [0|0] "" X
 SG_ RCM2_a564_seaTrkPosLeftOpen m5: 39|1@1+ (1,0) [0|0] "" X
 SG_ RCM2_a565_seaTrkPosLeftUndefined m5: 40|1@1+ (1,0) [0|0] "" X
 SG_ RCM2_a566_seaTrkPosLeftCrssCoup m5: 41|1@1+ (1,0) [0|0] "" X
 SG_ RCM2_a567_seaTrkPosLeftConfig m5: 42|1@1+ (1,0) [0|0] "" X
 SG_ RCM2_a568_occPROSSht2Gnd m5: 43|1@1+ (1,0) [0|0] "" X
 SG_ RCM2_a569_occPROSSht2Bat m5: 44|1@1+ (1,0) [0|0] "" X
 SG_ RCM2_a570_occPROSOpen m5: 45|1@1+ (1,0) [0|0] "" X
 SG_ RCM2_a571_occPROSUndef m5: 46|1@1+ (1,0) [0|0] "" X
 SG_ RCM2_a572_occPROSCrssCoup m5: 47|1@1+ (1,0) [0|0] "" X
 SG_ RCM2_a573_occPROSConfig m5: 48|1@1+ (1,0) [0|0] "" X
 SG_ RCM2_a581_sbrRearNetworkSht2Gnd m5: 49|1@1+ (1,0) [0|0] "" X
 SG_ RCM2_a582_sbrRearNetworkConfig m5: 50|1@1+ (1,0) [0|0] "" X
 SG_ RCM2_a600_comCANinternalTimeout m5: 51|1@1+ (1,0) [0|0] "" X
 SG_ RCM2_a601_comChassisCANInit m5: 52|1@1+ (1,0) [0|0] "" X
 SG_ RCM2_a602_comChassisCANBusOff m5: 53|1@1+ (1,0) [0|0] "" X
 SG_ RCM2_a603_comPARTYCANInit m5: 54|1@1+ (1,0) [0|0] "" X
 SG_ RCM2_a604_comPARTYCANBusOff m5: 55|1@1+ (1,0) [0|0] "" X
 SG_ RCM2_a605_comStwAngStatMIA m5: 56|1@1+ (1,0) [0|0] "" X
 SG_ RCM2_a606_comStwAngStatChkSm m5: 57|1@1+ (1,0) [0|0] "" X
 SG_ RCM2_a607_comStwAngStatCntr m5: 58|1@1+ (1,0) [0|0] "" X
 SG_ RCM2_a608_comDItorque1MIA m5: 59|1@1+ (1,0) [0|0] "" X
 SG_ RCM2_a609_comDItorque1ChkSm m5: 60|1@1+ (1,0) [0|0] "" X
 SG_ RCM2_a610_comDItorque1Cntr m5: 61|1@1+ (1,0) [0|0] "" X
 SG_ RCM2_a611_comDItorque2MIA m5: 62|1@1+ (1,0) [0|0] "" X
 SG_ RCM2_a612_comDItorque2ChkSm m5: 63|1@1+ (1,0) [0|0] "" X
 SG_ RCM2_a613_comDItorque2Cntr m6: 4|1@1+ (1,0) [0|0] "" X
 SG_ RCM2_a614_comESP135MIA m6: 5|1@1+ (1,0) [0|0] "" X
 SG_ RCM2_a615_comESP135ChkSm m6: 6|1@1+ (1,0) [0|0] "" X
 SG_ RCM2_a616_comESP135Cntr m6: 7|1@1+ (1,0) [0|0] "" X
 SG_ RCM2_a617_comESP145MIA m6: 8|1@1+ (1,0) [0|0] "" X
 SG_ RCM2_a618_comESP145ChkSm m6: 9|1@1+ (1,0) [0|0] "" X
 SG_ RCM2_a619_comESP145Cntr m6: 10|1@1+ (1,0) [0|0] "" X
 SG_ RCM2_a620_comInvalidVehicleSpeed m6: 11|1@1+ (1,0) [0|0] "" X
 SG_ RCM2_a621_comESPBMIA m6: 12|1@1+ (1,0) [0|0] "" X
 SG_ RCM2_a622_comESPBChkSm m6: 13|1@1+ (1,0) [0|0] "" X
 SG_ RCM2_a623_comESPBCntr m6: 14|1@1+ (1,0) [0|0] "" X
 SG_ RCM2_a624_comESPCMIA m6: 15|1@1+ (1,0) [0|0] "" X
 SG_ RCM2_a625_comESPCChkSm m6: 16|1@1+ (1,0) [0|0] "" X
 SG_ RCM2_a626_comESPCCntr m6: 17|1@1+ (1,0) [0|0] "" X
 SG_ RCM2_a627_comEPBStatusMIA m6: 18|1@1+ (1,0) [0|0] "" X
 SG_ RCM2_a628_comEPBStatusChkSm m6: 19|1@1+ (1,0) [0|0] "" X
 SG_ RCM2_a629_comEPBStatusCntr m6: 20|1@1+ (1,0) [0|0] "" X
 SG_ RCM2_a630_comGTWACSMIA m6: 21|1@1+ (1,0) [0|0] "" X
 SG_ RCM2_a631_comGTWACSChkSm m6: 22|1@1+ (1,0) [0|0] "" X
 SG_ RCM2_a632_comGTWACSCntr m6: 23|1@1+ (1,0) [0|0] "" X
 SG_ RCM2_a633_comOCS1PMIA m6: 24|1@1+ (1,0) [0|0] "" X
 SG_ RCM2_a634_comOCS1PChkSm m6: 25|1@1+ (1,0) [0|0] "" X
 SG_ RCM2_a635_comOCS1PCntr m6: 26|1@1+ (1,0) [0|0] "" X
 SG_ RCM2_a636_ocsFaulted m6: 27|1@1+ (1,0) [0|0] "" X
 SG_ RCM2_a637_ocsUnknown m6: 28|1@1+ (1,0) [0|0] "" X
 SG_ RCM2_a638_comGTWodoMIA m6: 29|1@1+ (1,0) [0|0] "" X
 SG_ RCM2_a639_comGTWCarStateMIA m6: 30|1@1+ (1,0) [0|0] "" X
 SG_ RCM2_a640_comTPMSStatusCMIA m6: 31|1@1+ (1,0) [0|0] "" X
 SG_ RCM2_a641_comGTWCarConfigMIA m6: 32|1@1+ (1,0) [0|0] "" X
 SG_ RCM2_a642_comVINmessageMIA m6: 33|1@1+ (1,0) [0|0] "" X
 SG_ RCM2_a643_comDASSafetyFrntMIA m6: 34|1@1+ (1,0) [0|0] "" X
 SG_ RCM2_a644_comDASSafetyFrntChkSm m6: 35|1@1+ (1,0) [0|0] "" X
 SG_ RCM2_a645_comDASSafetyFrntCntr m6: 36|1@1+ (1,0) [0|0] "" X
 SG_ RCM2_a646_comDIstateMIA m6: 37|1@1+ (1,0) [0|0] "" X
 SG_ RCM2_a647_comDIstateChkSm m6: 38|1@1+ (1,0) [0|0] "" X
 SG_ RCM2_a648_comDIstateCntr m6: 39|1@1+ (1,0) [0|0] "" X
 SG_ RCM2_a649_comDIstate2MIA m6: 40|1@1+ (1,0) [0|0] "" X
 SG_ RCM2_a650_comDIstate2ChkSm m6: 41|1@1+ (1,0) [0|0] "" X
 SG_ RCM2_a651_comDIstate2Cntr m6: 42|1@1+ (1,0) [0|0] "" X
 SG_ RCM2_a652_ambientTempFaulted m6: 43|1@1+ (1,0) [0|0] "" X
 SG_ RCM2_a653_comGTWESP1MIA m6: 44|1@1+ (1,0) [0|0] "" X
 SG_ RCM2_a654_comGTWESP1ChkSm m6: 45|1@1+ (1,0) [0|0] "" X
 SG_ RCM2_a655_comGTWESP1Cntr m6: 46|1@1+ (1,0) [0|0] "" X
 SG_ RCM2_a750_linInternalTimeout m6: 47|1@1+ (1,0) [0|0] "" X
 SG_ RCM2_a800_cfgMissingCalibration m6: 48|1@1+ (1,0) [0|0] "" X
 SG_ RCM2_a801_cfgImplausConfig m6: 49|1@1+ (1,0) [0|0] "" X
 SG_ RCM2_a802_cfgInvalidConfig m6: 50|1@1+ (1,0) [0|0] "" X
 SG_ RCM2_a803_cfgNotConfigured m6: 51|1@1+ (1,0) [0|0] "" X
 SG_ RCM2_a804_cfgNotProgrammed m6: 52|1@1+ (1,0) [0|0] "" X
 SG_ RCM2_a805_cfgPedProNotProgrammed m6: 53|1@1+ (1,0) [0|0] "" X
 SG_ RCM2_a806_cfgCrashCalPNmissing m6: 54|1@1+ (1,0) [0|0] "" X
 SG_ RCM2_a807_cfgExternalCRCError m6: 55|1@1+ (1,0) [0|0] "" X
 SG_ RCM2_a808_cfgInvalParamLayoutID m6: 56|1@1+ (1,0) [0|0] "" X
 SG_ RCM2_a809_cfgInvalParamTransID m6: 57|1@1+ (1,0) [0|0] "" X
 SG_ RCM2_a810_cfgAlgoVerifySnsrID m6: 58|1@1+ (1,0) [0|0] "" X
 SG_ RCM2_a811_cfgConfigDataInconsist m6: 59|1@1+ (1,0) [0|0] "" X
 SG_ RCM2_a812_swVersionWrong m6: 60|1@1+ (1,0) [0|0] "" X
 SG_ RCM2_a813_vinNotProgrammed m6: 61|1@1+ (1,0) [0|0] "" X
 SG_ RCM2_a850_internalFault_001 m6: 62|1@1+ (1,0) [0|0] "" X
 SG_ RCM2_a851_internalFault_002 m6: 63|1@1+ (1,0) [0|0] "" X
 SG_ RCM2_a852_internalFault_003 m7: 4|1@1+ (1,0) [0|0] "" X
 SG_ RCM2_a853_internalFault_004 m7: 5|1@1+ (1,0) [0|0] "" X
 SG_ RCM2_a854_internalFault_005 m7: 6|1@1+ (1,0) [0|0] "" X
 SG_ RCM2_a855_internalFault_006 m7: 7|1@1+ (1,0) [0|0] "" X
 SG_ RCM2_a856_internalFault_007 m7: 8|1@1+ (1,0) [0|0] "" X
 SG_ RCM2_a857_internalFault_008 m7: 9|1@1+ (1,0) [0|0] "" X
 SG_ RCM2_a858_internalFault_009 m7: 10|1@1+ (1,0) [0|0] "" X
 SG_ RCM2_a859_internalFault_010 m7: 11|1@1+ (1,0) [0|0] "" X
 SG_ RCM2_a860_internalFault_011 m7: 12|1@1+ (1,0) [0|0] "" X
 SG_ RCM2_a861_internalFault_012 m7: 13|1@1+ (1,0) [0|0] "" X
 SG_ RCM2_a862_internalFault_013 m7: 14|1@1+ (1,0) [0|0] "" X
 SG_ RCM2_a863_internalFault_014 m7: 15|1@1+ (1,0) [0|0] "" X
 SG_ RCM2_a864_internalFault_015 m7: 16|1@1+ (1,0) [0|0] "" X
 SG_ RCM2_a865_internalFault_016 m7: 17|1@1+ (1,0) [0|0] "" X
 SG_ RCM2_a866_internalFault_017 m7: 18|1@1+ (1,0) [0|0] "" X
 SG_ RCM2_a867_internalFault_018 m7: 19|1@1+ (1,0) [0|0] "" X
 SG_ RCM2_a868_internalFault_019 m7: 20|1@1+ (1,0) [0|0] "" X
 SG_ RCM2_a869_internalFault_020 m7: 21|1@1+ (1,0) [0|0] "" X
 SG_ RCM2_a870_internalFault_021 m7: 22|1@1+ (1,0) [0|0] "" X
 SG_ RCM2_a871_internalFault_022 m7: 23|1@1+ (1,0) [0|0] "" X
 SG_ RCM2_a872_internalFault_023 m7: 24|1@1+ (1,0) [0|0] "" X
 SG_ RCM2_a873_internalFault_024 m7: 25|1@1+ (1,0) [0|0] "" X
 SG_ RCM2_a874_internalFault_025 m7: 26|1@1+ (1,0) [0|0] "" X
 SG_ RCM2_a875_internalFault_026 m7: 27|1@1+ (1,0) [0|0] "" X
 SG_ RCM2_a876_internalFault_027 m7: 28|1@1+ (1,0) [0|0] "" X
 SG_ RCM2_a877_internalFault_028 m7: 29|1@1+ (1,0) [0|0] "" X
 SG_ RCM2_a878_internalFault_029 m7: 30|1@1+ (1,0) [0|0] "" X
 SG_ RCM2_a879_internalFault_030 m7: 31|1@1+ (1,0) [0|0] "" X
 SG_ RCM2_a880_internalFault_031 m7: 32|1@1+ (1,0) [0|0] "" X
 SG_ RCM2_a881_internalFault_032 m7: 33|1@1+ (1,0) [0|0] "" X
 SG_ RCM2_a882_internalFault_033 m7: 34|1@1+ (1,0) [0|0] "" X
 SG_ RCM2_a883_internalFault_034 m7: 35|1@1+ (1,0) [0|0] "" X
 SG_ RCM2_a884_internalFault_035 m7: 36|1@1+ (1,0) [0|0] "" X
 SG_ RCM2_a885_internalFault_036 m7: 37|1@1+ (1,0) [0|0] "" X
 SG_ RCM2_a886_internalFault_037 m7: 38|1@1+ (1,0) [0|0] "" X
 SG_ RCM2_a887_internalFault_038 m7: 39|1@1+ (1,0) [0|0] "" X
 SG_ RCM2_a888_internalFault_039 m7: 40|1@1+ (1,0) [0|0] "" X
 SG_ RCM2_a889_internalFault_040 m7: 41|1@1+ (1,0) [0|0] "" X
 SG_ RCM2_a890_internalFault_041 m7: 42|1@1+ (1,0) [0|0] "" X
 SG_ RCM2_a891_internalFault_042 m7: 43|1@1+ (1,0) [0|0] "" X
 SG_ RCM2_a892_internalFault_043 m7: 44|1@1+ (1,0) [0|0] "" X
 SG_ RCM2_a893_internalFault_044 m7: 45|1@1+ (1,0) [0|0] "" X
 SG_ RCM2_a894_internalFault_045 m7: 46|1@1+ (1,0) [0|0] "" X
 SG_ RCM2_a895_internalFault_046 m7: 47|1@1+ (1,0) [0|0] "" X
 SG_ RCM2_a896_internalFault_047 m7: 48|1@1+ (1,0) [0|0] "" X
 SG_ RCM2_a897_internalFault_048 m7: 49|1@1+ (1,0) [0|0] "" X
 SG_ RCM2_a898_internalFault_049 m7: 50|1@1+ (1,0) [0|0] "" X
 SG_ RCM2_a899_internalFault_050 m7: 51|1@1+ (1,0) [0|0] "" X
 SG_ RCM2_a900_internalFault_051 m7: 52|1@1+ (1,0) [0|0] "" X
 SG_ RCM2_a901_internalFault_052 m7: 53|1@1+ (1,0) [0|0] "" X
 SG_ RCM2_a902_internalFault_053 m7: 54|1@1+ (1,0) [0|0] "" X
 SG_ RCM2_a903_internalFault_054 m7: 55|1@1+ (1,0) [0|0] "" X
 SG_ RCM2_a904_internalFault_055 m7: 56|1@1+ (1,0) [0|0] "" X
 SG_ RCM2_a905_internalFault_056 m7: 57|1@1+ (1,0) [0|0] "" X
 SG_ RCM2_a906_internalFault_057 m7: 58|1@1+ (1,0) [0|0] "" X
 SG_ RCM2_a907_internalFault_058 m7: 59|1@1+ (1,0) [0|0] "" X
 SG_ RCM2_a908_internalFault_059 m7: 60|1@1+ (1,0) [0|0] "" X
 SG_ RCM2_a909_internalFault_060 m7: 61|1@1+ (1,0) [0|0] "" X
 SG_ RCM2_a910_internalFault_061 m7: 62|1@1+ (1,0) [0|0] "" X
 SG_ RCM2_a911_internalFault_062 m7: 63|1@1+ (1,0) [0|0] "" X
 SG_ RCM2_a912_internalFault_063 m8: 4|1@1+ (1,0) [0|0] "" X
 SG_ RCM2_a913_internalFault_064 m8: 5|1@1+ (1,0) [0|0] "" X
 SG_ RCM2_a914_internalFault_065 m8: 6|1@1+ (1,0) [0|0] "" X
 SG_ RCM2_a915_internalFault_066 m8: 7|1@1+ (1,0) [0|0] "" X
 SG_ RCM2_a916_internalFault_067 m8: 8|1@1+ (1,0) [0|0] "" X
 SG_ RCM2_a917_internalFault_068 m8: 9|1@1+ (1,0) [0|0] "" X
 SG_ RCM2_a918_internalFault_069 m8: 10|1@1+ (1,0) [0|0] "" X
 SG_ RCM2_a919_internalFault_070 m8: 11|1@1+ (1,0) [0|0] "" X
 SG_ RCM2_a920_internalFault_071 m8: 12|1@1+ (1,0) [0|0] "" X
 SG_ RCM2_a921_internalFault_072 m8: 13|1@1+ (1,0) [0|0] "" X
 SG_ RCM2_a922_internalFault_073 m8: 14|1@1+ (1,0) [0|0] "" X
 SG_ RCM2_a923_internalFault_074 m8: 15|1@1+ (1,0) [0|0] "" X
 SG_ RCM2_a924_internalFault_075 m8: 16|1@1+ (1,0) [0|0] "" X
 SG_ RCM2_a925_internalFault_076 m8: 17|1@1+ (1,0) [0|0] "" X
 SG_ RCM2_a926_internalFault_077 m8: 18|1@1+ (1,0) [0|0] "" X
 SG_ RCM2_a927_internalFault_078 m8: 19|1@1+ (1,0) [0|0] "" X
 SG_ RCM2_a928_internalFault_079 m8: 20|1@1+ (1,0) [0|0] "" X
 SG_ RCM2_a929_internalFault_080 m8: 21|1@1+ (1,0) [0|0] "" X
 SG_ RCM2_a930_internalFault_081 m8: 22|1@1+ (1,0) [0|0] "" X
 SG_ RCM2_a931_internalFault_082 m8: 23|1@1+ (1,0) [0|0] "" X
 SG_ RCM2_a932_internalFault_083 m8: 24|1@1+ (1,0) [0|0] "" X
 SG_ RCM2_a933_internalFault_084 m8: 25|1@1+ (1,0) [0|0] "" X
 SG_ RCM2_a934_internalFault_085 m8: 26|1@1+ (1,0) [0|0] "" X
 SG_ RCM2_a935_internalFault_086 m8: 27|1@1+ (1,0) [0|0] "" X
 SG_ RCM2_a936_internalFault_087 m8: 28|1@1+ (1,0) [0|0] "" X
 SG_ RCM2_a937_internalFault_088 m8: 29|1@1+ (1,0) [0|0] "" X
 SG_ RCM2_a938_internalFault_089 m8: 30|1@1+ (1,0) [0|0] "" X
 SG_ RCM2_a939_internalFault_090 m8: 31|1@1+ (1,0) [0|0] "" X
 SG_ RCM2_a940_internalFault_091 m8: 32|1@1+ (1,0) [0|0] "" X
 SG_ RCM2_a941_internalFault_092 m8: 33|1@1+ (1,0) [0|0] "" X
 SG_ RCM2_a942_internalFault_093 m8: 34|1@1+ (1,0) [0|0] "" X
 SG_ RCM2_a943_internalFault_094 m8: 35|1@1+ (1,0) [0|0] "" X
 SG_ RCM2_a944_internalFault_095 m8: 36|1@1+ (1,0) [0|0] "" X
 SG_ RCM2_a945_internalFault_096 m8: 37|1@1+ (1,0) [0|0] "" X
 SG_ RCM2_a946_internalFault_097 m8: 38|1@1+ (1,0) [0|0] "" X
 SG_ RCM2_a947_internalFault_098 m8: 39|1@1+ (1,0) [0|0] "" X
 SG_ RCM2_a948_internalFault_099 m8: 40|1@1+ (1,0) [0|0] "" X
 SG_ RCM2_a949_internalFault_100 m8: 41|1@1+ (1,0) [0|0] "" X
 SG_ RCM2_a950_internalFault_101 m8: 42|1@1+ (1,0) [0|0] "" X
 SG_ RCM2_a951_internalFault_102 m8: 43|1@1+ (1,0) [0|0] "" X
 SG_ RCM2_a952_internalFault_103 m8: 44|1@1+ (1,0) [0|0] "" X
 SG_ RCM2_a953_internalFault_104 m8: 45|1@1+ (1,0) [0|0] "" X
 SG_ RCM2_a954_internalFault_105 m8: 46|1@1+ (1,0) [0|0] "" X
 SG_ RCM2_a955_internalFault_106 m8: 47|1@1+ (1,0) [0|0] "" X
 SG_ RCM2_a956_internalFault_107 m8: 48|1@1+ (1,0) [0|0] "" X
 SG_ RCM2_a957_internalFault_108 m8: 49|1@1+ (1,0) [0|0] "" X
 SG_ RCM2_a958_internalFault_109 m8: 50|1@1+ (1,0) [0|0] "" X
 SG_ RCM2_a959_internalFault_110 m8: 51|1@1+ (1,0) [0|0] "" X
 SG_ RCM2_a960_internalFault_111 m8: 52|1@1+ (1,0) [0|0] "" X
 SG_ RCM2_a961_internalFault_112 m8: 53|1@1+ (1,0) [0|0] "" X
 SG_ RCM2_a962_internalFault_113 m8: 54|1@1+ (1,0) [0|0] "" X
 SG_ RCM2_a963_internalFault_114 m8: 55|1@1+ (1,0) [0|0] "" X
 SG_ RCM2_a964_internalFault_115 m8: 56|1@1+ (1,0) [0|0] "" X
 SG_ RCM2_a965_internalFault_116 m8: 57|1@1+ (1,0) [0|0] "" X
 SG_ RCM2_a966_internalFault_117 m8: 58|1@1+ (1,0) [0|0] "" X
 SG_ RCM2_a967_internalFault_118 m8: 59|1@1+ (1,0) [0|0] "" X
 SG_ RCM2_a968_internalFault_119 m8: 60|1@1+ (1,0) [0|0] "" X
 SG_ RCM2_a969_internalFault_120 m8: 61|1@1+ (1,0) [0|0] "" X
 SG_ RCM2_a970_internalFault_121 m8: 62|1@1+ (1,0) [0|0] "" X
 SG_ RCM2_a971_internalFault_122 m8: 63|1@1+ (1,0) [0|0] "" X
 SG_ RCM2_a972_internalFault_123 m9: 4|1@1+ (1,0) [0|0] "" X
 SG_ RCM2_a973_internalFault_124 m9: 5|1@1+ (1,0) [0|0] "" X
 SG_ RCM2_a974_internalFault_125 m9: 6|1@1+ (1,0) [0|0] "" X
 SG_ RCM2_a975_internalFault_126 m9: 7|1@1+ (1,0) [0|0] "" X
 SG_ RCM2_a976_internalFault_127 m9: 8|1@1+ (1,0) [0|0] "" X
 SG_ RCM2_a977_internalFault_128 m9: 9|1@1+ (1,0) [0|0] "" X
 SG_ RCM2_a978_internalFault_129 m9: 10|1@1+ (1,0) [0|0] "" X
 SG_ RCM2_a979_internalFault_130 m9: 11|1@1+ (1,0) [0|0] "" X
 SG_ RCM2_a980_internalFault_131 m9: 12|1@1+ (1,0) [0|0] "" X
 SG_ RCM2_a981_internalFault_132 m9: 13|1@1+ (1,0) [0|0] "" X
 SG_ RCM2_a982_internalFault_133 m9: 14|1@1+ (1,0) [0|0] "" X
 SG_ RCM2_a983_internalFault_134 m9: 15|1@1+ (1,0) [0|0] "" X
 SG_ RCM2_a984_internalFault_135 m9: 16|1@1+ (1,0) [0|0] "" X
 SG_ RCM2_a985_internalFault_136 m9: 17|1@1+ (1,0) [0|0] "" X
 SG_ RCM2_a986_internalFault_137 m9: 18|1@1+ (1,0) [0|0] "" X
 SG_ RCM2_a987_internalFault_138 m9: 19|1@1+ (1,0) [0|0] "" X
 SG_ RCM2_a988_internalFault_139 m9: 20|1@1+ (1,0) [0|0] "" X
 SG_ RCM2_a989_internalFault_140 m9: 21|1@1+ (1,0) [0|0] "" X
 SG_ RCM2_a990_internalFault_141 m9: 22|1@1+ (1,0) [0|0] "" X

BO_ 29 RCM_collision: 8 ETH
 SG_ RCM_chargerCrash: 10|2@1+ (1,0) [0|0] "" X
 SG_ RCM_collisionChecksum: 56|8@1+ (1,0) [0|0] "" X
 SG_ RCM_collisionCounter: 52|4@1+ (1,0) [0|0] "" X
 SG_ RCM_crashSeverity: 20|4@1+ (1,0) [0|0] "" X
 SG_ RCM_frontCrash: 6|2@1+ (1,0) [0|0] "" X
 SG_ RCM_leftSideCrash: 4|2@1+ (1,0) [0|0] "" X
 SG_ RCM_pedProEvent: 12|2@1+ (1,0) [0|0] "" X
 SG_ RCM_rearCrash: 0|2@1+ (1,0) [0|0] "" X
 SG_ RCM_rightSideCrash: 2|2@1+ (1,0) [0|0] "" X
 SG_ RCM_rollOverCrash: 14|2@1+ (1,0) [0|0] "" X

CM_ BO_ 137 "decoder not implemented - MCU_netFileSyncCell";
CM_ BO_ 137 "decoder not implemented - MCU_netFileSyncWifi";

CM_ BO_ 112 "decoder not implemented - MCU_netMapSearchCell";
CM_ BO_ 112 "decoder not implemented - MCU_netMapSearchWifi";

CM_ BO_ 111 "decoder not implemented - MCU_netMapTilesCell";
CM_ BO_ 111 "decoder not implemented - MCU_netMapTilesWifi";

CM_ BO_ 108 "decoder not implemented - MCU_netOtherCell";
CM_ BO_ 108 "decoder not implemented - MCU_netOtherWifi";

CM_ BO_ 124 "decoder not implemented - MCU_netRdioCell";
CM_ BO_ 124 "decoder not implemented - MCU_netRdioWifi";

CM_ BO_ 109 "decoder not implemented - MCU_netSlackerCell";
CM_ BO_ 109 "decoder not implemented - MCU_netSlackerWifi";

CM_ BO_ 110 "decoder not implemented - MCU_netTuneInCell";
CM_ BO_ 110 "decoder not implemented - MCU_netTuneInWifi";

CM_ BO_ 114 "decoder not implemented - MCU_netBrowserCell";
CM_ BO_ 114 "decoder not implemented - MCU_netBrowserWifi";

CM_ BO_ 118 "decoder not implemented - MCU_netCarLogsCell";
CM_ BO_ 118 "decoder not implemented - MCU_netCarLogsWifi";

CM_ BO_ 117 "decoder not implemented - MCU_netFirmwareCell";
CM_ BO_ 117 "decoder not implemented - MCU_netFirmwareWifi";

CM_ BO_ 113 "decoder not implemented - MCU_netGraceNoteCell";
CM_ BO_ 113 "decoder not implemented - MCU_netGraceNoteWifi";

CM_ BO_ 116 "decoder not implemented - MCU_netImagesCell";
CM_ BO_ 116 "decoder not implemented - MCU_netImagesWifi";

CM_ BO_ 121 "decoder not implemented - MCU_netMapTrafficCell";
CM_ BO_ 121 "decoder not implemented - MCU_netMapTrafficWifi";

CM_ BO_ 119 "decoder not implemented - MCU_netMobileAppCell";
CM_ BO_ 119 "decoder not implemented - MCU_netMobileAppWifi";

CM_ BO_ 120 "decoder not implemented - MCU_netMothershipCell";
CM_ BO_ 120 "decoder not implemented - MCU_netMothershipWifi";

CM_ BO_ 115 "decoder not implemented - MCU_netVoiceRecCell";
CM_ BO_ 115 "decoder not implemented - MCU_netVoiceRecWifi";

BA_DEF_ BO_ "GenMsgSendType" ENUM "Cyclic";
BA_DEF_ BO_ "GenMsgCycleTime" INT 0 60000;

BA_ "GenMsgSendType" BO_ 696 0;
BA_ "GenMsgCycleTime" BO_ 696 1000;

BA_ "GenMsgSendType" BO_ 7 0;
BA_ "GenMsgCycleTime" BO_ 7 1000;

BA_ "GenMsgSendType" BO_ 80 0;
BA_ "GenMsgCycleTime" BO_ 80 500;

BA_ "GenMsgSendType" BO_ 107 0;
BA_ "GenMsgCycleTime" BO_ 107 1000;

BA_ "GenMsgSendType" BO_ 15 0;
BA_ "GenMsgCycleTime" BO_ 15 500;

BA_ "GenMsgSendType" BO_ 106 0;
BA_ "GenMsgCycleTime" BO_ 106 1000;

BA_ "GenMsgSendType" BO_ 584 0;
BA_ "GenMsgCycleTime" BO_ 584 500;

BA_ "GenMsgSendType" BO_ 8 0;
BA_ "GenMsgCycleTime" BO_ 8 1000;

BA_ "GenMsgSendType" BO_ 2043 0;
BA_ "GenMsgCycleTime" BO_ 2043 1000;

BA_ "GenMsgSendType" BO_ 542 0;
BA_ "GenMsgCycleTime" BO_ 542 1000;

BA_ "GenMsgSendType" BO_ 55 0;
BA_ "GenMsgCycleTime" BO_ 55 1000;

BA_ "GenMsgSendType" BO_ 24 0;
BA_ "GenMsgCycleTime" BO_ 24 1000;

BA_ "GenMsgSendType" BO_ 591 0;
BA_ "GenMsgCycleTime" BO_ 591 100;

BA_ "GenMsgSendType" BO_ 600 0;
BA_ "GenMsgCycleTime" BO_ 600 500;

BA_ "GenMsgSendType" BO_ 70 0;
BA_ "GenMsgCycleTime" BO_ 70 1000;

BA_ "GenMsgSendType" BO_ 521 0;
BA_ "GenMsgCycleTime" BO_ 521 100;

BA_ "GenMsgSendType" BO_ 541 0;
BA_ "GenMsgCycleTime" BO_ 541 500;

BA_ "GenMsgSendType" BO_ 581 0;
BA_ "GenMsgCycleTime" BO_ 581 500;

BA_ "GenMsgSendType" BO_ 582 0;
BA_ "GenMsgCycleTime" BO_ 582 500;

BA_ "GenMsgSendType" BO_ 137 0;
BA_ "GenMsgCycleTime" BO_ 137 60000;

BA_ "GenMsgSendType" BO_ 112 0;
BA_ "GenMsgCycleTime" BO_ 112 60000;

BA_ "GenMsgSendType" BO_ 111 0;
BA_ "GenMsgCycleTime" BO_ 111 60000;

BA_ "GenMsgSendType" BO_ 108 0;
BA_ "GenMsgCycleTime" BO_ 108 60000;

BA_ "GenMsgSendType" BO_ 124 0;
BA_ "GenMsgCycleTime" BO_ 124 60000;

BA_ "GenMsgSendType" BO_ 109 0;
BA_ "GenMsgCycleTime" BO_ 109 60000;

BA_ "GenMsgSendType" BO_ 110 0;
BA_ "GenMsgCycleTime" BO_ 110 60000;

BA_ "GenMsgSendType" BO_ 114 0;
BA_ "GenMsgCycleTime" BO_ 114 60000;

BA_ "GenMsgSendType" BO_ 118 0;
BA_ "GenMsgCycleTime" BO_ 118 60000;

BA_ "GenMsgSendType" BO_ 117 0;
BA_ "GenMsgCycleTime" BO_ 117 60000;

BA_ "GenMsgSendType" BO_ 113 0;
BA_ "GenMsgCycleTime" BO_ 113 60000;

BA_ "GenMsgSendType" BO_ 116 0;
BA_ "GenMsgCycleTime" BO_ 116 60000;

BA_ "GenMsgSendType" BO_ 121 0;
BA_ "GenMsgCycleTime" BO_ 121 60000;

BA_ "GenMsgSendType" BO_ 119 0;
BA_ "GenMsgCycleTime" BO_ 119 60000;

BA_ "GenMsgSendType" BO_ 120 0;
BA_ "GenMsgCycleTime" BO_ 120 60000;

BA_ "GenMsgSendType" BO_ 115 0;
BA_ "GenMsgCycleTime" BO_ 115 60000;

BA_ "GenMsgSendType" BO_ 61 0;
BA_ "GenMsgCycleTime" BO_ 61 60000;

BA_ "GenMsgSendType" BO_ 952 0;
BA_ "GenMsgCycleTime" BO_ 952 1000;

BA_ "GenMsgSendType" BO_ 122 0;
BA_ "GenMsgCycleTime" BO_ 122 60000;

BA_ "GenMsgSendType" BO_ 103 0;
BA_ "GenMsgCycleTime" BO_ 103 1000;

BA_ "GenMsgSendType" BO_ 105 0;
BA_ "GenMsgCycleTime" BO_ 105 1000;

BA_ "GenMsgSendType" BO_ 128 0;
BA_ "GenMsgCycleTime" BO_ 128 60000;

BA_ "GenMsgSendType" BO_ 5 0;
BA_ "GenMsgCycleTime" BO_ 5 1000;

BA_ "GenMsgSendType" BO_ 9 0;
BA_ "GenMsgCycleTime" BO_ 9 1000;

BA_ "GenMsgSendType" BO_ 520 0;
BA_ "GenMsgCycleTime" BO_ 520 500;

BA_ "GenMsgSendType" BO_ 130 0;
BA_ "GenMsgCycleTime" BO_ 130 5000;

BA_ "GenMsgSendType" BO_ 139 0;
BA_ "GenMsgCycleTime" BO_ 139 5000;

BA_ "GenMsgSendType" BO_ 17 0;
BA_ "GenMsgCycleTime" BO_ 17 1000;

BA_ "GenMsgSendType" BO_ 953 0;
BA_ "GenMsgCycleTime" BO_ 953 1000;

BA_ "GenMsgSendType" BO_ 752 0;
BA_ "GenMsgCycleTime" BO_ 752 100;

BA_ "GenMsgSendType" BO_ 758 0;
BA_ "GenMsgCycleTime" BO_ 758 500;

BA_ "GenMsgSendType" BO_ 759 0;
BA_ "GenMsgCycleTime" BO_ 759 500;

BA_ "GenMsgSendType" BO_ 799 0;
BA_ "GenMsgCycleTime" BO_ 799 500;

BA_ "GenMsgSendType" BO_ 755 0;
BA_ "GenMsgCycleTime" BO_ 755 500;

BA_ "GenMsgSendType" BO_ 756 0;
BA_ "GenMsgCycleTime" BO_ 756 500;

BA_ "GenMsgSendType" BO_ 766 0;
BA_ "GenMsgCycleTime" BO_ 766 500;

BA_ "GenMsgSendType" BO_ 780 0;
BA_ "GenMsgCycleTime" BO_ 780 500;

BA_ "GenMsgSendType" BO_ 1501 0;
BA_ "GenMsgCycleTime" BO_ 1501 10000;

BA_ "GenMsgSendType" BO_ 847 0;
BA_ "GenMsgCycleTime" BO_ 847 1000;

BA_ "GenMsgSendType" BO_ 771 0;
BA_ "GenMsgCycleTime" BO_ 771 1000;

BA_ "GenMsgSendType" BO_ 1504 0;
BA_ "GenMsgCycleTime" BO_ 1504 10000;

BA_ "GenMsgSendType" BO_ 910 0;
BA_ "GenMsgCycleTime" BO_ 910 1000;

BA_ "GenMsgSendType" BO_ 894 0;
BA_ "GenMsgCycleTime" BO_ 894 1000;

BA_ "GenMsgSendType" BO_ 846 0;
BA_ "GenMsgCycleTime" BO_ 846 100;

BA_ "GenMsgSendType" BO_ 862 0;
BA_ "GenMsgCycleTime" BO_ 862 100;

BA_ "GenMsgSendType" BO_ 897 0;
BA_ "GenMsgCycleTime" BO_ 897 100;

BA_ "GenMsgSendType" BO_ 606 0;
BA_ "GenMsgCycleTime" BO_ 606 100;

BA_ "GenMsgSendType" BO_ 544 0;
BA_ "GenMsgCycleTime" BO_ 544 40;

BA_ "GenMsgSendType" BO_ 590 0;
BA_ "GenMsgCycleTime" BO_ 590 100;

BA_ "GenMsgSendType" BO_ 529 0;
BA_ "GenMsgCycleTime" BO_ 529 40;

BA_ "GenMsgSendType" BO_ 559 0;
BA_ "GenMsgCycleTime" BO_ 559 40;

BA_ "GenMsgSendType" BO_ 814 0;
BA_ "GenMsgCycleTime" BO_ 814 100;

BA_ "GenMsgSendType" BO_ 830 0;
BA_ "GenMsgCycleTime" BO_ 830 100;

BA_ "GenMsgSendType" BO_ 798 0;
BA_ "GenMsgCycleTime" BO_ 798 500;

BA_ "GenMsgSendType" BO_ 782 0;
BA_ "GenMsgCycleTime" BO_ 782 250;

BA_ "GenMsgSendType" BO_ 928 0;
BA_ "GenMsgCycleTime" BO_ 928 1000;

BA_ "GenMsgSendType" BO_ 99 0;
BA_ "GenMsgCycleTime" BO_ 99 100;

BA_ "GenMsgSendType" BO_ 569 0;
BA_ "GenMsgCycleTime" BO_ 569 100;

BA_ "GenMsgSendType" BO_ 1305 0;
BA_ "GenMsgCycleTime" BO_ 1305 1000;

BA_ "GenMsgSendType" BO_ 900 0;
BA_ "GenMsgCycleTime" BO_ 900 1000;

BA_ "GenMsgSendType" BO_ 916 0;
BA_ "GenMsgCycleTime" BO_ 916 1000;

BA_ "GenMsgSendType" BO_ 1748 0;
BA_ "GenMsgCycleTime" BO_ 1748 1000;

BA_ "GenMsgSendType" BO_ 777 0;
BA_ "GenMsgCycleTime" BO_ 777 1000;

BA_ "GenMsgSendType" BO_ 888 0;
BA_ "GenMsgCycleTime" BO_ 888 1000;

BA_ "GenMsgSendType" BO_ 821 0;
BA_ "GenMsgCycleTime" BO_ 821 1000;

BA_ "GenMsgSendType" BO_ 1629 0;
BA_ "GenMsgCycleTime" BO_ 1629 1000;

BA_ "GenMsgSendType" BO_ 1677 0;
BA_ "GenMsgCycleTime" BO_ 1677 1000;

BA_ "GenMsgSendType" BO_ 1661 0;
BA_ "GenMsgCycleTime" BO_ 1661 1000;

BA_ "GenMsgSendType" BO_ 1578 0;
BA_ "GenMsgCycleTime" BO_ 1578 1000;

BA_ "GenMsgSendType" BO_ 616 0;
BA_ "GenMsgCycleTime" BO_ 616 100;

BA_ "GenMsgSendType" BO_ 837 0;
BA_ "GenMsgCycleTime" BO_ 837 1000;

BA_ "GenMsgSendType" BO_ 1282 0;
BA_ "GenMsgCycleTime" BO_ 1282 1000;

BA_ "GenMsgSendType" BO_ 1329 0;
BA_ "GenMsgCycleTime" BO_ 1329 1000;

BA_ "GenMsgSendType" BO_ 1543 0;
BA_ "GenMsgCycleTime" BO_ 1543 500;

BA_ "GenMsgSendType" BO_ 1009 0;
BA_ "GenMsgCycleTime" BO_ 1009 250;

VAL_ 696 MCU_falconDoorGeofenceHeight 255 "FALCON_GEOFENCE_HEIGHT_SNA";
VAL_ 696 MCU_mapLightRow1LeftRequest 0 "NONE" 1 "OFF" 2 "ON";
VAL_ 696 MCU_mapLightRow1RightRequest 0 "NONE" 1 "OFF" 2 "ON";

VAL_ 7 MCU_chargeTerminationPct 1023 "SNA";
VAL_ 7 MCU_chgMode 0 "STANDARD" 1 "MAX_RANGE" 2 "STORAGE" 3 "VARIABLE" 7 "SNA";
VAL_ 7 MCU_domeLightReq 0 "OFF" 1 "ON" 2 "AUTO";
VAL_ 7 MCU_espModeSwitch 0 "SWITCH_NOT_PRESSED" 1 "SWITCH_00_PRESSED_NORMAL" 2 "SNA" 3 "SWITCH_01_PRESSED_TC_OFF" 4 "SWITCH_02_PRESSED_ESP_DEV_1" 5 "SWITCH_03_PRESSED_ESP_DEV_2";
VAL_ 7 MCU_factoryMode 0 "NORMAL_MODE" 1 "FACTORY_MODE";
VAL_ 7 MCU_frontFogSwitch 0 "OFF" 1 "ON";
VAL_ 7 MCU_lightSwitch 0 "AUTO_LIGHT_SWITCH_SNA" 1 "ON_LIGHT_SWITCH" 2 "PARK_ONLY_LIGHT_SWITCH" 3 "OFF_LIGHT_SWITCH";
VAL_ 7 MCU_pedalCalRxEnable 0 "DISABLED" 1 "ENABLED";
VAL_ 7 MCU_pedalCalTargetCurve 0 "PEDAL_CURVE_0" 1 "PEDAL_CURVE_1" 2 "PEDAL_CURVE_2" 3 "PEDAL_CURVE_3" 4 "PEDAL_CURVE_4" 5 "PEDAL_CURVE_5" 6 "SNA";
VAL_ 7 MCU_powerOff 0 "SNA";
VAL_ 7 MCU_rearFogSwitch 0 "OFF" 1 "ON";
VAL_ 7 MCU_requestCloseChargePortDoor 0 "NO_DOOR_CLOSE_COMMAND" 1 "CLOSE_DOOR_COMMAND";
VAL_ 7 MCU_requestOpenChargePortDoor 0 "NO_DOOR_COMMAND" 1 "OPEN_DOOR_COMMAND";

VAL_ 80 MCU_accOvertakeEnable 0 "ACC_OVERTAKE_OFF" 1 "ACC_OVERTAKE_ON" 3 "SNA";
VAL_ 80 MCU_aebEnable 0 "AEB_OFF" 1 "AEB_ON" 3 "SNA";
VAL_ 80 MCU_aesEnable 0 "AES_OFF" 1 "AES_ON" 3 "SNA";
VAL_ 80 MCU_ahlbEnable 0 "AHLB_OFF" 1 "AHLB_ON" 3 "SNA";
VAL_ 80 MCU_autoLaneChangeEnable 0 "OFF" 1 "ON" 3 "SNA";
VAL_ 80 MCU_autoParkRequest 0 "NONE" 1 "PARK_LEFT_PARALLEL" 2 "PARK_LEFT_CROSS" 3 "PARK_RIGHT_PARALLEL" 4 "PARK_RIGHT_CROSS" 5 "PARALLEL_PULL_OUT_TO_LEFT" 6 "PARALLEL_PULL_OUT_TO_RIGHT" 7 "ABORT" 8 "COMPLETE" 9 "SEARCH" 10 "PAUSE" 11 "RESUME" 15 "SNA";
VAL_ 80 MCU_bsdEnable 0 "BSD_OFF" 1 "BSD_ON" 3 "SNA";
VAL_ 80 MCU_enableCreepTorqueCH 0 "OFF" 1 "ON";
VAL_ 80 MCU_fcwEnable 0 "FCW_OFF" 1 "FCW_ON" 3 "SNA";
VAL_ 80 MCU_fcwSensitivity 0 "AEB_SENSITIVITY_EARLY" 1 "AEB_SENSITIVITY_AVERAGE" 2 "AEB_SENSITIVITY_LATE" 3 "SNA";
VAL_ 80 MCU_frontDefrostReq_das 0 "OFF" 1 "ON" 3 "SNA";
VAL_ 80 MCU_latControlEnable 0 "OFF" 1 "ON" 2 "UNAVAILABLE" 3 "SNA";
VAL_ 80 MCU_ldwEnable 0 "NO_HAPTIC" 1 "LDW_TRIGGERS_HAPTIC" 3 "SNA";
VAL_ 80 MCU_overPaintedUSS 0 "NOMINAL" 1 "OVER_PAINTED" 2 "UNUSED" 3 "SNA";
VAL_ 80 MCU_parkBrakeRequest 0 "IDLE" 1 "PRESSED" 3 "SNA";
VAL_ 80 MCU_parkSetting 0 "PARK_ASSIST_OFF" 1 "PARK_ASSIST_ON" 2 "UNUSED" 3 "SNA";
VAL_ 80 MCU_pedalSafetyEnable 0 "PEDAL_SAFETY_OFF" 1 "PEDAL_SAFETY_ON" 3 "SNA";
VAL_ 80 MCU_redLightStopSignEnable 0 "RLSSW_OFF" 1 "RLSSW_ON" 3 "SNA";
VAL_ 80 MCU_selfParkTune 15 "SNA";
VAL_ 80 MCU_towModeEnable 0 "IDLE" 1 "ENABLE" 2 "DISABLE" 3 "SNA";
VAL_ 80 MCU_trailerModeCH 0 "OFF" 1 "ON";
VAL_ 80 MCU_zeroSpeedConfirmed 0 "CANCELED" 1 "CONFIRMED" 2 "UNUSED" 3 "SNA";

VAL_ 107 MCU_cidPassengerAirbagTellTale 0 "OFF" 1 "ON" 2 "FLASHING";
VAL_ 107 MCU_cidRearSeatbeltTellTale 0 "OFF" 1 "ON" 2 "FLASHING";

VAL_ 15 MCU_clusterReadyForDrive 0 "NO_SNA" 1 "YES";

VAL_ 106 MCU_absTellTale 0 "OFF" 1 "ON" 2 "FLASHING";
VAL_ 106 MCU_afsTellTale 0 "OFF" 1 "ON" 2 "FLASHING";
VAL_ 106 MCU_airbagTellTale 0 "OFF" 1 "ON" 2 "FLASHING";
VAL_ 106 MCU_brakesTellTale 0 "OFF" 1 "RED" 2 "YELLOW";
VAL_ 106 MCU_doorsTellTale 0 "OFF" 1 "ON" 2 "FLASHING";
VAL_ 106 MCU_frontFogTellTale 0 "OFF" 1 "ON" 2 "FLASHING";
VAL_ 106 MCU_headlightTellTale 0 "OFF" 1 "ON" 2 "FLASHING";
VAL_ 106 MCU_highbeamTellTale 0 "OFF" 1 "ON" 2 "FLASHING";
VAL_ 106 MCU_parkBrakeRedTellTale 0 "OFF" 1 "ON" 2 "FLASHING";
VAL_ 106 MCU_parkBrakeYellowTellTale 0 "OFF" 1 "ON" 2 "FLASHING";
VAL_ 106 MCU_parkingLightTellTale 0 "OFF" 1 "ON" 2 "FLASHING";
VAL_ 106 MCU_passengerAirbagTellTale 0 "OFF" 1 "ON" 2 "FLASHING";
VAL_ 106 MCU_rearFogTellTale 0 "OFF" 1 "ON" 2 "FLASHING";
VAL_ 106 MCU_seatbeltAirbagTellTale 0 "OFF" 1 "ON" 2 "FLASHING";
VAL_ 106 MCU_suspensionRedTellTale 0 "OFF" 1 "ON" 2 "FLASHING";
VAL_ 106 MCU_suspensionYellowTellTale 0 "OFF" 1 "ON" 2 "FLASHING";
VAL_ 106 MCU_tpmsTellTale 0 "OFF" 1 "ON" 2 "FLASHING";
VAL_ 106 MCU_tractionControlOffTellTale 0 "OFF" 1 "ON" 2 "FLASHING";
VAL_ 106 MCU_tractionControlTellTale 0 "OFF" 1 "ON" 2 "FLASHING";

VAL_ 584 MCU_commandsKey 65535 "SNA";
VAL_ 584 MCU_foldMirrors 0 "IDLE" 1 "PRESENT" 2 "RETRACT" 3 "SNA";
VAL_ 584 MCU_frontHoodCommand 0 "NO_ACTION" 1 "GOTO_OPEN" 2 "CALIBRATE";
VAL_ 584 MCU_frontWiperDefrostReq 0 "OFF" 1 "ON" 3 "SNA";
VAL_ 584 MCU_liftgateSwitch 0 "NOT_PRESSED" 1 "PRESSED" 2 "CLOSE" 3 "SNA";
VAL_ 584 MCU_lockRequest 0 "IDLE" 1 "MCU_LOCK" 2 "MCU_UNLOCK" 3 "REMOTE_UNLOCK" 4 "REMOTE_LOCK" 7 "SNA";
VAL_ 584 MCU_panicCommand 0 "NO_ACTION" 1 "START_PANIC" 2 "STOP_PANIC";
VAL_ 584 MCU_rearDefrostRequest 0 "OFF" 1 "ON" 3 "SNA";
VAL_ 584 MCU_remoteClosureRequest 0 "IDLE" 1 "FRUNK_OPEN" 2 "TRUNK_GOTO_OPEN_PERCENT" 3 "TRUNK_OPEN" 4 "TRUNK_CLOSE" 5 "TRUNK_MOVE" 6 "TRUNK_STOP" 7 "FRONT_RIGHT_DOOR_GOTO_OPEN_PERCENT" 8 "FRONT_RIGHT_DOOR_OPEN" 9 "FRONT_RIGHT_DOOR_CLOSE" 10 "FRONT_RIGHT_DOOR_MOVE" 11 "FRONT_RIGHT_DOOR_STOP" 12 "FRONT_LEFT_DOOR_GOTO_OPEN_PERCENT" 13 "FRONT_LEFT_DOOR_OPEN" 14 "FRONT_LEFT_DOOR_CLOSE" 15 "FRONT_LEFT_DOOR_MOVE" 16 "FRONT_LEFT_DOOR_STOP" 17 "FALCON_RIGHT_DOOR_GOTO_OPEN_PERCENT" 18 "FALCON_RIGHT_DOOR_OPEN" 19 "FALCON_RIGHT_DOOR_CLOSE" 20 "FALCON_RIGHT_DOOR_MOVE" 21 "FALCON_RIGHT_DOOR_STOP" 22 "FALCON_LEFT_DOOR_GOTO_OPEN_PERCENT" 23 "FALCON_LEFT_DOOR_OPEN" 24 "FALCON_LEFT_DOOR_CLOSE" 25 "FALCON_LEFT_DOOR_MOVE" 26 "FALCON_LEFT_DOOR_STOP" 31 "SNA";
VAL_ 584 MCU_remoteStartRequest 0 "IDLE" 1 "START" 3 "SNA";
VAL_ 584 MCU_summonState 0 "IDLE" 1 "ACTIVE" 3 "SNA";
VAL_ 584 MCU_wiperMode 0 "WIPER_MODE_NORMAL" 1 "WIPER_MODE_PARK" 2 "WIPER_MODE_SERVICE" 7 "SNA";

VAL_ 2041 MCU_debugEcuTarget 0 "BMS" 1 "DI" 2 "DIS" 3 "PM" 4 "PMS" 5 "THC" 6 "CP" 7 "CHG" 8 "CHGS";

VAL_ 2043 MCU_debugTasTarget 0 "FLAGS" 1 "FRONTAXLE" 2 "REARAXLE";

VAL_ 542 MCU_closeAllRequest 0 "NO_ACTION_SNA" 1 "GOTO_PERCENT_OPEN" 2 "GOTO_CLOSED" 3 "GOTO_OPEN" 4 "STOP" 5 "MANUAL_OVERRIDE" 6 "GOTO_QUICK_OPEN";
VAL_ 542 MCU_closureEasterEggStatus 0 "IDLE" 1 "REQ_RECD_WAITING" 2 "PLAYING";
VAL_ 542 MCU_falconDoorDriverCommand 0 "NO_ACTION_SNA" 1 "GOTO_PERCENT_OPEN" 2 "GOTO_CLOSED" 3 "GOTO_OPEN" 4 "STOP" 5 "MANUAL_OVERRIDE" 6 "GOTO_QUICK_OPEN";
VAL_ 542 MCU_falconDoorPassengerCommand 0 "NO_ACTION_SNA" 1 "GOTO_PERCENT_OPEN" 2 "GOTO_CLOSED" 3 "GOTO_OPEN" 4 "STOP" 5 "MANUAL_OVERRIDE" 6 "GOTO_QUICK_OPEN";
VAL_ 542 MCU_frontDoorDriverCommand 0 "NO_ACTION_SNA" 1 "GOTO_PERCENT_OPEN" 2 "GOTO_CLOSED" 3 "GOTO_OPEN" 4 "STOP" 5 "MANUAL_OVERRIDE" 6 "GOTO_QUICK_OPEN";
VAL_ 542 MCU_frontDoorPassengerCommand 0 "NO_ACTION_SNA" 1 "GOTO_PERCENT_OPEN" 2 "GOTO_CLOSED" 3 "GOTO_OPEN" 4 "STOP" 5 "MANUAL_OVERRIDE" 6 "GOTO_QUICK_OPEN";
VAL_ 542 MCU_spoilerCommand 0 "NO_ACTION_SNA" 1 "GOTO_RETRACTED" 2 "GOTO_AERO" 3 "GOTO_VISION" 4 "CALIBRATE";

VAL_ 55 MCU_disableAntiClunkRequest 0 "ON" 1 "OFF";
VAL_ 55 MCU_distanceUnits 0 "miles" 1 "km" 3 "SNA";
VAL_ 55 MCU_forwardSpeedMax 2047 "SNA";
VAL_ 55 MCU_limitMode 0 "NORMAL" 1 "VALET" 2 "FACTORY";
VAL_ 55 MCU_mechPowerLimit 31 "SNA";
VAL_ 55 MCU_motorOnMode 0 "NORMAL" 1 "FRONT_ONLY" 2 "REAR_ONLY";
VAL_ 55 MCU_performanceMode 0 "STANDARD" 1 "PERFORMANCE" 2 "COMFORT";
VAL_ 55 MCU_regenTorqueMax 127 "SNA";
VAL_ 55 MCU_systemTorqueLimit 63 "SNA";
VAL_ 55 MCU_tractionControlMode 0 "NORMAL_SELECTED" 1 "SLIP_START_SELECTED" 2 "DEV_MODE_1_SELECTED" 3 "DEV_MODE_2_SELECTED" 4 "ROLLS_MODE_SELECTED" 5 "DYNO_MODE_SELECTED";
VAL_ 55 MCU_trailerModePT 0 "OFF" 1 "ON";
VAL_ 55 UI_mapSpeedLimitTick 255 "SNA";

VAL_ 591 MCU_frontEasyEntryRequestColumn 0 "EASY_ENTRY_IDLE" 1 "EASY_ENTRY_REVERSE" 2 "GOTO_EASY_ENTRY";
VAL_ 591 MCU_frontEasyEntryRequestSeat 0 "EASY_ENTRY_IDLE" 1 "EASY_ENTRY_REVERSE" 2 "GOTO_EASY_ENTRY";

VAL_ 600 MCU_recallMirrorCommand 0 "NO_ACTION" 1 "RECALL_POSITION1" 2 "RECALL_POSITION2" 3 "RECALL_POSITION3" 4 "RECALL_POSITION4" 5 "RECALL_POSITION5" 6 "RECALL_POSITION6" 7 "RECALL_POSITION7" 8 "RECALL_POSITION8" 9 "RECALL_POSITION9" 10 "RECALL_POSITION10";
VAL_ 600 MCU_stopRecallMirrorCommand 0 "NOT_ACTIVE" 1 "ACTIVE";
VAL_ 600 MCU_storeMirrorCommand 0 "NO_ACTION" 1 "STORE_POSITION1" 2 "STORE_POSITION2" 3 "STORE_POSITION3" 4 "STORE_POSITION4" 5 "STORE_POSITION5" 6 "STORE_POSITION6" 7 "STORE_POSITION7" 8 "STORE_POSITION8" 9 "STORE_POSITION9" 10 "STORE_POSITION10";

VAL_ 521 MCU_antiPanicRequest 0 "NO_REQUEST" 1 "ANTIPANIC_REQUEST" 2 "UNUSED" 3 "SNA";
VAL_ 521 MCU_easyEntryEnable 0 "EASY_ENTRY_DISABLE" 1 "EASY_ENTRY_ENABLE" 2 "UNUSED" 3 "SNA";
VAL_ 521 MCU_easyExitEnable 0 "EASY_EXIT_DISABLE" 1 "EASY_EXIT_ENABLE" 2 "UNUSED" 3 "SNA";
VAL_ 521 MCU_movementEnable 0 "MOVEMENT_ENABLE" 1 "MOVEMENT_DISABLE" 2 "UNUSED" 3 "SNA";
VAL_ 521 MCU_positionRecall 0 "NO_ACTION" 1 "RECALL_POSITION1" 2 "RECALL_POSITION2" 3 "RECALL_POSITION3" 4 "RECALL_POSITION4" 5 "RECALL_POSITION5" 6 "RECALL_POSITION6" 7 "RECALL_POSITION7" 8 "RECALL_POSITION8" 9 "RECALL_POSITION9" 10 "RECALL_POSITION10" 15 "SNA";
VAL_ 521 MCU_positionStore 0 "NO_ACTION" 1 "STORE_POSITION1" 2 "STORE_POSITION2" 3 "STORE_POSITION3" 4 "STORE_POSITION4" 5 "STORE_POSITION5" 6 "STORE_POSITION6" 7 "STORE_POSITION7" 8 "STORE_POSITION8" 9 "STORE_POSITION9" 10 "STORE_POSITION10" 15 "SNA";

VAL_ 541 MCU_driverComfortFunctionSel 0 "IDLE" 1 "MENU SELECTION" 2 "LUMBAR" 3 "BOLSTER" 4 "HEAD-CUSHION" 8 "SNA";
VAL_ 541 MCU_driverGoToEasyEntryPos 0 "SEAT_DRIVER_STAY" 1 "GO_TO_EASY_ENTRY_POSITION" 2 "BACK_TO_DRIVER_POSITION" 3 "DRIVER_EASY_ENTRY_SNA";
VAL_ 541 MCU_driverPositionRecall 0 "NO_ACTION" 1 "RECALL_POSITION1" 2 "RECALL_POSITION2" 3 "RECALL_POSITION3" 4 "RECALL_POSITION4" 5 "RECALL_POSITION5" 6 "RECALL_POSITION6" 7 "RECALL_POSITION7" 8 "RECALL_POSITION8" 9 "RECALL_POSITION9" 10 "RECALL_POSITION10" 15 "SNA";
VAL_ 541 MCU_driverPositionStore 0 "NO_ACTION" 1 "STORE_POSITION1" 2 "STORE_POSITION2" 3 "STORE_POSITION3" 4 "STORE_POSITION4" 5 "STORE_POSITION5" 6 "STORE_POSITION6" 7 "STORE_POSITION7" 8 "STORE_POSITION8" 9 "STORE_POSITION9" 10 "STORE_POSITION10" 15 "SNA";
VAL_ 541 MCU_msmdMovementEnable 0 "ENABLE" 1 "AUTO_DISABLE" 2 "ALL_DISABLE" 3 "SNA";
VAL_ 541 MCU_msmpMovementEnable 0 "ENABLE" 1 "AUTO_DISABLE" 2 "ALL_DISABLE" 3 "SNA";
VAL_ 541 MCU_msmpdAntiPanicRequest 0 "NO_REQUEST" 1 "ANTIPANIC_REQUEST" 2 "UNUSED" 3 "SNA";
VAL_ 541 MCU_passengerComfortFunctionSel 0 "IDLE" 1 "MENU SELECTION" 2 "LUMBAR" 3 "BOLSTER" 4 "HEAD-CUSHION" 8 "SNA";
VAL_ 541 MCU_passengerGoToEasyEntryPos 0 "SEAT_PASSENGER_STAY" 1 "GO_TO_EASY_ENTRY_POSITION" 2 "BACK_TO_PASSENGER_POSITION" 3 "PASSENGER_EASY_ENTRY_SNA";
VAL_ 541 MCU_passengerPositionRecall 0 "NO_ACTION" 1 "RECALL_POSITION1" 2 "RECALL_POSITION2" 3 "RECALL_POSITION3" 4 "RECALL_POSITION4" 5 "RECALL_POSITION5" 6 "RECALL_POSITION6" 7 "RECALL_POSITION7" 8 "RECALL_POSITION8" 9 "RECALL_POSITION9" 10 "RECALL_POSITION10" 15 "SNA";
VAL_ 541 MCU_passengerPositionStore 0 "NO_ACTION" 1 "STORE_POSITION1" 2 "STORE_POSITION2" 3 "STORE_POSITION3" 4 "STORE_POSITION4" 5 "STORE_POSITION5" 6 "STORE_POSITION6" 7 "STORE_POSITION7" 8 "STORE_POSITION8" 9 "STORE_POSITION9" 10 "STORE_POSITION10" 15 "SNA";

VAL_ 581 MCU_driverHeadrestCommand 127 "MCU_DRIVER_HEADREST_CMD_SNA";
VAL_ 581 MCU_driverHeadrestManualMode 0 "DISABLE" 1 "ENABLE" 3 "SNA";
VAL_ 581 MCU_driverLumbarHCommand 127 "MCU_DRIVER_LUMBAR_HORIZ_CMD_SNA";
VAL_ 581 MCU_driverLumbarVCommand 127 "MCU_DRIVER_LUMBAR_VERT_CMD_SNA";
VAL_ 581 MCU_passengerHeadrestCommand 127 "MCU_PASSENGER_HEADREST_CMD_SNA";
VAL_ 581 MCU_passengerHeadrestManualMode 0 "DISABLE" 1 "ENABLE" 3 "SNA";
VAL_ 581 MCU_passengerLumbarHCommand 127 "MCU_PASSENGER_LUMBAR_HORIZ_CMD_SNA";
VAL_ 581 MCU_passengerLumbarVCommand 127 "MCU_PASSENGER_LUMBAR_VERT_CMD_SNA";

VAL_ 582 MCU_driverBackrestTargetTemp 31 "MCU_DRIVER_BACKREST_TARGET_TEMP_SNA";
VAL_ 582 MCU_driverBackrestVentDuty 127 "MCU_DRIVER_BACKREST_VENT_DUTY_SNA";
VAL_ 582 MCU_driverCushionTargetTemp 31 "MCU_DRIVER_CUSHION_TARGET_TEMP_SNA";
VAL_ 582 MCU_driverCushionVentDuty 127 "MCU_DRIVER_CUSHION_VENT_DUTY_SNA";
VAL_ 582 MCU_passengerBackrestTargetTemp 31 "MCU_PASSENGER_BACKREST_TARGET_TEMP_SNA";
VAL_ 582 MCU_passengerBackrestVentDuty 127 "MCU_PASSENGER_BACKREST_VENT_DUTY_SNA";
VAL_ 582 MCU_passengerCushionTargetTemp 31 "MCU_PASSENGER_CUSHION_TARGET_TEMP_SNA";
VAL_ 582 MCU_passengerCushionVentDuty 127 "MCU_PASSENGER_CUSHION_VENT_DUTY_SNA";

VAL_ 61 MCU_odometer 4294967295 "SNA";

VAL_ 952 MCU_powerExpected 255 "SNA";
VAL_ 952 MCU_powerIdeal 255 "SNA";

VAL_ 103 MCU_soe 127 "SNA";
VAL_ 103 MCU_uSoe 127 "SNA";

VAL_ 105 MCU_clusterInstantOn 0 "ALLOW_CLUSTER_OFF_SNA";
VAL_ 105 MCU_dragStripModeReq 0 "DRAGSTRIP_OFF" 1 "MAX_BATT_MODE" 2 "PERF_EGG_PREPARE" 3 "PERF_EGG_ENABLED";
VAL_ 105 MCU_gatewaySleepReq 0 "DONT_SLEEP" 1 "OK_TO_START" 2 "SLEEP_NOW" 3 "LOW_POWER_SLEEP" 7 "SNA";
VAL_ 105 MCU_requestBusWake 1 "BUS_AWAKE_NOW" 2 "BUS_MAY_SLEEP_NOW" 3 "SNA";
VAL_ 105 MCU_requestChargeEnable 1 "ENABLE";
VAL_ 105 MCU_requestLineChargeCurrent 255 "SNA";

VAL_ 128 MCU_deepSleepMinutes 0 "AWAYMODE" 30 "TRANSPORT" 720 "FACTORY" 5760 "DEFAULT" 10080 "EXTENDED" 16382 "NEVER" 16383 "SNA";
VAL_ 128 MCU_loweringSpeed 125 "NEVER" 126 "ALWAYS" 127 "SNA";

VAL_ 5 MCU_ersLeftZone1 0 "OFF" 1 "LOW" 2 "MEDIUM" 3 "HIGH";
VAL_ 5 MCU_ersLeftZone2 0 "OFF" 1 "LOW" 2 "MEDIUM" 3 "HIGH";
VAL_ 5 MCU_ersLeftZone3 0 "OFF" 1 "LOW" 2 "MEDIUM" 3 "HIGH";
VAL_ 5 MCU_ersLeftZone4 0 "OFF" 1 "LOW" 2 "MEDIUM" 3 "HIGH";
VAL_ 5 MCU_ersRightZone1 0 "OFF" 1 "LOW" 2 "MEDIUM" 3 "HIGH";
VAL_ 5 MCU_ersRightZone2 0 "OFF" 1 "LOW" 2 "MEDIUM" 3 "HIGH";
VAL_ 5 MCU_ersRightZone3 0 "OFF" 1 "LOW" 2 "MEDIUM" 3 "HIGH";
VAL_ 5 MCU_ersRightZone4 0 "OFF" 1 "LOW" 2 "MEDIUM" 3 "HIGH";

VAL_ 9 MCU_timeZoneMinutes -1 "SNA";

VAL_ 520 MCU_sunCommand 0 "NO_ACTION_SNA" 1 "GOTO_PERCENT_OPEN" 2 "GOTO_CLOSED" 3 "GOTO_OPEN" 4 "GOTO_VENT" 5 "CALIBRATE" 6 "STOP" 7 "MANUAL_OVERRIDE";

VAL_ 133 MCU_setRcpFront 255 "SNA";
VAL_ 133 MCU_setRcpRear 255 "SNA";

VAL_ 130 MCU_energyAtDestination -32768 "SNA" -32767 "TRIP_TOO_LONG";
VAL_ 130 MCU_hindsightEnergy -32768 "SNA" -32767 "TRIP_TOO_LONG";
VAL_ 130 MCU_predictedEnergy -32768 "SNA" -32767 "TRIP_TOO_LONG";

VAL_ 139 MCU_maxSpeedToReachDestination 65533 "MAXVAL" 65534 "UNREACHABLE" 65535 "SNA";
VAL_ 139 MCU_remainingWeightedRMSSpeed 65534 "MAXVAL" 65535 "SNA";

VAL_ 17 MCU_mLockDelaySeconds 31 "SNA";

VAL_ 752 MCU_driverFrontWindowCommand 0 "NO_ACTION" 1 "GOTO_OPEN_PERCENT" 2 "GOTO_OPEN" 3 "GOTO_CLOSED" 4 "CALIBRATE";
VAL_ 752 MCU_driverRearWindowCommand 0 "NO_ACTION" 1 "GOTO_OPEN_PERCENT" 2 "GOTO_OPEN" 3 "GOTO_CLOSED" 4 "CALIBRATE";
VAL_ 752 MCU_passFrontWindowCommand 0 "NO_ACTION" 1 "GOTO_OPEN_PERCENT" 2 "GOTO_OPEN" 3 "GOTO_CLOSED" 4 "CALIBRATE";
VAL_ 752 MCU_passRearWindowCommand 0 "NO_ACTION" 1 "GOTO_OPEN_PERCENT" 2 "GOTO_OPEN" 3 "GOTO_CLOSED" 4 "CALIBRATE";

VAL_ 759 MSMD_headrestPosition 2047 "MSMD_HEADREST_POS_SNA";
VAL_ 759 MSMD_lumbarHPosition 2047 "MSMD_LUMBAR_HORIZ_POS_SNA";
VAL_ 759 MSMD_lumbarVPosition 2047 "MSMD_LUMBAR_VERT_POS_SNA";

VAL_ 799 MSMD_1RcommandStatus 0 "IDLE" 1 "SUCCESS" 2 "FAIL" 3 "SNA";
VAL_ 799 MSMD_InitStatus 0 "INIT_STATUS_NO_FAULT" 1 "INIT_STATUS_FAULT" 3 "FAULT_STATUS_SNA";
VAL_ 799 MSMD_VBatComfortStatus 0 "NO_FAULT" 1 "FAULT" 3 "SNA";
VAL_ 799 MSMD_VBatMotorStatus 0 "NO_FAULT" 1 "FAULT" 3 "SNA";
VAL_ 799 MSMD_antiPanicStatus 0 "INACTIVE" 1 "ACTIVE" 2 "UNUSED" 3 "SNA";
VAL_ 799 MSMD_comfortMoveStatus 0 "NOT_ACTIVE" 1 "ACTIVE" 2 "UNUSED" 3 "SNA";
VAL_ 799 MSMD_coolingStatus 0 "COOLING_OFF" 1 "COOLING_ON" 2 "COOLING_FAIL" 3 "SNA";
VAL_ 799 MSMD_faultStatus 0 "NO_FAULTS" 1 "FAULT_WARNING" 2 "FAULT_FAILURE" 3 "SNA";
VAL_ 799 MSMD_heatingStatus 0 "HEATING_OFF" 1 "HEATING_ON" 2 "HEATING_FAIL" 3 "SNA";
VAL_ 799 MSMD_recallStatus 0 "NOT_ACTIVE" 1 "RECALL_ACTIVE" 2 "RECALL_SUCCESS" 3 "SNA";
VAL_ 799 MSMD_seatMoveStatus 0 "NOT_ACTIVE" 1 "ACTIVE" 2 "2NDRACTIVE" 3 "SNA";
VAL_ 799 MSMD_smartSwitchPressReq 0 "SMS_BUTTON_NOT_PRESSED" 1 "SMS_BUTTON_UP" 2 "SMS_BUTTON_FORWARD" 3 "SMS_BUTTON_DOWN" 4 "SMS_BUTTON_BACKWARD" 5 "SMS_BUTTON_CENTRAL" 7 "SNA";
VAL_ 799 MSMD_storageStatus 0 "NOT_ACTIVE" 1 "STORAGE_ACTIVE" 2 "STORAGE_SUCCESS" 3 "SNA";

VAL_ 756 MSMP_headrestPosition 2047 "MSMP_HEADREST_POS_SNA";
VAL_ 756 MSMP_lumbarHPosition 2047 "MSMP_LUMBAR_HORIZ_POS_SNA";
VAL_ 756 MSMP_lumbarVPosition 2047 "MSMP_LUMBAR_VERT_POS_SNA";

VAL_ 766 MSMP_1RcommandStatus 0 "IDLE" 1 "SUCCESS" 2 "FAIL" 3 "SNA";
VAL_ 766 MSMP_InitStatus 0 "INIT_STATUS_NO_FAULT" 1 "INIT_STATUS_FAULT" 3 "FAULT_STATUS_SNA";
VAL_ 766 MSMP_VBatComfortStatus 0 "NO_FAULT" 1 "FAULT" 3 "SNA";
VAL_ 766 MSMP_VBatMotorStatus 0 "NO_FAULT" 1 "FAULT" 3 "SNA";
VAL_ 766 MSMP_antiPanicStatus 0 "INACTIVE" 1 "ACTIVE" 2 "UNUSED" 3 "SNA";
VAL_ 766 MSMP_comfortMoveStatus 0 "NOT_ACTIVE" 1 "ACTIVE" 2 "UNUSED" 3 "SNA";
VAL_ 766 MSMP_coolingStatus 0 "COOLING_OFF" 1 "COOLING_ON" 2 "COOLING_FAIL" 3 "SNA";
VAL_ 766 MSMP_faultStatus 0 "NO_FAULTS" 1 "FAULT_WARNING" 2 "FAULT_FAILURE" 3 "SNA";
VAL_ 766 MSMP_heatingStatus 0 "HEATING_OFF" 1 "HEATING_ON" 2 "HEATING_FAIL" 3 "SNA";
VAL_ 766 MSMP_recallStatus 0 "NOT_ACTIVE" 1 "RECALL_ACTIVE" 2 "RECALL_SUCCESS" 3 "SNA";
VAL_ 766 MSMP_seatMoveStatus 0 "NOT_ACTIVE" 1 "ACTIVE" 2 "2NDRACTIVE" 3 "SNA";
VAL_ 766 MSMP_smartSwitchPressReq 0 "SMS_BUTTON_NOT_PRESSED" 1 "SMS_BUTTON_UP" 2 "SMS_BUTTON_FORWARD" 3 "SMS_BUTTON_DOWN" 4 "SMS_BUTTON_BACKWARD" 5 "SMS_BUTTON_CENTRAL" 7 "SNA";
VAL_ 766 MSMP_storageStatus 0 "NOT_ACTIVE" 1 "STORAGE_ACTIVE" 2 "STORAGE_SUCCESS" 3 "SNA";

VAL_ 780 MSM_antiPanicStatus 0 "ANTI_PANIC_INACTIVE" 1 "ANTI_PANIC_ACTIVE" 2 "UNUSED" 3 "SNA";
VAL_ 780 MSM_columnMoveStatus 0 "NOT_ACTIVE" 1 "ACTIVE" 2 "UNUSED" 3 "SNA";
VAL_ 780 MSM_faultStatus 0 "NO_FAULTS" 1 "FAULT_WARNING" 2 "FAULT_FAILURE" 3 "SNA";
VAL_ 780 MSM_recallStatus 0 "NOT_ACTIVE" 1 "RECALL_ACTIVE" 2 "RECALL_SUCCESS" 3 "SNA";
VAL_ 780 MSM_seatMoveStatus 0 "NOT_ACTIVE" 1 "ACTIVE" 2 "UNUSED" 3 "SNA";
VAL_ 780 MSM_storageStatus 0 "NOT_ACTIVE" 1 "STORAGE_ACTIVE" 2 "STORAGE_SUCCESS" 3 "SNA";

VAL_ 1501 MSMP_versionMajor 255 "SNA";
VAL_ 1501 MSMP_versionMinor 255 "SNA";
VAL_ 1501 MSM_versionMajor 255 "SNA";
VAL_ 1501 MSM_versionMinor 255 "SNA";

VAL_ 847 OCS_calibID 1 "S" 2 "X";
VAL_ 847 OCS_occupantClass 0 "UNKNOWN" 1 "EMPTY" 2 "OCCUPIED INHIBIT" 3 "OCCUPIED_ALLOW_SMALL" 4 "OCCUPIED_ALLOW_LARGE" 5 "INVALID1" 6 "INVALID2" 7 "FAULTED";
VAL_ 847 OCS_sdmSerialNoReceived 0 "NOT_RECEIVED" 1 "RECEIVED";

VAL_ 771 OCS_calibrationID 1 "S" 2 "X";
VAL_ 771 OCS_occupantClassification 0 "UNKNOWN" 1 "EMPTY" 2 "OCCUPIED INHIBIT" 3 "OCCUPIED_ALLOW_SMALL" 4 "OCCUPIED_ALLOW_LARGE" 5 "INVALID1" 6 "INVALID2" 7 "FAULTED";

VAL_ 846 PARK_frontLeftMiddleRawDistData 255 "SNA";
VAL_ 846 PARK_frontMiddleRawDistData 255 "SNA";
VAL_ 846 PARK_frontRightMiddleRawDistData 255 "SNA";

VAL_ 862 PARK_rearLeftMiddleRawDistData 255 "SNA";
VAL_ 862 PARK_rearMiddleRawDistData 255 "SNA";
VAL_ 862 PARK_rearRightMiddleRawDistData 255 "SNA";

VAL_ 897 PARK_leftSideFrontRawDistData 255 "SNA";
VAL_ 897 PARK_leftSideRearRawDistData 255 "SNA";
VAL_ 897 PARK_rightSideFrontRawDistData 255 "SNA";
VAL_ 897 PARK_rightSideRearRawDistData 255 "SNA";

VAL_ 606 PARK_pscEnvSlotType 0 "LEFT_PARALLEL" 1 "LEFT_CROSS" 2 "RIGHT_PARALLEL" 3 "RIGHT_CROSS";
VAL_ 606 PARK_pscLeftParallelObj1X 2046 "NO_SPACE" 2047 "SNA";
VAL_ 606 PARK_pscLeftParallelObj1Y 2046 "NO_SPACE" 2047 "SNA";
VAL_ 606 PARK_pscLeftParallelObj1Alpha 126 "NO_SPACE" 127 "SNA";
VAL_ 606 PARK_pscLeftParallelObj2Y 2046 "NO_SPACE" 2047 "SNA";
VAL_ 606 PARK_pscLeftParallelObj2X 2046 "NO_SPACE" 2047 "SNA";
VAL_ 606 PARK_pscLeftParallelObj2Alpha 126 "NO_SPACE" 127 "SNA";
VAL_ 606 PARK_pscLeftCrossObj1X 2046 "NO_SPACE" 2047 "SNA";
VAL_ 606 PARK_pscLeftCrossObj1Y 2046 "NO_SPACE" 2047 "SNA";
VAL_ 606 PARK_pscLeftCrossObj1Alpha 126 "NO_SPACE" 127 "SNA";
VAL_ 606 PARK_pscLeftCrossObj2Y 2046 "NO_SPACE" 2047 "SNA";
VAL_ 606 PARK_pscLeftCrossObj2X 2046 "NO_SPACE" 2047 "SNA";
VAL_ 606 PARK_pscLeftCrossObj2Alpha 126 "NO_SPACE" 127 "SNA";
VAL_ 606 PARK_pscRightParallelObj1X 2046 "NO_SPACE" 2047 "SNA";
VAL_ 606 PARK_pscRightParallelObj1Y 2046 "NO_SPACE" 2047 "SNA";
VAL_ 606 PARK_pscRightParallelObj1Alpha 126 "NO_SPACE" 127 "SNA";
VAL_ 606 PARK_pscRightParallelObj2Y 2046 "NO_SPACE" 2047 "SNA";
VAL_ 606 PARK_pscRightParallelObj2X 2046 "NO_SPACE" 2047 "SNA";
VAL_ 606 PARK_pscRightParallelObj2Alpha 126 "NO_SPACE" 127 "SNA";
VAL_ 606 PARK_pscRightCrossObj1X 2046 "NO_SPACE" 2047 "SNA";
VAL_ 606 PARK_pscRightCrossObj1Y 2046 "NO_SPACE" 2047 "SNA";
VAL_ 606 PARK_pscRightCrossObj1Alpha 126 "NO_SPACE" 127 "SNA";
VAL_ 606 PARK_pscRightCrossObj2Y 2046 "NO_SPACE" 2047 "SNA";
VAL_ 606 PARK_pscRightCrossObj2X 2046 "NO_SPACE" 2047 "SNA";
VAL_ 606 PARK_pscRightCrossObj2Alpha 126 "NO_SPACE" 127 "SNA";

VAL_ 544 PARK_pscAngleActive 0 "INACTIVE" 1 "REQUEST_CONTROL";
VAL_ 544 PARK_pscCrossLeftParkable 0 "NONE" 1 "PARKING_SLOT_OK" 2 "PARKING_SLOT_OK_POSITION_OK" 3 "SNA";
VAL_ 544 PARK_pscCrossRightParkable 0 "NONE" 1 "PARKING_SLOT_OK" 2 "PARKING_SLOT_OK_POSITION_OK" 3 "SNA";
VAL_ 544 PARK_pscCrossSpace 0 "NONE_AVAILABLE" 1 "RIGHT_AVAILABLE" 2 "LEFT_AVAILABLE" 3 "BOTH_AVAILABLE";
VAL_ 544 PARK_pscManeuverDistance 2047 "SNA";
VAL_ 544 PARK_pscMaxVelocity 63 "SNA";
VAL_ 544 PARK_pscParallelLeftParkable 0 "NONE" 1 "PARKING_SLOT_OK" 2 "PARKING_SLOT_OK_POSITION_OK" 3 "SNA";
VAL_ 544 PARK_pscParallelRightParkable 0 "NONE" 1 "PARKING_SLOT_OK" 2 "PARKING_SLOT_OK_POSITION_OK" 3 "SNA";
VAL_ 544 PARK_pscParallelSpace 0 "NONE_AVAILABLE" 1 "RIGHT_AVAILABLE" 2 "LEFT_AVAILABLE" 3 "BOTH_AVAILABLE";
VAL_ 544 PARK_pscParkAbortReason 0 "NONE" 1 "VELOCITY_TOO_HIGH" 2 "MAX_NUM_OF_MOVES" 3 "NO_VALID_PATH" 4 "UNCONTROLLED_TRAVEL_DIST_REACHED" 5 "OFF_TRACK" 6 "MAX_SWA_DEV_EXCEEDED" 7 "MAX_YAW_ANGLE_REACHED" 8 "OBSTACLE_ON_PATH" 9 "PARK_SPACE_TOO_SMALL" 10 "FULL_WARNING_ON_BOTH_SIDES" 11 "HANDS_ON_DETECTED" 12 "VEHICLE_DYNAMICS_INTERVENTION" 13 "EPAS_FAULT" 14 "DAS_ABORT" 15 "ECU_INTERNAL_FAULT" 16 "SYSTEM_FAULT" 17 "SYSTEM_SERVICE" 18 "ERROR" 31 "SNA";
VAL_ 544 PARK_pscParkInstruction 0 "NO_MESSAGE" 1 "STOP" 2 "DRIVE_FORWARD" 3 "DRIVE_BACKWARD" 4 "ABORTED" 5 "EXPLORATION" 7 "SNA";
VAL_ 544 PARK_pscParkStatus 0 "NOT_AVAILABLE" 1 "SEARCHING" 2 "GUIDANCE_LEFT" 3 "GUIDANCE_RIGHT" 4 "PRE_GUIDANCE" 5 "GUIDANCE_FINISHED" 6 "FAULT" 7 "SNA";

VAL_ 590 PARK_pscVehSlotType 0 "LEFT_PARALLEL" 1 "LEFT_CROSS" 2 "RIGHT_PARALLEL" 3 "RIGHT_CROSS";
VAL_ 590 PARK_pscLeftParallelVehX 2046 "NO_SPACE" 2047 "SNA";
VAL_ 590 PARK_pscLeftParallelVehY 2046 "NO_SPACE" 2047 "SNA";
VAL_ 590 PARK_pscLeftParallelPsi 8190 "NO_SPACE" 8191 "SNA";
VAL_ 590 PARK_pscLeftParallelSizeX 254 "NO_SPACE" 255 "SNA";
VAL_ 590 PARK_pscLeftParallelSizeY 254 "NO_SPACE" 255 "SNA";
VAL_ 590 PARK_pscLeftCrossVehX 2046 "NO_SPACE" 2047 "SNA";
VAL_ 590 PARK_pscLeftCrossVehY 2046 "NO_SPACE" 2047 "SNA";
VAL_ 590 PARK_pscLeftCrossPsi 8190 "NO_SPACE" 8191 "SNA";
VAL_ 590 PARK_pscLeftCrossSizeX 254 "NO_SPACE" 255 "SNA";
VAL_ 590 PARK_pscLeftCrossSizeY 254 "NO_SPACE" 255 "SNA";
VAL_ 590 PARK_pscRightParallelVehX 2046 "NO_SPACE" 2047 "SNA";
VAL_ 590 PARK_pscRightParallelVehY 2046 "NO_SPACE" 2047 "SNA";
VAL_ 590 PARK_pscRightParallelPsi 8190 "NO_SPACE" 8191 "SNA";
VAL_ 590 PARK_pscRightParallelSizeX 254 "NO_SPACE" 255 "SNA";
VAL_ 590 PARK_pscRightParallelSizeY 254 "NO_SPACE" 255 "SNA";
VAL_ 590 PARK_pscRightCrossVehX 2046 "NO_SPACE" 2047 "SNA";
VAL_ 590 PARK_pscRightCrossVehY 2046 "NO_SPACE" 2047 "SNA";
VAL_ 590 PARK_pscRightCrossPsi 8190 "NO_SPACE" 8191 "SNA";
VAL_ 590 PARK_pscRightCrossSizeX 254 "NO_SPACE" 255 "SNA";
VAL_ 590 PARK_pscRightCrossSizeY 254 "NO_SPACE" 255 "SNA";

VAL_ 529 PARK_sdiSensor1RawDistData 0 "BLOCKED" 1 "NEAR_DETECTION" 500 "NO_OBJECT_DETECTED" 511 "SNA";
VAL_ 529 PARK_sdiSensor2RawDistData 0 "BLOCKED" 1 "NEAR_DETECTION" 500 "NO_OBJECT_DETECTED" 511 "SNA";
VAL_ 529 PARK_sdiSensor3RawDistData 0 "BLOCKED" 1 "NEAR_DETECTION" 500 "NO_OBJECT_DETECTED" 511 "SNA";
VAL_ 529 PARK_sdiSensor4RawDistData 0 "BLOCKED" 1 "NEAR_DETECTION" 500 "NO_OBJECT_DETECTED" 511 "SNA";
VAL_ 529 PARK_sdiSensor5RawDistData 0 "BLOCKED" 1 "NEAR_DETECTION" 500 "NO_OBJECT_DETECTED" 511 "SNA";
VAL_ 529 PARK_sdiSensor6RawDistData 0 "BLOCKED" 1 "NEAR_DETECTION" 500 "NO_OBJECT_DETECTED" 511 "SNA";

VAL_ 559 PARK_sdiSensor10RawDistData 0 "BLOCKED" 1 "NEAR_DETECTION" 500 "NO_OBJECT_DETECTED" 511 "SNA";
VAL_ 559 PARK_sdiSensor11RawDistData 0 "BLOCKED" 1 "NEAR_DETECTION" 500 "NO_OBJECT_DETECTED" 511 "SNA";
VAL_ 559 PARK_sdiSensor12RawDistData 0 "BLOCKED" 1 "NEAR_DETECTION" 500 "NO_OBJECT_DETECTED" 511 "SNA";
VAL_ 559 PARK_sdiSensor7RawDistData 0 "BLOCKED" 1 "NEAR_DETECTION" 500 "NO_OBJECT_DETECTED" 511 "SNA";
VAL_ 559 PARK_sdiSensor8RawDistData 0 "BLOCKED" 1 "NEAR_DETECTION" 500 "NO_OBJECT_DETECTED" 511 "SNA";
VAL_ 559 PARK_sdiSensor9RawDistData 0 "BLOCKED" 1 "NEAR_DETECTION" 500 "NO_OBJECT_DETECTED" 511 "SNA";

VAL_ 814 PARK_frontDtcPresent 0 "FALSE" 1 "TRUE" 2 "UNUSED" 3 "SNA";
VAL_ 814 PARK_frontLeftMiddleSensorState 0 "NO_FAILURE" 1 "PERMANENT_FAILURE" 2 "TEMPORARY_FAILURE" 3 "SNA";
VAL_ 814 PARK_frontLeftRawDistData 255 "SNA";
VAL_ 814 PARK_frontLeftSensorState 0 "NO_FAILURE" 1 "PERMANENT_FAILURE" 2 "TEMPORARY_FAILURE" 3 "SNA";
VAL_ 814 PARK_frontRightMiddleSensorState 0 "NO_FAILURE" 1 "PERMANENT_FAILURE" 2 "TEMPORARY_FAILURE" 3 "SNA";
VAL_ 814 PARK_frontRightRawDistData 255 "SNA";
VAL_ 814 PARK_frontRightSensorState 0 "NO_FAILURE" 1 "PERMANENT_FAILURE" 2 "TEMPORARY_FAILURE" 3 "SNA";
VAL_ 814 PARK_systemStatusFront 0 "DISABLED" 1 "ENABLED" 2 "UNUSED" 3 "SNA";

VAL_ 830 PARK_rearDtcPresent 0 "FALSE" 1 "TRUE" 2 "UNUSED" 3 "SNA";
VAL_ 830 PARK_rearLeftMiddleSensorState 0 "NO_FAILURE" 1 "PERMANENT_FAILURE" 2 "TEMPORARY_FAILURE" 3 "SNA";
VAL_ 830 PARK_rearLeftRawDistData 255 "SNA";
VAL_ 830 PARK_rearLeftSensorState 0 "NO_FAILURE" 1 "PERMANENT_FAILURE" 2 "TEMPORARY_FAILURE" 3 "SNA";
VAL_ 830 PARK_rearRightMiddleSensorState 0 "NO_FAILURE" 1 "PERMANENT_FAILURE" 2 "TEMPORARY_FAILURE" 3 "SNA";
VAL_ 830 PARK_rearRightRawDistData 255 "SNA";
VAL_ 830 PARK_rearRightSensorState 0 "NO_FAILURE" 1 "PERMANENT_FAILURE" 2 "TEMPORARY_FAILURE" 3 "SNA";
VAL_ 830 PARK_systemStatusRear 0 "DISABLED" 1 "ENABLED" 2 "UNUSED" 3 "SNA";

VAL_ 798 PARK_majorVersion 255 "SNA";
VAL_ 798 PARK_minorVersion 255 "SNA";
VAL_ 798 PARK_serviceRequest 0 "NO_FAILURE" 1 "FAILURE" 2 "UNUSED" 3 "SNA";
VAL_ 798 PARK_status 0 "DISABLED" 1 "ENABLED" 2 "TEMPORARY_FAILURE" 3 "SNA";
VAL_ 798 PARK_subMinorVersion 255 "SNA";
VAL_ 798 PARK_systemDtcPresent 0 "FALSE" 1 "TRUE" 2 "UNUSED" 3 "SNA";

VAL_ 782 PARK_autoCalComplete 0 "INCOMPLETE" 1 "COMPLETE";
VAL_ 782 PARK_geometryType 0 "MODELS" 1 "MODELS_2" 2 "MODELX";
VAL_ 782 PARK_pscLeftCurbType 0 "VIRTUAL_CURB" 1 "LOW_CURB" 2 "HIGH_CURB";
VAL_ 782 PARK_pscRightCurbType 0 "VIRTUAL_CURB" 1 "LOW_CURB" 2 "HIGH_CURB";
VAL_ 782 PARK_rackDetected 0 "UNKNOWN" 1 "NO_RACK" 2 "RACK_DETECTED" 3 "SNA";
VAL_ 782 PARK_sdiActive 0 "DISABLED" 1 "ENABLED";
VAL_ 782 PARK_sdiBlindSpotLeft 0 "NO_WARNING" 1 "WARNING" 2 "UNUSED" 3 "SNA";
VAL_ 782 PARK_sdiBlindSpotRight 0 "NO_WARNING" 1 "WARNING" 2 "UNUSED" 3 "SNA";
VAL_ 782 PARK_sdiNoise 0 "NOMINAL" 1 "HIGH" 2 "RAIN" 3 "SNA";
VAL_ 782 PARK_tireFitment 0 "SQUARE" 1 "STAGGERED" 3 "SNA";

VAL_ 99 PDM_passRepeaterState 0 "Off" 1 "On" 2 "Failed" 3 "default";

VAL_ 553 PF_componentHardwareId 0 "DH1" 1 "DH2" 2 "DH3" 255 "SNA";
VAL_ 553 PF_mainState 0 "HND_STATE_INIT" 1 "HND_STATE_UNKNOWN" 2 "HND_STATE_RETRACTED" 3 "HND_STATE_MOVING_OUT" 4 "HND_STATE_UNUSED_4" 5 "HND_STATE_PRESENTED" 6 "HND_STATE_UNUSED_6" 7 "HND_STATE_MOVING_IN" 8 "HND_STATE_PUSHED" 9 "HND_STATE_PULLED" 10 "HND_STATE_FAULT" 11 "HND_STATE_STOPPED" 12 "HND_STATE_PRESENT_FAIL" 13 "HND_STATE_RETRACT_FAIL" 14 "HND_STATE_GOTOSLEEP" 15 "HND_STATE_SAVECONFIG" 16 "HND_STATE_MFG" 17 "INIT" 18 "RUN" 19 "SLEEP" 20 "RESET" 21 "MFG" 22 "FAULT" 23 "INVALID";
VAL_ 553 PF_motorState 0 "HND_MOTOR_IDLE" 1 "HND_MOTOR_FWD" 2 "HND_MOTOR_REVERSE" 3 "HND_MOTOR_ENDSTOP" 4 "HND_MOTOR_OVERCURRENT" 5 "HND_MOTOR_TIMEOUT" 6 "HND_MOTOR_ERROR" 17 "UNKNOWN" 18 "RETRACTED" 19 "PUSHED" 20 "PRESENTING" 21 "PRESENTED" 22 "PULLING" 23 "PULLED" 24 "CLAMPING" 25 "CLAMPED" 26 "RECLAMPING" 27 "WAIT" 28 "UNCLAMPING" 29 "REPRESENTING" 30 "RETRACTING" 31 "PREUNKNOWN" 32 "WAIT_CLAMP_RELEASE" 33 "WAIT_PUSHED_RELEASE" 34 "REPRESENTING_SOFT_CURRENT" 35 "MEASURE_ARM" 36 "MEASURE" 45 "DH3_INVALIDSUB" 46 "DH3_UNKNOWN" 47 "DH3_FINDHOME" 48 "DH3_RETRACTING" 49 "DH3_PINCHDETECT" 50 "DH3_RETRACTED" 51 "DH3_PUSHED" 52 "DH3_PRESENTING" 53 "DH3_OBSTRUCTION" 54 "DH3_PRESENTED" 55 "DH3_PULLING" 56 "DH3_PULLED" 57 "DH3_CLAMPING" 58 "DH3_CLAMPED" 59 "DH3_WAIT" 60 "DH3_UNCLAMPING" 61 "DH3_RETRACTFAIL" 62 "DH3_PRESENTFAIL" 63 "DH3_OVERDRIVE" 64 "DH3_CALRETRACT" 65 "DH3_CALPRESENT" 66 "DH3_UNCALIBRATED" 67 "DH3_RETRACTINGMORE" 68 "DH3_PUSHEDTORELEASE" 69 "DH3_UNCALIBRATED_PUSH";
VAL_ 553 PF_targetPosition 0 "UNKNOWN" 1 "RETRACTED" 2 "PRESENTED" 3 "RETRACT_FAILED" 4 "PRESENT_FAILED" 5 "MOVING_IN" 6 "MOVING_OUT" 7 "FAILURE";

VAL_ 569 PR_componentHardwareId 0 "DH1" 1 "DH2" 2 "DH3" 255 "SNA";
VAL_ 569 PR_mainState 0 "HND_STATE_INIT" 1 "HND_STATE_UNKNOWN" 2 "HND_STATE_RETRACTED" 3 "HND_STATE_MOVING_OUT" 4 "HND_STATE_UNUSED_4" 5 "HND_STATE_PRESENTED" 6 "HND_STATE_UNUSED_6" 7 "HND_STATE_MOVING_IN" 8 "HND_STATE_PUSHED" 9 "HND_STATE_PULLED" 10 "HND_STATE_FAULT" 11 "HND_STATE_STOPPED" 12 "HND_STATE_PRESENT_FAIL" 13 "HND_STATE_RETRACT_FAIL" 14 "HND_STATE_GOTOSLEEP" 15 "HND_STATE_SAVECONFIG" 16 "HND_STATE_MFG" 17 "INIT" 18 "RUN" 19 "SLEEP" 20 "RESET" 21 "MFG" 22 "FAULT" 23 "INVALID";
VAL_ 569 PR_motorState 0 "HND_MOTOR_IDLE" 1 "HND_MOTOR_FWD" 2 "HND_MOTOR_REVERSE" 3 "HND_MOTOR_ENDSTOP" 4 "HND_MOTOR_OVERCURRENT" 5 "HND_MOTOR_TIMEOUT" 6 "HND_MOTOR_ERROR" 17 "UNKNOWN" 18 "RETRACTED" 19 "PUSHED" 20 "PRESENTING" 21 "PRESENTED" 22 "PULLING" 23 "PULLED" 24 "CLAMPING" 25 "CLAMPED" 26 "RECLAMPING" 27 "WAIT" 28 "UNCLAMPING" 29 "REPRESENTING" 30 "RETRACTING" 31 "PREUNKNOWN" 32 "WAIT_CLAMP_RELEASE" 33 "WAIT_PUSHED_RELEASE" 34 "REPRESENTING_SOFT_CURRENT" 35 "MEASURE_ARM" 36 "MEASURE" 45 "DH3_INVALIDSUB" 46 "DH3_UNKNOWN" 47 "DH3_FINDHOME" 48 "DH3_RETRACTING" 49 "DH3_PINCHDETECT" 50 "DH3_RETRACTED" 51 "DH3_PUSHED" 52 "DH3_PRESENTING" 53 "DH3_OBSTRUCTION" 54 "DH3_PRESENTED" 55 "DH3_PULLING" 56 "DH3_PULLED" 57 "DH3_CLAMPING" 58 "DH3_CLAMPED" 59 "DH3_WAIT" 60 "DH3_UNCLAMPING" 61 "DH3_RETRACTFAIL" 62 "DH3_PRESENTFAIL" 63 "DH3_OVERDRIVE" 64 "DH3_CALRETRACT" 65 "DH3_CALPRESENT" 66 "DH3_UNCALIBRATED" 67 "DH3_RETRACTINGMORE" 68 "DH3_PUSHEDTORELEASE" 69 "DH3_UNCALIBRATED_PUSH";
VAL_ 569 PR_targetPosition 0 "UNKNOWN" 1 "RETRACTED" 2 "PRESENTED" 3 "RETRACT_FAILED" 4 "PRESENT_FAILED" 5 "MOVING_IN" 6 "MOVING_OUT" 7 "FAILURE";

VAL_ 1305 PDM_componentBranchOrigin 254 "LOCAL_BUILD" 255 "SNA";
VAL_ 1305 PDM_componentHardwareRevision 254 "LOCAL_BUILD" 255 "SNA";
VAL_ 1305 PDM_componentMajorVersion 254 "LOCAL_BUILD" 255 "SNA";
VAL_ 1305 PDM_componentMaturity 254 "LOCAL_BUILD" 255 "SNA";
VAL_ 1305 PDM_componentSvn 16777215 "SNA";
VAL_ 1305 PDM_platformType 254 "LOCAL_BUILD" 255 "SNA";

VAL_ 1748 PMS_infoIndex 0 "DEPRECATED_0" 1 "DEPRECATED_1" 2 "DEPRECATED_2" 3 "DEPRECATED_3" 4 "DEPRECATED_4" 5 "DEPRECATED_5" 6 "DEPRECATED_6" 7 "DEPRECATED_7" 8 "DEPRECATED_8" 9 "DEPRECATED_9" 10 "BUILD_HWID_COMPONENTID" 11 "PCBAID_ASSYID_USAGEID" 13 "APP_CRC" 14 "BOOTLOADER_SVN" 15 "BOOTLOADER_CRC" 16 "SUBCOMPONENT" 17 "APP_GITHASH" 18 "BOOTLOADER_GITHASH" 19 "VERSION_DEPRECATED" 20 "UDS_PROTOCOL_BOOTCRC" 21 "DI_BUILD_DATA" 255 "END";
VAL_ 1748 PMS_buildType 0 "UNKNOWN_BUILD" 1 "PLATFORM_BUILD" 2 "LOCAL_BUILD" 3 "TRACEABLE_CI_BUILD" 4 "MFG_BUILD";
VAL_ 1748 PMS_hardwareId 252 "CONFIGURABLE_HWID_PLACEHOLDER";
VAL_ 1748 PMS_diNodeBuildType 0 "UNKNOWN_BUILD" 1 "PLATFORM_BUILD" 2 "LOCAL_BUILD" 3 "TRACEABLE_CI_BUILD" 4 "MFG_BUILD";

VAL_ 821 PM_d001_unused 0 "NOT_TESTED_DTC" 1 "PASSED_DTC" 2 "FAILED_DTC" 3 "UNABLE_TO_TEST_DTC";
VAL_ 821 PM_d002_unused 0 "NOT_TESTED_DTC" 1 "PASSED_DTC" 2 "FAILED_DTC" 3 "UNABLE_TO_TEST_DTC";
VAL_ 821 PM_d003_unused 0 "NOT_TESTED_DTC" 1 "PASSED_DTC" 2 "FAILED_DTC" 3 "UNABLE_TO_TEST_DTC";
VAL_ 821 PM_d004_unused 0 "NOT_TESTED_DTC" 1 "PASSED_DTC" 2 "FAILED_DTC" 3 "UNABLE_TO_TEST_DTC";
VAL_ 821 PM_d005_unused 0 "NOT_TESTED_DTC" 1 "PASSED_DTC" 2 "FAILED_DTC" 3 "UNABLE_TO_TEST_DTC";
VAL_ 821 PM_d006_unused 0 "NOT_TESTED_DTC" 1 "PASSED_DTC" 2 "FAILED_DTC" 3 "UNABLE_TO_TEST_DTC";
VAL_ 821 PM_d007_unused 0 "NOT_TESTED_DTC" 1 "PASSED_DTC" 2 "FAILED_DTC" 3 "UNABLE_TO_TEST_DTC";
VAL_ 821 PM_d008_unused 0 "NOT_TESTED_DTC" 1 "PASSED_DTC" 2 "FAILED_DTC" 3 "UNABLE_TO_TEST_DTC";
VAL_ 821 PM_d009_unused 0 "NOT_TESTED_DTC" 1 "PASSED_DTC" 2 "FAILED_DTC" 3 "UNABLE_TO_TEST_DTC";
VAL_ 821 PM_d010_unused 0 "NOT_TESTED_DTC" 1 "PASSED_DTC" 2 "FAILED_DTC" 3 "UNABLE_TO_TEST_DTC";
VAL_ 821 PM_d011_unused 0 "NOT_TESTED_DTC" 1 "PASSED_DTC" 2 "FAILED_DTC" 3 "UNABLE_TO_TEST_DTC";
VAL_ 821 PM_d012_unused 0 "NOT_TESTED_DTC" 1 "PASSED_DTC" 2 "FAILED_DTC" 3 "UNABLE_TO_TEST_DTC";
VAL_ 821 PM_d013_unused 0 "NOT_TESTED_DTC" 1 "PASSED_DTC" 2 "FAILED_DTC" 3 "UNABLE_TO_TEST_DTC";
VAL_ 821 PM_d014_unused 0 "NOT_TESTED_DTC" 1 "PASSED_DTC" 2 "FAILED_DTC" 3 "UNABLE_TO_TEST_DTC";
VAL_ 821 PM_d015_unused 0 "NOT_TESTED_DTC" 1 "PASSED_DTC" 2 "FAILED_DTC" 3 "UNABLE_TO_TEST_DTC";
VAL_ 821 PM_d016_unused 0 "NOT_TESTED_DTC" 1 "PASSED_DTC" 2 "FAILED_DTC" 3 "UNABLE_TO_TEST_DTC";
VAL_ 821 PM_d017_unused 0 "NOT_TESTED_DTC" 1 "PASSED_DTC" 2 "FAILED_DTC" 3 "UNABLE_TO_TEST_DTC";
VAL_ 821 PM_d018_unused 0 "NOT_TESTED_DTC" 1 "PASSED_DTC" 2 "FAILED_DTC" 3 "UNABLE_TO_TEST_DTC";
VAL_ 821 PM_d019_unused 0 "NOT_TESTED_DTC" 1 "PASSED_DTC" 2 "FAILED_DTC" 3 "UNABLE_TO_TEST_DTC";
VAL_ 821 PM_d020_unused 0 "NOT_TESTED_DTC" 1 "PASSED_DTC" 2 "FAILED_DTC" 3 "UNABLE_TO_TEST_DTC";
VAL_ 821 PM_d021_unused 0 "NOT_TESTED_DTC" 1 "PASSED_DTC" 2 "FAILED_DTC" 3 "UNABLE_TO_TEST_DTC";
VAL_ 821 PM_d022_unused 0 "NOT_TESTED_DTC" 1 "PASSED_DTC" 2 "FAILED_DTC" 3 "UNABLE_TO_TEST_DTC";
VAL_ 821 PM_d023_unused 0 "NOT_TESTED_DTC" 1 "PASSED_DTC" 2 "FAILED_DTC" 3 "UNABLE_TO_TEST_DTC";
VAL_ 821 PM_d024_unused 0 "NOT_TESTED_DTC" 1 "PASSED_DTC" 2 "FAILED_DTC" 3 "UNABLE_TO_TEST_DTC";
VAL_ 821 PM_d025_unused 0 "NOT_TESTED_DTC" 1 "PASSED_DTC" 2 "FAILED_DTC" 3 "UNABLE_TO_TEST_DTC";
VAL_ 821 PM_d026_unused 0 "NOT_TESTED_DTC" 1 "PASSED_DTC" 2 "FAILED_DTC" 3 "UNABLE_TO_TEST_DTC";
VAL_ 821 PM_d027_unused 0 "NOT_TESTED_DTC" 1 "PASSED_DTC" 2 "FAILED_DTC" 3 "UNABLE_TO_TEST_DTC";
VAL_ 821 PM_d028_unused 0 "NOT_TESTED_DTC" 1 "PASSED_DTC" 2 "FAILED_DTC" 3 "UNABLE_TO_TEST_DTC";

VAL_ 1629 PM_infoIndex 0 "DEPRECATED_0" 1 "DEPRECATED_1" 2 "DEPRECATED_2" 3 "DEPRECATED_3" 4 "DEPRECATED_4" 5 "DEPRECATED_5" 6 "DEPRECATED_6" 7 "DEPRECATED_7" 8 "DEPRECATED_8" 9 "DEPRECATED_9" 10 "BUILD_HWID_COMPONENTID" 11 "PCBAID_ASSYID_USAGEID" 13 "APP_CRC" 14 "BOOTLOADER_SVN" 15 "BOOTLOADER_CRC" 16 "SUBCOMPONENT" 17 "APP_GITHASH" 18 "BOOTLOADER_GITHASH" 19 "VERSION_DEPRECATED" 20 "UDS_PROTOCOL_BOOTCRC" 21 "DI_BUILD_DATA" 255 "END";
VAL_ 1629 PM_buildType 0 "UNKNOWN_BUILD" 1 "PLATFORM_BUILD" 2 "LOCAL_BUILD" 3 "TRACEABLE_CI_BUILD" 4 "MFG_BUILD";
VAL_ 1629 PM_hardwareId 252 "CONFIGURABLE_HWID_PLACEHOLDER";
VAL_ 1629 PM_diNodeBuildType 0 "UNKNOWN_BUILD" 1 "PLATFORM_BUILD" 2 "LOCAL_BUILD" 3 "TRACEABLE_CI_BUILD" 4 "MFG_BUILD";

VAL_ 1661 PM_componentBranchOrigin 254 "LOCAL_BUILD" 255 "SNA";
VAL_ 1661 PM_componentHardwareId 252 "CONFIGURABLE_HWID_PLACEHOLDER" 254 "LOCAL_BUILD" 255 "SNA";
VAL_ 1661 PM_componentMajorVersion 254 "LOCAL_BUILD" 255 "SNA";
VAL_ 1661 PM_componentMaturity 254 "LOCAL_BUILD" 255 "SNA";
VAL_ 1661 PM_platformBranchOrigin 254 "LOCAL_BUILD" 255 "SNA";
VAL_ 1661 PM_platformMajorVersion 254 "LOCAL_BUILD" 255 "SNA";
VAL_ 1661 PM_platformMaturity 254 "LOCAL_BUILD" 255 "SNA";
VAL_ 1661 PM_platformType 254 "LOCAL_BUILD" 255 "SNA";

VAL_ 1578 PTC_LimitedOperationCause_Flag 0 "NORMAL" 1 "PTC_FaultLVLow_Flag" 2 "PTC_FaultLVHigh_Flag" 3 "PTC_FaultHVLow_Flag" 4 "PTC_FaultHVHigh_Flag" 5 "PTC_FaultPtc1OverCurrent_Flag" 6 "PTC_FaultPtc2OverCurrent_Flag" 7 "PTC_FaultPtc3OverCurrent_Flag" 8 "PTC_FaultThermalShut_Flag" 9 "PTC_FaultPCBThermalShut_Flag";
VAL_ 1578 PTC_SoftwareRegion_Num 0 "MIN_TEMPTABLE" 10 "LHD_TEMPTABLE" 11 "RHD_TEMPTABLE";

VAL_ 837 PTC_infoIndex 0 "DEPRECATED_0" 1 "DEPRECATED_1" 2 "DEPRECATED_2" 3 "DEPRECATED_3" 4 "DEPRECATED_4" 5 "DEPRECATED_5" 6 "DEPRECATED_6" 7 "DEPRECATED_7" 8 "DEPRECATED_8" 9 "DEPRECATED_9" 10 "BUILD_HWID_COMPONENTID" 11 "PCBAID_ASSYID_USAGEID" 13 "APP_CRC" 14 "BOOTLOADER_SVN" 15 "BOOTLOADER_CRC" 16 "SUBCOMPONENT" 17 "APP_GITHASH" 18 "BOOTLOADER_GITHASH" 19 "VERSION_DEPRECATED" 20 "UDS_PROTOCOL_BOOTCRC" 255 "END";

VAL_ 1329 RADC_infoIndex 0 "DEPRECATED_0" 1 "DEPRECATED_1" 2 "DEPRECATED_2" 3 "DEPRECATED_3" 4 "DEPRECATED_4" 5 "DEPRECATED_5" 6 "DEPRECATED_6" 7 "DEPRECATED_7" 8 "DEPRECATED_8" 9 "DEPRECATED_9" 10 "BUILD_HWID_COMPONENTID" 11 "PCBAID_ASSYID_USAGEID" 13 "APP_CRC" 14 "BOOTLOADER_SVN" 15 "BOOTLOADER_CRC" 16 "SUBCOMPONENT" 17 "APP_GITHASH" 18 "BOOTLOADER_GITHASH" 19 "VERSION_DEPRECATED" 20 "UDS_PROTOCOL_BOOTCRC" 255 "END";

VAL_ 1543 RCCM_SoftwareRegion_Num 0 "GENERAL PART (COMMON)" 1 "North America" 2 "South America" 3 "Australia" 4 "Europe" 5 "Asia" 6 "China" 7 "India" 8 "Africa";

VAL_ 1009 RCM2_a000_crashDetected 0 "CLEARED" 1 "SET";
VAL_ 1009 RCM2_a001_nearDeploy 0 "CLEARED" 1 "SET";
VAL_ 1009 RCM2_a002_airbagsUnArmed 0 "CLEARED" 1 "SET";
VAL_ 1009 RCM2_a003_warningIndicator 0 "CLEARED" 1 "SET";
VAL_ 1009 RCM2_a004_crashAlgoWakeup 0 "CLEARED" 1 "SET";
VAL_ 1009 RCM2_a005_abuseImmunityThrshold 0 "CLEARED" 1 "SET";
VAL_ 1009 RCM2_a006_supplierDiagEnabled 0 "CLEARED" 1 "SET";
VAL_ 1009 RCM2_a007_pedProCrashDetected 0 "CLEARED" 1 "SET";
VAL_ 1009 RCM2_a008_factoryMode 0 "CLEARED" 1 "SET";
VAL_ 1009 RCM2_a009_edrDataAreaLocked 0 "CLEARED" 1 "SET";
VAL_ 1009 RCM2_a010_pedProEDRDataLocked 0 "CLEARED" 1 "SET";
VAL_ 1009 RCM2_a011_FrntAlgoDisabled 0 "CLEARED" 1 "SET";
VAL_ 1009 RCM2_a012_FrntAlgoDisabled 0 "CLEARED" 1 "SET";
VAL_ 1009 RCM2_a013_FrntAlgoDisabled 0 "CLEARED" 1 "SET";
VAL_ 1009 RCM2_a014_pedProNearDeploy 0 "CLEARED" 1 "SET";
VAL_ 1009 RCM2_a047_batteryESRhigh 0 "CLEARED" 1 "SET";
VAL_ 1009 RCM2_a048_batteryVoltageTooHigh 0 "CLEARED" 1 "SET";
VAL_ 1009 RCM2_a049_batteryVoltageTooLow 0 "CLEARED" 1 "SET";
VAL_ 1009 RCM2_a050_driverABStg1Sht2Gnd 0 "CLEARED" 1 "SET";
VAL_ 1009 RCM2_a051_driverABStg1Sht2Bat 0 "CLEARED" 1 "SET";
VAL_ 1009 RCM2_a052_driverABStg1Open 0 "CLEARED" 1 "SET";
VAL_ 1009 RCM2_a053_driverABStg1Short 0 "CLEARED" 1 "SET";
VAL_ 1009 RCM2_a054_driverABStg1CrssCoup 0 "CLEARED" 1 "SET";
VAL_ 1009 RCM2_a055_driverABStg1Config 0 "CLEARED" 1 "SET";
VAL_ 1009 RCM2_a056_driverABStg2Sht2Gnd 0 "CLEARED" 1 "SET";
VAL_ 1009 RCM2_a057_driverABStg2Sht2Bat 0 "CLEARED" 1 "SET";
VAL_ 1009 RCM2_a058_driverABStg2Open 0 "CLEARED" 1 "SET";
VAL_ 1009 RCM2_a059_driverABStg2Short 0 "CLEARED" 1 "SET";
VAL_ 1009 RCM2_a060_driverABStg2CrssCoup 0 "CLEARED" 1 "SET";
VAL_ 1009 RCM2_a061_driverABStg2Config 0 "CLEARED" 1 "SET";
VAL_ 1009 RCM2_a062_passABStg1Sht2Gnd 0 "CLEARED" 1 "SET";
VAL_ 1009 RCM2_a063_passABStg1Sht2Bat 0 "CLEARED" 1 "SET";
VAL_ 1009 RCM2_a064_passABStg1Open 0 "CLEARED" 1 "SET";
VAL_ 1009 RCM2_a065_passABStg1Short 0 "CLEARED" 1 "SET";
VAL_ 1009 RCM2_a066_passABStg1CrssCoup 0 "CLEARED" 1 "SET";
VAL_ 1009 RCM2_a067_passABStg1Config 0 "CLEARED" 1 "SET";
VAL_ 1009 RCM2_a068_passABStg2Sht2Gnd 0 "CLEARED" 1 "SET";
VAL_ 1009 RCM2_a069_passABStg2Sht2Bat 0 "CLEARED" 1 "SET";
VAL_ 1009 RCM2_a070_passABStg2Open 0 "CLEARED" 1 "SET";
VAL_ 1009 RCM2_a071_passABStg2Short 0 "CLEARED" 1 "SET";
VAL_ 1009 RCM2_a072_passABStg2CrssCoup 0 "CLEARED" 1 "SET";
VAL_ 1009 RCM2_a073_passABStg2Config 0 "CLEARED" 1 "SET";
VAL_ 1009 RCM2_a074_passActiveVentSht2Gnd 0 "CLEARED" 1 "SET";
VAL_ 1009 RCM2_a075_passActiveVentSht2Bat 0 "CLEARED" 1 "SET";
VAL_ 1009 RCM2_a076_passActiveVentOpen 0 "CLEARED" 1 "SET";
VAL_ 1009 RCM2_a077_passActiveVentShort 0 "CLEARED" 1 "SET";
VAL_ 1009 RCM2_a078_passActiveVentCrssCoup 0 "CLEARED" 1 "SET";
VAL_ 1009 RCM2_a079_passActiveVentConfig 0 "CLEARED" 1 "SET";
VAL_ 1009 RCM2_a080_pretenShldLeftSht2Gnd 0 "CLEARED" 1 "SET";
VAL_ 1009 RCM2_a081_pretenShldLeftSht2Bat 0 "CLEARED" 1 "SET";
VAL_ 1009 RCM2_a082_pretenShldLeftOpen 0 "CLEARED" 1 "SET";
VAL_ 1009 RCM2_a083_pretenShldLeftShort 0 "CLEARED" 1 "SET";
VAL_ 1009 RCM2_a084_pretenShldLeftCrossC 0 "CLEARED" 1 "SET";
VAL_ 1009 RCM2_a085_pretenShldLeftConfig 0 "CLEARED" 1 "SET";
VAL_ 1009 RCM2_a086_pretenShldRightSht2Gnd 0 "CLEARED" 1 "SET";
VAL_ 1009 RCM2_a087_pretenShldRightSht2Bat 0 "CLEARED" 1 "SET";
VAL_ 1009 RCM2_a088_pretenShldRightOpen 0 "CLEARED" 1 "SET";
VAL_ 1009 RCM2_a089_pretenShldRightShort 0 "CLEARED" 1 "SET";
VAL_ 1009 RCM2_a090_pretenShldRightCrssCou 0 "CLEARED" 1 "SET";
VAL_ 1009 RCM2_a091_pretenShldRightConfig 0 "CLEARED" 1 "SET";
VAL_ 1009 RCM2_a092_pretenLapLeftSht2Gnd 0 "CLEARED" 1 "SET";
VAL_ 1009 RCM2_a093_pretenLapLeftSht2Bat 0 "CLEARED" 1 "SET";
VAL_ 1009 RCM2_a094_pretenLapLeftOpen 0 "CLEARED" 1 "SET";
VAL_ 1009 RCM2_a095_pretenLapLeftShort 0 "CLEARED" 1 "SET";
VAL_ 1009 RCM2_a096_pretenLapLeftCrssCoup 0 "CLEARED" 1 "SET";
VAL_ 1009 RCM2_a097_pretenLapLeftConfig 0 "CLEARED" 1 "SET";
VAL_ 1009 RCM2_a098_pretenLapRightSht2Gnd 0 "CLEARED" 1 "SET";
VAL_ 1009 RCM2_a099_pretenLapRightSht2Bat 0 "CLEARED" 1 "SET";
VAL_ 1009 RCM2_a100_pretenLapRightOpen 0 "CLEARED" 1 "SET";
VAL_ 1009 RCM2_a101_pretenLapRightShort 0 "CLEARED" 1 "SET";
VAL_ 1009 RCM2_a102_pretenLapRightCrssCoup 0 "CLEARED" 1 "SET";
VAL_ 1009 RCM2_a103_pretenLapRightConfig 0 "CLEARED" 1 "SET";
VAL_ 1009 RCM2_a104_loadLimLeftSht2Gnd 0 "CLEARED" 1 "SET";
VAL_ 1009 RCM2_a105_loadLimLeftSht2Bat 0 "CLEARED" 1 "SET";
VAL_ 1009 RCM2_a106_loadLimLeftOpen 0 "CLEARED" 1 "SET";
VAL_ 1009 RCM2_a107_loadLimLeftShort 0 "CLEARED" 1 "SET";
VAL_ 1009 RCM2_a108_loadLimLeftCrssCoup 0 "CLEARED" 1 "SET";
VAL_ 1009 RCM2_a109_loadLimLeftConfig 0 "CLEARED" 1 "SET";
VAL_ 1009 RCM2_a110_loadLimRightSht2Gnd 0 "CLEARED" 1 "SET";
VAL_ 1009 RCM2_a111_loadLimRightSht2Bat 0 "CLEARED" 1 "SET";
VAL_ 1009 RCM2_a112_loadLimRightOpen 0 "CLEARED" 1 "SET";
VAL_ 1009 RCM2_a113_loadLimRightShort 0 "CLEARED" 1 "SET";
VAL_ 1009 RCM2_a114_loadLimRightCrssCoup 0 "CLEARED" 1 "SET";
VAL_ 1009 RCM2_a115_loadLimRightConfig 0 "CLEARED" 1 "SET";
VAL_ 1009 RCM2_a116_kneeABDrvrSht2Gnd 0 "CLEARED" 1 "SET";
VAL_ 1009 RCM2_a117_kneeABDrvrSht2Bat 0 "CLEARED" 1 "SET";
VAL_ 1009 RCM2_a118_kneeABDrvrOpen 0 "CLEARED" 1 "SET";
VAL_ 1009 RCM2_a119_kneeABDrvrShort 0 "CLEARED" 1 "SET";
VAL_ 1009 RCM2_a120_kneeABDrvrCrssCoup 0 "CLEARED" 1 "SET";
VAL_ 1009 RCM2_a121_kneeABDrvrConfig 0 "CLEARED" 1 "SET";
VAL_ 1009 RCM2_a122_kneeABPassSht2Gnd 0 "CLEARED" 1 "SET";
VAL_ 1009 RCM2_a123_kneeABPassSht2Bat 0 "CLEARED" 1 "SET";
VAL_ 1009 RCM2_a124_kneeABPassOpen 0 "CLEARED" 1 "SET";
VAL_ 1009 RCM2_a125_kneeABPassShort 0 "CLEARED" 1 "SET";
VAL_ 1009 RCM2_a126_kneeABPassCrssCoup 0 "CLEARED" 1 "SET";
VAL_ 1009 RCM2_a127_kneeABPassConfig 0 "CLEARED" 1 "SET";
VAL_ 1009 RCM2_a128_sideAB1stRowLSht2Gnd 0 "CLEARED" 1 "SET";
VAL_ 1009 RCM2_a129_sideAB1stRowLSht2Bat 0 "CLEARED" 1 "SET";
VAL_ 1009 RCM2_a130_sideAB1stRowLOpen 0 "CLEARED" 1 "SET";
VAL_ 1009 RCM2_a131_sideAB1stRowLShort 0 "CLEARED" 1 "SET";
VAL_ 1009 RCM2_a132_sideAB1stRowLCrssCoup 0 "CLEARED" 1 "SET";
VAL_ 1009 RCM2_a133_sideAB1stRowLConfig 0 "CLEARED" 1 "SET";
VAL_ 1009 RCM2_a134_sideAB1stRowRSht2Gnd 0 "CLEARED" 1 "SET";
VAL_ 1009 RCM2_a135_sideAB1stRowRSht2Bat 0 "CLEARED" 1 "SET";
VAL_ 1009 RCM2_a136_sideAB1stRowROpen 0 "CLEARED" 1 "SET";
VAL_ 1009 RCM2_a137_sideAB1stRowRShort 0 "CLEARED" 1 "SET";
VAL_ 1009 RCM2_a138_sideAB1stRowRCrssCoup 0 "CLEARED" 1 "SET";
VAL_ 1009 RCM2_a139_sideAB1stRowRConfig 0 "CLEARED" 1 "SET";
VAL_ 1009 RCM2_a140_driverABAVSht2Gnd 0 "CLEARED" 1 "SET";
VAL_ 1009 RCM2_a141_driverABAVSht2Bat 0 "CLEARED" 1 "SET";
VAL_ 1009 RCM2_a142_driverABAVOpen 0 "CLEARED" 1 "SET";
VAL_ 1009 RCM2_a143_driverABAVShort 0 "CLEARED" 1 "SET";
VAL_ 1009 RCM2_a144_driverABAVCrssCoup 0 "CLEARED" 1 "SET";
VAL_ 1009 RCM2_a145_driverABAVConfig 0 "CLEARED" 1 "SET";
VAL_ 1009 RCM2_a146_curABLeftSht2Gnd 0 "CLEARED" 1 "SET";
VAL_ 1009 RCM2_a147_curABLeftSht2Bat 0 "CLEARED" 1 "SET";
VAL_ 1009 RCM2_a148_curABLeftOpen 0 "CLEARED" 1 "SET";
VAL_ 1009 RCM2_a149_curABLeftShort 0 "CLEARED" 1 "SET";
VAL_ 1009 RCM2_a150_curABLeftCrssCoup 0 "CLEARED" 1 "SET";
VAL_ 1009 RCM2_a151_curABLeftConfig 0 "CLEARED" 1 "SET";
VAL_ 1009 RCM2_a152_curABRightSht2Gnd 0 "CLEARED" 1 "SET";
VAL_ 1009 RCM2_a153_curABRightSht2Bat 0 "CLEARED" 1 "SET";
VAL_ 1009 RCM2_a154_curABRightOpen 0 "CLEARED" 1 "SET";
VAL_ 1009 RCM2_a155_curABRightShort 0 "CLEARED" 1 "SET";
VAL_ 1009 RCM2_a156_curABRightCrssCoup 0 "CLEARED" 1 "SET";
VAL_ 1009 RCM2_a157_curABRightConfig 0 "CLEARED" 1 "SET";
VAL_ 1009 RCM2_a158_preten2ndRowLSht2Gnd 0 "CLEARED" 1 "SET";
VAL_ 1009 RCM2_a159_preten2ndRowLSht2Bat 0 "CLEARED" 1 "SET";
VAL_ 1009 RCM2_a160_preten2ndRowLOpen 0 "CLEARED" 1 "SET";
VAL_ 1009 RCM2_a161_preten2ndRowLShort 0 "CLEARED" 1 "SET";
VAL_ 1009 RCM2_a162_preten2ndRowLCrssCoup 0 "CLEARED" 1 "SET";
VAL_ 1009 RCM2_a163_preten2ndRowLCgf 0 "CLEARED" 1 "SET";
VAL_ 1009 RCM2_a164_preten2ndRowRSht2Gnd 0 "CLEARED" 1 "SET";
VAL_ 1009 RCM2_a165_preten2ndRowRSht2Bat 0 "CLEARED" 1 "SET";
VAL_ 1009 RCM2_a166_preten2ndRowROpen 0 "CLEARED" 1 "SET";
VAL_ 1009 RCM2_a167_preten2ndRowRShort 0 "CLEARED" 1 "SET";
VAL_ 1009 RCM2_a168_preten2ndRowRCrssCoup 0 "CLEARED" 1 "SET";
VAL_ 1009 RCM2_a169_preten2ndRowRCgf 0 "CLEARED" 1 "SET";
VAL_ 1009 RCM2_a170_curAB2ndRowLSht2Gnd 0 "CLEARED" 1 "SET";
VAL_ 1009 RCM2_a171_curAB2ndRowLSht2Bat 0 "CLEARED" 1 "SET";
VAL_ 1009 RCM2_a172_curAB2ndRowLOpen 0 "CLEARED" 1 "SET";
VAL_ 1009 RCM2_a173_curAB2ndRowLShort 0 "CLEARED" 1 "SET";
VAL_ 1009 RCM2_a174_curAB2ndRowLCrssCoup 0 "CLEARED" 1 "SET";
VAL_ 1009 RCM2_a175_curAB2ndRowLConfig 0 "CLEARED" 1 "SET";
VAL_ 1009 RCM2_a176_curAB2ndRowRSht2Gnd 0 "CLEARED" 1 "SET";
VAL_ 1009 RCM2_a177_curAB2ndRowRSht2Bat 0 "CLEARED" 1 "SET";
VAL_ 1009 RCM2_a178_curAB2ndRowROpen 0 "CLEARED" 1 "SET";
VAL_ 1009 RCM2_a179_curAB2ndRowRShort 0 "CLEARED" 1 "SET";
VAL_ 1009 RCM2_a180_curAB2ndRowRCrssCoup 0 "CLEARED" 1 "SET";
VAL_ 1009 RCM2_a181_curAB2ndRowRConfig 0 "CLEARED" 1 "SET";
VAL_ 1009 RCM2_a182_hoodActuatorRSht2Gnd 0 "CLEARED" 1 "SET";
VAL_ 1009 RCM2_a183_hoodActuatorRSht2Bat 0 "CLEARED" 1 "SET";
VAL_ 1009 RCM2_a184_hoodActuatorROpen 0 "CLEARED" 1 "SET";
VAL_ 1009 RCM2_a185_hoodActuatorRShort 0 "CLEARED" 1 "SET";
VAL_ 1009 RCM2_a186_hoodActuatorRCrssCoup 0 "CLEARED" 1 "SET";
VAL_ 1009 RCM2_a187_hoodActuatorRConfig 0 "CLEARED" 1 "SET";
VAL_ 1009 RCM2_a188_hoodActuatorLSht2Gnd 0 "CLEARED" 1 "SET";
VAL_ 1009 RCM2_a189_hoodActuatorLSht2Bat 0 "CLEARED" 1 "SET";
VAL_ 1009 RCM2_a190_hoodActuatorLOpen 0 "CLEARED" 1 "SET";
VAL_ 1009 RCM2_a191_hoodActuatorLShort 0 "CLEARED" 1 "SET";
VAL_ 1009 RCM2_a192_hoodActuatorLCrssCoup 0 "CLEARED" 1 "SET";
VAL_ 1009 RCM2_a193_hoodActuatorLConfig 0 "CLEARED" 1 "SET";
VAL_ 1009 RCM2_a250_ens1Sht2Bat 0 "CLEARED" 1 "SET";
VAL_ 1009 RCM2_a251_ens1Sht2Gnd 0 "CLEARED" 1 "SET";
VAL_ 1009 RCM2_a252_ens1Config 0 "CLEARED" 1 "SET";
VAL_ 1009 RCM2_a253_ens2Sht2Bat 0 "CLEARED" 1 "SET";
VAL_ 1009 RCM2_a254_ens2Sht2Gnd 0 "CLEARED" 1 "SET";
VAL_ 1009 RCM2_a255_ens2Config 0 "CLEARED" 1 "SET";
VAL_ 1009 RCM2_a300_imuAccXHgMonChlPerm 0 "CLEARED" 1 "SET";
VAL_ 1009 RCM2_a301_imuAccXHgMonChlTemp 0 "CLEARED" 1 "SET";
VAL_ 1009 RCM2_a302_imuAccYHgMonChlPerm 0 "CLEARED" 1 "SET";
VAL_ 1009 RCM2_a303_imuAccYHgMonChlTemp 0 "CLEARED" 1 "SET";
VAL_ 1009 RCM2_a304_imuYawR8SnsrPermBG 0 "CLEARED" 1 "SET";
VAL_ 1009 RCM2_a305_imuYawR8SnsrPermInit 0 "CLEARED" 1 "SET";
VAL_ 1009 RCM2_a306_imuYawR8SnsrPermLF 0 "CLEARED" 1 "SET";
VAL_ 1009 RCM2_a307_imuYawR8ChnlMonTmpLF 0 "CLEARED" 1 "SET";
VAL_ 1009 RCM2_a308_imuPitchR8SnsrPermBG 0 "CLEARED" 1 "SET";
VAL_ 1009 RCM2_a309_imuPitchR8SnsrPermInit 0 "CLEARED" 1 "SET";
VAL_ 1009 RCM2_a310_imuPitchR8SnsrPermLF 0 "CLEARED" 1 "SET";
VAL_ 1009 RCM2_a311_imuPitchR8ChnlMonTmpLF 0 "CLEARED" 1 "SET";
VAL_ 1009 RCM2_a312_imuRollR8SnsrPermBG 0 "CLEARED" 1 "SET";
VAL_ 1009 RCM2_a313_imuRollR8SnsrPermInit 0 "CLEARED" 1 "SET";
VAL_ 1009 RCM2_a314_imuRollR8SnsrPermLF 0 "CLEARED" 1 "SET";
VAL_ 1009 RCM2_a315_imuRollR8ChnlMonTmpLF 0 "CLEARED" 1 "SET";
VAL_ 1009 RCM2_a316_imuAccXLgMonChlPerm 0 "CLEARED" 1 "SET";
VAL_ 1009 RCM2_a317_imuAccXLgMonChlTemp 0 "CLEARED" 1 "SET";
VAL_ 1009 RCM2_a318_imuAccYLgMonChlPerm 0 "CLEARED" 1 "SET";
VAL_ 1009 RCM2_a319_imuAccYLgMonChlTemp 0 "CLEARED" 1 "SET";
VAL_ 1009 RCM2_a320_imuAccZLgMonChlPerm 0 "CLEARED" 1 "SET";
VAL_ 1009 RCM2_a321_imuAccZLgMonChlTemp 0 "CLEARED" 1 "SET";
VAL_ 1009 RCM2_a322_imuCalibrationFailed 0 "CLEARED" 1 "SET";
VAL_ 1009 RCM2_a323_imuCalibrationNotDone 0 "CLEARED" 1 "SET";
VAL_ 1009 RCM2_a350_upFrntSnsrLSht2Gnd 0 "CLEARED" 1 "SET";
VAL_ 1009 RCM2_a351_upFrntSnsrLSht2Bat 0 "CLEARED" 1 "SET";
VAL_ 1009 RCM2_a352_upFrntSnsrLOpen 0 "CLEARED" 1 "SET";
VAL_ 1009 RCM2_a353_upFrntSnsrLCrssCoup 0 "CLEARED" 1 "SET";
VAL_ 1009 RCM2_a354_upFrntSnsrLCommErr 0 "CLEARED" 1 "SET";
VAL_ 1009 RCM2_a355_upFrntSnsrLInitTyp 0 "CLEARED" 1 "SET";
VAL_ 1009 RCM2_a356_upFrntSnsrLConfig 0 "CLEARED" 1 "SET";
VAL_ 1009 RCM2_a357_upFrntSnsrLDefect 0 "CLEARED" 1 "SET";
VAL_ 1009 RCM2_a358_upFrntSnsrLSigMon 0 "CLEARED" 1 "SET";
VAL_ 1009 RCM2_a360_upFrntSnsrRSht2Gnd 0 "CLEARED" 1 "SET";
VAL_ 1009 RCM2_a361_upFrntSnsrRSht2Bat 0 "CLEARED" 1 "SET";
VAL_ 1009 RCM2_a362_upFrntSnsrROpen 0 "CLEARED" 1 "SET";
VAL_ 1009 RCM2_a363_upFrntSnsrRCrssCoup 0 "CLEARED" 1 "SET";
VAL_ 1009 RCM2_a364_upFrntSnsrRCommErr 0 "CLEARED" 1 "SET";
VAL_ 1009 RCM2_a365_upFrntSnsrRInitTyp 0 "CLEARED" 1 "SET";
VAL_ 1009 RCM2_a366_upFrntSnsrRConfig 0 "CLEARED" 1 "SET";
VAL_ 1009 RCM2_a367_upFrntSnsrRDefect 0 "CLEARED" 1 "SET";
VAL_ 1009 RCM2_a368_upFrntSnsrRSigMon 0 "CLEARED" 1 "SET";
VAL_ 1009 RCM2_a370_upFrntSnsrMidLSht2Gnd 0 "CLEARED" 1 "SET";
VAL_ 1009 RCM2_a371_upFrntSnsrMidLSht2Bat 0 "CLEARED" 1 "SET";
VAL_ 1009 RCM2_a372_upFrntSnsrMidLOpen 0 "CLEARED" 1 "SET";
VAL_ 1009 RCM2_a373_upFrntSnsrMidLCrssCoup 0 "CLEARED" 1 "SET";
VAL_ 1009 RCM2_a374_upFrntSnsrMidLCommErr 0 "CLEARED" 1 "SET";
VAL_ 1009 RCM2_a375_upFrntSnsrMidLInitTyp 0 "CLEARED" 1 "SET";
VAL_ 1009 RCM2_a376_upFrntSnsrMidLConfig 0 "CLEARED" 1 "SET";
VAL_ 1009 RCM2_a377_upFrntSnsrMidLDefect 0 "CLEARED" 1 "SET";
VAL_ 1009 RCM2_a378_upFrntSnsrMidLSht2Gnd 0 "CLEARED" 1 "SET";
VAL_ 1009 RCM2_a380_upFrntSnsrMidRSht2Gnd 0 "CLEARED" 1 "SET";
VAL_ 1009 RCM2_a381_upFrntSnsrMidRSht2Bat 0 "CLEARED" 1 "SET";
VAL_ 1009 RCM2_a382_upFrntSnsrMidROpen 0 "CLEARED" 1 "SET";
VAL_ 1009 RCM2_a383_upFrntSnsrMidRCrssCoup 0 "CLEARED" 1 "SET";
VAL_ 1009 RCM2_a384_upFrntSnsrMidRCommErr 0 "CLEARED" 1 "SET";
VAL_ 1009 RCM2_a385_upFrntSnsrMidRInitTyp 0 "CLEARED" 1 "SET";
VAL_ 1009 RCM2_a386_upFrntSnsrMidRConfig 0 "CLEARED" 1 "SET";
VAL_ 1009 RCM2_a387_upFrntSnsrMidRDefect 0 "CLEARED" 1 "SET";
VAL_ 1009 RCM2_a388_upFrntSnsrMidRSigMon 0 "CLEARED" 1 "SET";
VAL_ 1009 RCM2_a390_sideAccelBPilLSht2Gnd 0 "CLEARED" 1 "SET";
VAL_ 1009 RCM2_a391_sideAccelBPilLSht2Bat 0 "CLEARED" 1 "SET";
VAL_ 1009 RCM2_a392_sideAccelBPilLOpen 0 "CLEARED" 1 "SET";
VAL_ 1009 RCM2_a393_sideAccelBPilLCLosCoup 0 "CLEARED" 1 "SET";
VAL_ 1009 RCM2_a394_sideAccelBPilLCommErr 0 "CLEARED" 1 "SET";
VAL_ 1009 RCM2_a395_sideAccelBPilLInitTyp 0 "CLEARED" 1 "SET";
VAL_ 1009 RCM2_a396_sideAccelBPilLConfig 0 "CLEARED" 1 "SET";
VAL_ 1009 RCM2_a397_sideAccelBPilLDefect 0 "CLEARED" 1 "SET";
VAL_ 1009 RCM2_a398_sideAccelBPilLSigMon 0 "CLEARED" 1 "SET";
VAL_ 1009 RCM2_a400_sideAccelBPilRSht2Gnd 0 "CLEARED" 1 "SET";
VAL_ 1009 RCM2_a401_sideAccelBPilRSht2Bat 0 "CLEARED" 1 "SET";
VAL_ 1009 RCM2_a402_sideAccelBPilROpen 0 "CLEARED" 1 "SET";
VAL_ 1009 RCM2_a403_sideAccelBPilRCrssCoup 0 "CLEARED" 1 "SET";
VAL_ 1009 RCM2_a404_sideAccelBPilRCommErr 0 "CLEARED" 1 "SET";
VAL_ 1009 RCM2_a405_sideAccelBPilRInitTyp 0 "CLEARED" 1 "SET";
VAL_ 1009 RCM2_a406_sideAccelBPilRConfig 0 "CLEARED" 1 "SET";
VAL_ 1009 RCM2_a407_sideAccelBPilRDefect 0 "CLEARED" 1 "SET";
VAL_ 1009 RCM2_a408_sideAccelBPilRSigMon 0 "CLEARED" 1 "SET";
VAL_ 1009 RCM2_a410_sideAccelCPilLSht2Gnd 0 "CLEARED" 1 "SET";
VAL_ 1009 RCM2_a411_sideAccelCPilLSht2Bat 0 "CLEARED" 1 "SET";
VAL_ 1009 RCM2_a412_sideAccelCPilLOpen 0 "CLEARED" 1 "SET";
VAL_ 1009 RCM2_a413_sideAccelCPilLCrssCoup 0 "CLEARED" 1 "SET";
VAL_ 1009 RCM2_a414_sideAccelCPilLCommErr 0 "CLEARED" 1 "SET";
VAL_ 1009 RCM2_a415_sideAccelCPilLInitTyp 0 "CLEARED" 1 "SET";
VAL_ 1009 RCM2_a416_sideAccelCPilLConfig 0 "CLEARED" 1 "SET";
VAL_ 1009 RCM2_a417_sideAccelCPilLDefect 0 "CLEARED" 1 "SET";
VAL_ 1009 RCM2_a418_sideAccelCPilLSigMon 0 "CLEARED" 1 "SET";
VAL_ 1009 RCM2_a420_sideAccelCPilRSht2Gnd 0 "CLEARED" 1 "SET";
VAL_ 1009 RCM2_a421_sideAccelCPilRSht2Bat 0 "CLEARED" 1 "SET";
VAL_ 1009 RCM2_a422_sideAccelCPilROpen 0 "CLEARED" 1 "SET";
VAL_ 1009 RCM2_a423_sideAccelCPilRCrssCoup 0 "CLEARED" 1 "SET";
VAL_ 1009 RCM2_a424_sideAccelCPilRCommErr 0 "CLEARED" 1 "SET";
VAL_ 1009 RCM2_a425_sideAccelCPilRInitTyp 0 "CLEARED" 1 "SET";
VAL_ 1009 RCM2_a426_sideAccelCPilRConfig 0 "CLEARED" 1 "SET";
VAL_ 1009 RCM2_a427_sideAccelCPilRDefect 0 "CLEARED" 1 "SET";
VAL_ 1009 RCM2_a428_sideAccelCPilRSigMon 0 "CLEARED" 1 "SET";
VAL_ 1009 RCM2_a430_presFrntLDoorSht2Gnd 0 "CLEARED" 1 "SET";
VAL_ 1009 RCM2_a431_presFrntLDoorSht2Bat 0 "CLEARED" 1 "SET";
VAL_ 1009 RCM2_a432_presFrntLDoorOpen 0 "CLEARED" 1 "SET";
VAL_ 1009 RCM2_a433_presFrntLDoorCrssCoup 0 "CLEARED" 1 "SET";
VAL_ 1009 RCM2_a434_presFrntLDoorCommErr 0 "CLEARED" 1 "SET";
VAL_ 1009 RCM2_a435_presFrntLDoorInitTyp 0 "CLEARED" 1 "SET";
VAL_ 1009 RCM2_a436_presFrntLDoorConfig 0 "CLEARED" 1 "SET";
VAL_ 1009 RCM2_a437_presFrntLDoorDefect 0 "CLEARED" 1 "SET";
VAL_ 1009 RCM2_a438_presFrntLDoorSigMon 0 "CLEARED" 1 "SET";
VAL_ 1009 RCM2_a439_presDoorAbsolute1 0 "CLEARED" 1 "SET";
VAL_ 1009 RCM2_a440_presFrntRDoorSht2Gnd 0 "CLEARED" 1 "SET";
VAL_ 1009 RCM2_a441_presFrntRDoorSht2Bat 0 "CLEARED" 1 "SET";
VAL_ 1009 RCM2_a442_presFrntRDoorOpen 0 "CLEARED" 1 "SET";
VAL_ 1009 RCM2_a443_presFrntRDoorCrssCoup 0 "CLEARED" 1 "SET";
VAL_ 1009 RCM2_a444_presFrntRDoorCommErr 0 "CLEARED" 1 "SET";
VAL_ 1009 RCM2_a445_presFrntRDoorInitTyp 0 "CLEARED" 1 "SET";
VAL_ 1009 RCM2_a446_presFrntRDoorConfig 0 "CLEARED" 1 "SET";
VAL_ 1009 RCM2_a447_presFrntRDoorDefect 0 "CLEARED" 1 "SET";
VAL_ 1009 RCM2_a448_presFrntRDoorSigMon 0 "CLEARED" 1 "SET";
VAL_ 1009 RCM2_a449_presDoorAbsolute2 0 "CLEARED" 1 "SET";
VAL_ 1009 RCM2_a450_presPedProLSht2Gnd 0 "CLEARED" 1 "SET";
VAL_ 1009 RCM2_a451_presPedProLSht2Bat 0 "CLEARED" 1 "SET";
VAL_ 1009 RCM2_a452_presPedProLOpen 0 "CLEARED" 1 "SET";
VAL_ 1009 RCM2_a453_presPedProLCrssCoup 0 "CLEARED" 1 "SET";
VAL_ 1009 RCM2_a454_presPedProLCommErr 0 "CLEARED" 1 "SET";
VAL_ 1009 RCM2_a455_presPedProLInitTyp 0 "CLEARED" 1 "SET";
VAL_ 1009 RCM2_a456_presPedProLConfig 0 "CLEARED" 1 "SET";
VAL_ 1009 RCM2_a457_presPedProLDefect 0 "CLEARED" 1 "SET";
VAL_ 1009 RCM2_a458_presPedProLSigMon 0 "CLEARED" 1 "SET";
VAL_ 1009 RCM2_a460_presPedProRSht2Gnd 0 "CLEARED" 1 "SET";
VAL_ 1009 RCM2_a461_presPedProRSht2Bat 0 "CLEARED" 1 "SET";
VAL_ 1009 RCM2_a462_presPedProROpen 0 "CLEARED" 1 "SET";
VAL_ 1009 RCM2_a463_presPedProRCrssCoup 0 "CLEARED" 1 "SET";
VAL_ 1009 RCM2_a464_presPedProRCommErr 0 "CLEARED" 1 "SET";
VAL_ 1009 RCM2_a465_presPedProRInitTyp 0 "CLEARED" 1 "SET";
VAL_ 1009 RCM2_a466_presPedProRConfig 0 "CLEARED" 1 "SET";
VAL_ 1009 RCM2_a467_presPedProRDefect 0 "CLEARED" 1 "SET";
VAL_ 1009 RCM2_a468_presPedProRSigMon 0 "CLEARED" 1 "SET";
VAL_ 1009 RCM2_a469_presPedProAbsolute 0 "CLEARED" 1 "SET";
VAL_ 1009 RCM2_a470_upFrntPedProLSht2Gnd 0 "CLEARED" 1 "SET";
VAL_ 1009 RCM2_a471_upFrntPedProLSht2Bat 0 "CLEARED" 1 "SET";
VAL_ 1009 RCM2_a472_upFrntPedProLOpen 0 "CLEARED" 1 "SET";
VAL_ 1009 RCM2_a473_upFrntPedProLCrssCoup 0 "CLEARED" 1 "SET";
VAL_ 1009 RCM2_a474_upFrntPedProLCommErr 0 "CLEARED" 1 "SET";
VAL_ 1009 RCM2_a475_upFrntPedProLIntTyp 0 "CLEARED" 1 "SET";
VAL_ 1009 RCM2_a476_upFrntPedProLConfig 0 "CLEARED" 1 "SET";
VAL_ 1009 RCM2_a477_upFrntPedProLDefect 0 "CLEARED" 1 "SET";
VAL_ 1009 RCM2_a478_upFrntPedProSht2Gnd 0 "CLEARED" 1 "SET";
VAL_ 1009 RCM2_a480_upFrntPedProRSht2Gnd 0 "CLEARED" 1 "SET";
VAL_ 1009 RCM2_a481_upFrntPedProRSht2Bat 0 "CLEARED" 1 "SET";
VAL_ 1009 RCM2_a482_upFrntPedProROpen 0 "CLEARED" 1 "SET";
VAL_ 1009 RCM2_a483_upFrntPedProRCrssCoup 0 "CLEARED" 1 "SET";
VAL_ 1009 RCM2_a484_upFrntPedProRCommErr 0 "CLEARED" 1 "SET";
VAL_ 1009 RCM2_a485_upFrntPedProRIntTyp 0 "CLEARED" 1 "SET";
VAL_ 1009 RCM2_a486_upFrntPedProRConfig 0 "CLEARED" 1 "SET";
VAL_ 1009 RCM2_a487_upFrntPedProRDefect 0 "CLEARED" 1 "SET";
VAL_ 1009 RCM2_a488_upFrntPedProSht2Gnd 0 "CLEARED" 1 "SET";
VAL_ 1009 RCM2_a550_bucklHallLeftSht2Gnd 0 "CLEARED" 1 "SET";
VAL_ 1009 RCM2_a551_bucklHallLeftSht2Bat 0 "CLEARED" 1 "SET";
VAL_ 1009 RCM2_a552_bucklHallLeftOpen 0 "CLEARED" 1 "SET";
VAL_ 1009 RCM2_a553_bucklHallLeftUndef 0 "CLEARED" 1 "SET";
VAL_ 1009 RCM2_a554_bucklHallLeftCrssCoup 0 "CLEARED" 1 "SET";
VAL_ 1009 RCM2_a555_bucklHallLeftConfig 0 "CLEARED" 1 "SET";
VAL_ 1009 RCM2_a556_bucklHallRightSht2Gnd 0 "CLEARED" 1 "SET";
VAL_ 1009 RCM2_a557_bucklHallRightSht2Bat 0 "CLEARED" 1 "SET";
VAL_ 1009 RCM2_a558_bucklHallRightOpen 0 "CLEARED" 1 "SET";
VAL_ 1009 RCM2_a559_bucklHallRightUndef 0 "CLEARED" 1 "SET";
VAL_ 1009 RCM2_a560_bucklHallRightCrssCoup 0 "CLEARED" 1 "SET";
VAL_ 1009 RCM2_a561_bucklHallRightConfig 0 "CLEARED" 1 "SET";
VAL_ 1009 RCM2_a562_seaTrkPosLeftSht2Gnd 0 "CLEARED" 1 "SET";
VAL_ 1009 RCM2_a563_seaTrkPosLeftShtBat 0 "CLEARED" 1 "SET";
VAL_ 1009 RCM2_a564_seaTrkPosLeftOpen 0 "CLEARED" 1 "SET";
VAL_ 1009 RCM2_a565_seaTrkPosLeftUndefined 0 "CLEARED" 1 "SET";
VAL_ 1009 RCM2_a566_seaTrkPosLeftCrssCoup 0 "CLEARED" 1 "SET";
VAL_ 1009 RCM2_a567_seaTrkPosLeftConfig 0 "CLEARED" 1 "SET";
VAL_ 1009 RCM2_a568_occPROSSht2Gnd 0 "CLEARED" 1 "SET";
VAL_ 1009 RCM2_a569_occPROSSht2Bat 0 "CLEARED" 1 "SET";
VAL_ 1009 RCM2_a570_occPROSOpen 0 "CLEARED" 1 "SET";
VAL_ 1009 RCM2_a571_occPROSUndef 0 "CLEARED" 1 "SET";
VAL_ 1009 RCM2_a572_occPROSCrssCoup 0 "CLEARED" 1 "SET";
VAL_ 1009 RCM2_a573_occPROSConfig 0 "CLEARED" 1 "SET";
VAL_ 1009 RCM2_a581_sbrRearNetworkSht2Gnd 0 "CLEARED" 1 "SET";
VAL_ 1009 RCM2_a582_sbrRearNetworkConfig 0 "CLEARED" 1 "SET";
VAL_ 1009 RCM2_a600_comCANinternalTimeout 0 "CLEARED" 1 "SET";
VAL_ 1009 RCM2_a601_comChassisCANInit 0 "CLEARED" 1 "SET";
VAL_ 1009 RCM2_a602_comChassisCANBusOff 0 "CLEARED" 1 "SET";
VAL_ 1009 RCM2_a603_comPARTYCANInit 0 "CLEARED" 1 "SET";
VAL_ 1009 RCM2_a604_comPARTYCANBusOff 0 "CLEARED" 1 "SET";
VAL_ 1009 RCM2_a605_comStwAngStatMIA 0 "CLEARED" 1 "SET";
VAL_ 1009 RCM2_a606_comStwAngStatChkSm 0 "CLEARED" 1 "SET";
VAL_ 1009 RCM2_a607_comStwAngStatCntr 0 "CLEARED" 1 "SET";
VAL_ 1009 RCM2_a608_comDItorque1MIA 0 "CLEARED" 1 "SET";
VAL_ 1009 RCM2_a609_comDItorque1ChkSm 0 "CLEARED" 1 "SET";
VAL_ 1009 RCM2_a610_comDItorque1Cntr 0 "CLEARED" 1 "SET";
VAL_ 1009 RCM2_a611_comDItorque2MIA 0 "CLEARED" 1 "SET";
VAL_ 1009 RCM2_a612_comDItorque2ChkSm 0 "CLEARED" 1 "SET";
VAL_ 1009 RCM2_a613_comDItorque2Cntr 0 "CLEARED" 1 "SET";
VAL_ 1009 RCM2_a614_comESP135MIA 0 "CLEARED" 1 "SET";
VAL_ 1009 RCM2_a615_comESP135ChkSm 0 "CLEARED" 1 "SET";
VAL_ 1009 RCM2_a616_comESP135Cntr 0 "CLEARED" 1 "SET";
VAL_ 1009 RCM2_a617_comESP145MIA 0 "CLEARED" 1 "SET";
VAL_ 1009 RCM2_a618_comESP145ChkSm 0 "CLEARED" 1 "SET";
VAL_ 1009 RCM2_a619_comESP145Cntr 0 "CLEARED" 1 "SET";
VAL_ 1009 RCM2_a620_comInvalidVehicleSpeed 0 "CLEARED" 1 "SET";
VAL_ 1009 RCM2_a621_comESPBMIA 0 "CLEARED" 1 "SET";
VAL_ 1009 RCM2_a622_comESPBChkSm 0 "CLEARED" 1 "SET";
VAL_ 1009 RCM2_a623_comESPBCntr 0 "CLEARED" 1 "SET";
VAL_ 1009 RCM2_a624_comESPCMIA 0 "CLEARED" 1 "SET";
VAL_ 1009 RCM2_a625_comESPCChkSm 0 "CLEARED" 1 "SET";
VAL_ 1009 RCM2_a626_comESPCCntr 0 "CLEARED" 1 "SET";
VAL_ 1009 RCM2_a627_comEPBStatusMIA 0 "CLEARED" 1 "SET";
VAL_ 1009 RCM2_a628_comEPBStatusChkSm 0 "CLEARED" 1 "SET";
VAL_ 1009 RCM2_a629_comEPBStatusCntr 0 "CLEARED" 1 "SET";
VAL_ 1009 RCM2_a630_comGTWACSMIA 0 "CLEARED" 1 "SET";
VAL_ 1009 RCM2_a631_comGTWACSChkSm 0 "CLEARED" 1 "SET";
VAL_ 1009 RCM2_a632_comGTWACSCntr 0 "CLEARED" 1 "SET";
VAL_ 1009 RCM2_a633_comOCS1PMIA 0 "CLEARED" 1 "SET";
VAL_ 1009 RCM2_a634_comOCS1PChkSm 0 "CLEARED" 1 "SET";
VAL_ 1009 RCM2_a635_comOCS1PCntr 0 "CLEARED" 1 "SET";
VAL_ 1009 RCM2_a636_ocsFaulted 0 "CLEARED" 1 "SET";
VAL_ 1009 RCM2_a637_ocsUnknown 0 "CLEARED" 1 "SET";
VAL_ 1009 RCM2_a638_comGTWodoMIA 0 "CLEARED" 1 "SET";
VAL_ 1009 RCM2_a639_comGTWCarStateMIA 0 "CLEARED" 1 "SET";
VAL_ 1009 RCM2_a640_comTPMSStatusCMIA 0 "CLEARED" 1 "SET";
VAL_ 1009 RCM2_a641_comGTWCarConfigMIA 0 "CLEARED" 1 "SET";
VAL_ 1009 RCM2_a642_comVINmessageMIA 0 "CLEARED" 1 "SET";
VAL_ 1009 RCM2_a643_comDASSafetyFrntMIA 0 "CLEARED" 1 "SET";
VAL_ 1009 RCM2_a644_comDASSafetyFrntChkSm 0 "CLEARED" 1 "SET";
VAL_ 1009 RCM2_a645_comDASSafetyFrntCntr 0 "CLEARED" 1 "SET";
VAL_ 1009 RCM2_a646_comDIstateMIA 0 "CLEARED" 1 "SET";
VAL_ 1009 RCM2_a647_comDIstateChkSm 0 "CLEARED" 1 "SET";
VAL_ 1009 RCM2_a648_comDIstateCntr 0 "CLEARED" 1 "SET";
VAL_ 1009 RCM2_a649_comDIstate2MIA 0 "CLEARED" 1 "SET";
VAL_ 1009 RCM2_a650_comDIstate2ChkSm 0 "CLEARED" 1 "SET";
VAL_ 1009 RCM2_a651_comDIstate2Cntr 0 "CLEARED" 1 "SET";
VAL_ 1009 RCM2_a652_ambientTempFaulted 0 "CLEARED" 1 "SET";
VAL_ 1009 RCM2_a653_comGTWESP1MIA 0 "CLEARED" 1 "SET";
VAL_ 1009 RCM2_a654_comGTWESP1ChkSm 0 "CLEARED" 1 "SET";
VAL_ 1009 RCM2_a655_comGTWESP1Cntr 0 "CLEARED" 1 "SET";
VAL_ 1009 RCM2_a750_linInternalTimeout 0 "CLEARED" 1 "SET";
VAL_ 1009 RCM2_a800_cfgMissingCalibration 0 "CLEARED" 1 "SET";
VAL_ 1009 RCM2_a801_cfgImplausConfig 0 "CLEARED" 1 "SET";
VAL_ 1009 RCM2_a802_cfgInvalidConfig 0 "CLEARED" 1 "SET";
VAL_ 1009 RCM2_a803_cfgNotConfigured 0 "CLEARED" 1 "SET";
VAL_ 1009 RCM2_a804_cfgNotProgrammed 0 "CLEARED" 1 "SET";
VAL_ 1009 RCM2_a805_cfgPedProNotProgrammed 0 "CLEARED" 1 "SET";
VAL_ 1009 RCM2_a806_cfgCrashCalPNmissing 0 "CLEARED" 1 "SET";
VAL_ 1009 RCM2_a807_cfgExternalCRCError 0 "CLEARED" 1 "SET";
VAL_ 1009 RCM2_a808_cfgInvalParamLayoutID 0 "CLEARED" 1 "SET";
VAL_ 1009 RCM2_a809_cfgInvalParamTransID 0 "CLEARED" 1 "SET";
VAL_ 1009 RCM2_a810_cfgAlgoVerifySnsrID 0 "CLEARED" 1 "SET";
VAL_ 1009 RCM2_a811_cfgConfigDataInconsist 0 "CLEARED" 1 "SET";
VAL_ 1009 RCM2_a812_swVersionWrong 0 "CLEARED" 1 "SET";
VAL_ 1009 RCM2_a813_vinNotProgrammed 0 "CLEARED" 1 "SET";
VAL_ 1009 RCM2_a850_internalFault_001 0 "CLEARED" 1 "SET";
VAL_ 1009 RCM2_a851_internalFault_002 0 "CLEARED" 1 "SET";
VAL_ 1009 RCM2_a852_internalFault_003 0 "CLEARED" 1 "SET";
VAL_ 1009 RCM2_a853_internalFault_004 0 "CLEARED" 1 "SET";
VAL_ 1009 RCM2_a854_internalFault_005 0 "CLEARED" 1 "SET";
VAL_ 1009 RCM2_a855_internalFault_006 0 "CLEARED" 1 "SET";
VAL_ 1009 RCM2_a856_internalFault_007 0 "CLEARED" 1 "SET";
VAL_ 1009 RCM2_a857_internalFault_008 0 "CLEARED" 1 "SET";
VAL_ 1009 RCM2_a858_internalFault_009 0 "CLEARED" 1 "SET";
VAL_ 1009 RCM2_a859_internalFault_010 0 "CLEARED" 1 "SET";
VAL_ 1009 RCM2_a860_internalFault_011 0 "CLEARED" 1 "SET";
VAL_ 1009 RCM2_a861_internalFault_012 0 "CLEARED" 1 "SET";
VAL_ 1009 RCM2_a862_internalFault_013 0 "CLEARED" 1 "SET";
VAL_ 1009 RCM2_a863_internalFault_014 0 "CLEARED" 1 "SET";
VAL_ 1009 RCM2_a864_internalFault_015 0 "CLEARED" 1 "SET";
VAL_ 1009 RCM2_a865_internalFault_016 0 "CLEARED" 1 "SET";
VAL_ 1009 RCM2_a866_internalFault_017 0 "CLEARED" 1 "SET";
VAL_ 1009 RCM2_a867_internalFault_018 0 "CLEARED" 1 "SET";
VAL_ 1009 RCM2_a868_internalFault_019 0 "CLEARED" 1 "SET";
VAL_ 1009 RCM2_a869_internalFault_020 0 "CLEARED" 1 "SET";
VAL_ 1009 RCM2_a870_internalFault_021 0 "CLEARED" 1 "SET";
VAL_ 1009 RCM2_a871_internalFault_022 0 "CLEARED" 1 "SET";
VAL_ 1009 RCM2_a872_internalFault_023 0 "CLEARED" 1 "SET";
VAL_ 1009 RCM2_a873_internalFault_024 0 "CLEARED" 1 "SET";
VAL_ 1009 RCM2_a874_internalFault_025 0 "CLEARED" 1 "SET";
VAL_ 1009 RCM2_a875_internalFault_026 0 "CLEARED" 1 "SET";
VAL_ 1009 RCM2_a876_internalFault_027 0 "CLEARED" 1 "SET";
VAL_ 1009 RCM2_a877_internalFault_028 0 "CLEARED" 1 "SET";
VAL_ 1009 RCM2_a878_internalFault_029 0 "CLEARED" 1 "SET";
VAL_ 1009 RCM2_a879_internalFault_030 0 "CLEARED" 1 "SET";
VAL_ 1009 RCM2_a880_internalFault_031 0 "CLEARED" 1 "SET";
VAL_ 1009 RCM2_a881_internalFault_032 0 "CLEARED" 1 "SET";
VAL_ 1009 RCM2_a882_internalFault_033 0 "CLEARED" 1 "SET";
VAL_ 1009 RCM2_a883_internalFault_034 0 "CLEARED" 1 "SET";
VAL_ 1009 RCM2_a884_internalFault_035 0 "CLEARED" 1 "SET";
VAL_ 1009 RCM2_a885_internalFault_036 0 "CLEARED" 1 "SET";
VAL_ 1009 RCM2_a886_internalFault_037 0 "CLEARED" 1 "SET";
VAL_ 1009 RCM2_a887_internalFault_038 0 "CLEARED" 1 "SET";
VAL_ 1009 RCM2_a888_internalFault_039 0 "CLEARED" 1 "SET";
VAL_ 1009 RCM2_a889_internalFault_040 0 "CLEARED" 1 "SET";
VAL_ 1009 RCM2_a890_internalFault_041 0 "CLEARED" 1 "SET";
VAL_ 1009 RCM2_a891_internalFault_042 0 "CLEARED" 1 "SET";
VAL_ 1009 RCM2_a892_internalFault_043 0 "CLEARED" 1 "SET";
VAL_ 1009 RCM2_a893_internalFault_044 0 "CLEARED" 1 "SET";
VAL_ 1009 RCM2_a894_internalFault_045 0 "CLEARED" 1 "SET";
VAL_ 1009 RCM2_a895_internalFault_046 0 "CLEARED" 1 "SET";
VAL_ 1009 RCM2_a896_internalFault_047 0 "CLEARED" 1 "SET";
VAL_ 1009 RCM2_a897_internalFault_048 0 "CLEARED" 1 "SET";
VAL_ 1009 RCM2_a898_internalFault_049 0 "CLEARED" 1 "SET";
VAL_ 1009 RCM2_a899_internalFault_050 0 "CLEARED" 1 "SET";
VAL_ 1009 RCM2_a900_internalFault_051 0 "CLEARED" 1 "SET";
VAL_ 1009 RCM2_a901_internalFault_052 0 "CLEARED" 1 "SET";
VAL_ 1009 RCM2_a902_internalFault_053 0 "CLEARED" 1 "SET";
VAL_ 1009 RCM2_a903_internalFault_054 0 "CLEARED" 1 "SET";
VAL_ 1009 RCM2_a904_internalFault_055 0 "CLEARED" 1 "SET";
VAL_ 1009 RCM2_a905_internalFault_056 0 "CLEARED" 1 "SET";
VAL_ 1009 RCM2_a906_internalFault_057 0 "CLEARED" 1 "SET";
VAL_ 1009 RCM2_a907_internalFault_058 0 "CLEARED" 1 "SET";
VAL_ 1009 RCM2_a908_internalFault_059 0 "CLEARED" 1 "SET";
VAL_ 1009 RCM2_a909_internalFault_060 0 "CLEARED" 1 "SET";
VAL_ 1009 RCM2_a910_internalFault_061 0 "CLEARED" 1 "SET";
VAL_ 1009 RCM2_a911_internalFault_062 0 "CLEARED" 1 "SET";
VAL_ 1009 RCM2_a912_internalFault_063 0 "CLEARED" 1 "SET";
VAL_ 1009 RCM2_a913_internalFault_064 0 "CLEARED" 1 "SET";
VAL_ 1009 RCM2_a914_internalFault_065 0 "CLEARED" 1 "SET";
VAL_ 1009 RCM2_a915_internalFault_066 0 "CLEARED" 1 "SET";
VAL_ 1009 RCM2_a916_internalFault_067 0 "CLEARED" 1 "SET";
VAL_ 1009 RCM2_a917_internalFault_068 0 "CLEARED" 1 "SET";
VAL_ 1009 RCM2_a918_internalFault_069 0 "CLEARED" 1 "SET";
VAL_ 1009 RCM2_a919_internalFault_070 0 "CLEARED" 1 "SET";
VAL_ 1009 RCM2_a920_internalFault_071 0 "CLEARED" 1 "SET";
VAL_ 1009 RCM2_a921_internalFault_072 0 "CLEARED" 1 "SET";
VAL_ 1009 RCM2_a922_internalFault_073 0 "CLEARED" 1 "SET";
VAL_ 1009 RCM2_a923_internalFault_074 0 "CLEARED" 1 "SET";
VAL_ 1009 RCM2_a924_internalFault_075 0 "CLEARED" 1 "SET";
VAL_ 1009 RCM2_a925_internalFault_076 0 "CLEARED" 1 "SET";
VAL_ 1009 RCM2_a926_internalFault_077 0 "CLEARED" 1 "SET";
VAL_ 1009 RCM2_a927_internalFault_078 0 "CLEARED" 1 "SET";
VAL_ 1009 RCM2_a928_internalFault_079 0 "CLEARED" 1 "SET";
VAL_ 1009 RCM2_a929_internalFault_080 0 "CLEARED" 1 "SET";
VAL_ 1009 RCM2_a930_internalFault_081 0 "CLEARED" 1 "SET";
VAL_ 1009 RCM2_a931_internalFault_082 0 "CLEARED" 1 "SET";
VAL_ 1009 RCM2_a932_internalFault_083 0 "CLEARED" 1 "SET";
VAL_ 1009 RCM2_a933_internalFault_084 0 "CLEARED" 1 "SET";
VAL_ 1009 RCM2_a934_internalFault_085 0 "CLEARED" 1 "SET";
VAL_ 1009 RCM2_a935_internalFault_086 0 "CLEARED" 1 "SET";
VAL_ 1009 RCM2_a936_internalFault_087 0 "CLEARED" 1 "SET";
VAL_ 1009 RCM2_a937_internalFault_088 0 "CLEARED" 1 "SET";
VAL_ 1009 RCM2_a938_internalFault_089 0 "CLEARED" 1 "SET";
VAL_ 1009 RCM2_a939_internalFault_090 0 "CLEARED" 1 "SET";
VAL_ 1009 RCM2_a940_internalFault_091 0 "CLEARED" 1 "SET";
VAL_ 1009 RCM2_a941_internalFault_092 0 "CLEARED" 1 "SET";
VAL_ 1009 RCM2_a942_internalFault_093 0 "CLEARED" 1 "SET";
VAL_ 1009 RCM2_a943_internalFault_094 0 "CLEARED" 1 "SET";
VAL_ 1009 RCM2_a944_internalFault_095 0 "CLEARED" 1 "SET";
VAL_ 1009 RCM2_a945_internalFault_096 0 "CLEARED" 1 "SET";
VAL_ 1009 RCM2_a946_internalFault_097 0 "CLEARED" 1 "SET";
VAL_ 1009 RCM2_a947_internalFault_098 0 "CLEARED" 1 "SET";
VAL_ 1009 RCM2_a948_internalFault_099 0 "CLEARED" 1 "SET";
VAL_ 1009 RCM2_a949_internalFault_100 0 "CLEARED" 1 "SET";
VAL_ 1009 RCM2_a950_internalFault_101 0 "CLEARED" 1 "SET";
VAL_ 1009 RCM2_a951_internalFault_102 0 "CLEARED" 1 "SET";
VAL_ 1009 RCM2_a952_internalFault_103 0 "CLEARED" 1 "SET";
VAL_ 1009 RCM2_a953_internalFault_104 0 "CLEARED" 1 "SET";
VAL_ 1009 RCM2_a954_internalFault_105 0 "CLEARED" 1 "SET";
VAL_ 1009 RCM2_a955_internalFault_106 0 "CLEARED" 1 "SET";
VAL_ 1009 RCM2_a956_internalFault_107 0 "CLEARED" 1 "SET";
VAL_ 1009 RCM2_a957_internalFault_108 0 "CLEARED" 1 "SET";
VAL_ 1009 RCM2_a958_internalFault_109 0 "CLEARED" 1 "SET";
VAL_ 1009 RCM2_a959_internalFault_110 0 "CLEARED" 1 "SET";
VAL_ 1009 RCM2_a960_internalFault_111 0 "CLEARED" 1 "SET";
VAL_ 1009 RCM2_a961_internalFault_112 0 "CLEARED" 1 "SET";
VAL_ 1009 RCM2_a962_internalFault_113 0 "CLEARED" 1 "SET";
VAL_ 1009 RCM2_a963_internalFault_114 0 "CLEARED" 1 "SET";
VAL_ 1009 RCM2_a964_internalFault_115 0 "CLEARED" 1 "SET";
VAL_ 1009 RCM2_a965_internalFault_116 0 "CLEARED" 1 "SET";
VAL_ 1009 RCM2_a966_internalFault_117 0 "CLEARED" 1 "SET";
VAL_ 1009 RCM2_a967_internalFault_118 0 "CLEARED" 1 "SET";
VAL_ 1009 RCM2_a968_internalFault_119 0 "CLEARED" 1 "SET";
VAL_ 1009 RCM2_a969_internalFault_120 0 "CLEARED" 1 "SET";
VAL_ 1009 RCM2_a970_internalFault_121 0 "CLEARED" 1 "SET";
VAL_ 1009 RCM2_a971_internalFault_122 0 "CLEARED" 1 "SET";
VAL_ 1009 RCM2_a972_internalFault_123 0 "CLEARED" 1 "SET";
VAL_ 1009 RCM2_a973_internalFault_124 0 "CLEARED" 1 "SET";
VAL_ 1009 RCM2_a974_internalFault_125 0 "CLEARED" 1 "SET";
VAL_ 1009 RCM2_a975_internalFault_126 0 "CLEARED" 1 "SET";
VAL_ 1009 RCM2_a976_internalFault_127 0 "CLEARED" 1 "SET";
VAL_ 1009 RCM2_a977_internalFault_128 0 "CLEARED" 1 "SET";
VAL_ 1009 RCM2_a978_internalFault_129 0 "CLEARED" 1 "SET";
VAL_ 1009 RCM2_a979_internalFault_130 0 "CLEARED" 1 "SET";
VAL_ 1009 RCM2_a980_internalFault_131 0 "CLEARED" 1 "SET";
VAL_ 1009 RCM2_a981_internalFault_132 0 "CLEARED" 1 "SET";
VAL_ 1009 RCM2_a982_internalFault_133 0 "CLEARED" 1 "SET";
VAL_ 1009 RCM2_a983_internalFault_134 0 "CLEARED" 1 "SET";
VAL_ 1009 RCM2_a984_internalFault_135 0 "CLEARED" 1 "SET";
VAL_ 1009 RCM2_a985_internalFault_136 0 "CLEARED" 1 "SET";
VAL_ 1009 RCM2_a986_internalFault_137 0 "CLEARED" 1 "SET";
VAL_ 1009 RCM2_a987_internalFault_138 0 "CLEARED" 1 "SET";
VAL_ 1009 RCM2_a988_internalFault_139 0 "CLEARED" 1 "SET";
VAL_ 1009 RCM2_a989_internalFault_140 0 "CLEARED" 1 "SET";
VAL_ 1009 RCM2_a990_internalFault_141 0 "CLEARED" 1 "SET";

VAL_ 29 RCM_chargerCrash 0 "INACTIVE" 1 "ACTIVE" 2 "UNUSED";
VAL_ 29 RCM_crashSeverity 0 "PRETENSIONER" 1 "FIRST_STAGE" 2 "SECOND_STAGE" 3 "PEDPRO_EVENT_ONLY";
VAL_ 29 RCM_frontCrash 0 "INACTIVE" 1 "ACTIVE" 2 "UNUSED";
VAL_ 29 RCM_leftSideCrash 0 "INACTIVE" 1 "ACTIVE" 2 "UNUSED";
VAL_ 29 RCM_pedProEvent 0 "INACTIVE" 1 "ACTIVE" 2 "UNUSED";
VAL_ 29 RCM_rearCrash 0 "INACTIVE" 1 "ACTIVE" 2 "UNUSED";
VAL_ 29 RCM_rightSideCrash 0 "INACTIVE" 1 "ACTIVE" 2 "UNUSED";
VAL_ 29 RCM_rollOverCrash 0 "INACTIVE" 1 "ACTIVE" 2 "UNUSED";
